VERSION ""

NS_ :

BS_:

BU_: SOBDMB_AWDC BCMC_CPDB BECMB_EPM PACM GWM _delete BCM ACCM DCDC_HEV GENERIC TSTR

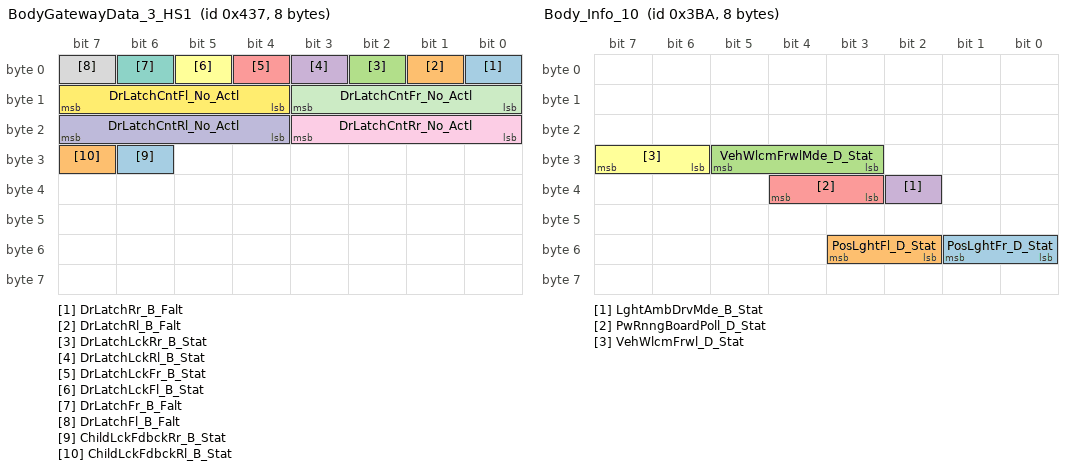
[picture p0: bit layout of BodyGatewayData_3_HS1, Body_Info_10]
BO_ 1079 BodyGatewayData_3_HS1: 8 GWM
 SG_ DrLatchRr_B_Falt : 0|1@0+ (1,0) [0|1] "SED"  BCM
 SG_ DrLatchRl_B_Falt : 1|1@0+ (1,0) [0|1] "SED"  BCM
 SG_ DrLatchLckRr_B_Stat : 2|1@0+ (1,0) [0|1] "SED"  BCM
 SG_ DrLatchLckRl_B_Stat : 3|1@0+ (1,0) [0|1] "SED"  BCM
 SG_ DrLatchLckFr_B_Stat : 4|1@0+ (1,0) [0|1] "SED"  BCM
 SG_ DrLatchLckFl_B_Stat : 5|1@0+ (1,0) [0|1] "SED"  BCM
 SG_ DrLatchFr_B_Falt : 6|1@0+ (1,0) [0|1] "SED"  BCM
 SG_ DrLatchFl_B_Falt : 7|1@0+ (1,0) [0|1] "SED"  BCM
 SG_ DrLatchCntRr_No_Actl : 19|4@0+ (1,0) [0|15] "unitless"  BCM
 SG_ DrLatchCntRl_No_Actl : 23|4@0+ (1,0) [0|15] "unitless"  BCM
 SG_ DrLatchCntFr_No_Actl : 11|4@0+ (1,0) [0|15] "unitless"  BCM
 SG_ DrLatchCntFl_No_Actl : 15|4@0+ (1,0) [0|15] "unitless"  BCM
 SG_ ChildLckFdbckRr_B_Stat : 30|1@0+ (1,0) [0|1] "SED"  BCM
 SG_ ChildLckFdbckRl_B_Stat : 31|1@0+ (1,0) [0|1] "SED"  BCM

BO_ 954 Body_Info_10: 8 BCM
 SG_ PosLghtFr_D_Stat : 49|2@0+ (1,0) [0|3] "SED"  GWM
 SG_ PosLghtFl_D_Stat : 51|2@0+ (1,0) [0|3] "SED"  GWM
 SG_ VehWlcmFrwlMde_D_Stat : 29|3@0+ (1,0) [0|7] "SED"  GWM
 SG_ LghtAmbDrvMde_B_Stat : 34|1@0+ (1,0) [0|1] "SED"  GWM
 SG_ PwRnngBoardPoll_D_Stat : 36|2@0+ (1,0) [0|3] "SED"  GWM
 SG_ VehWlcmFrwl_D_Stat : 31|2@0+ (1,0) [0|3] "SED"  GWM

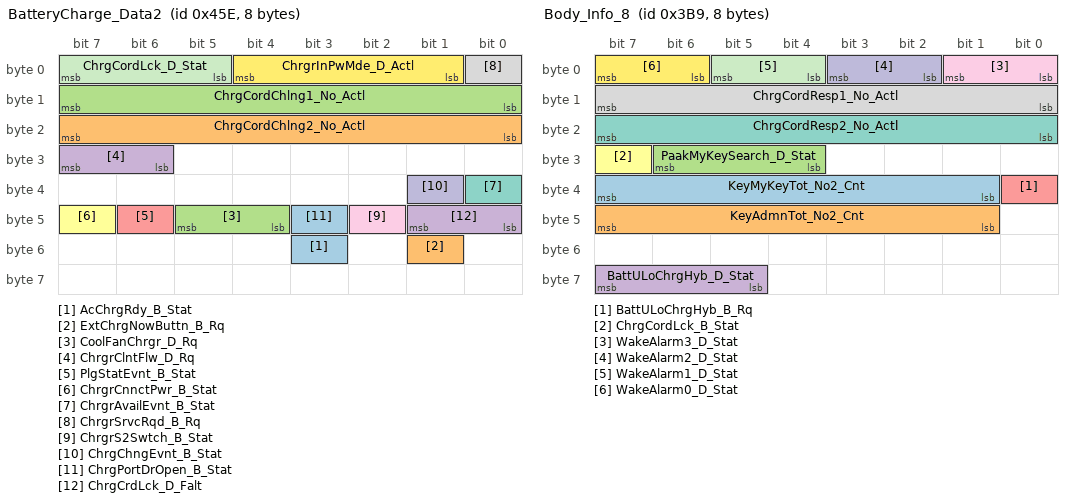
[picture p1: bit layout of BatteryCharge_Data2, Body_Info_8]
BO_ 1118 BatteryCharge_Data2: 8 GWM
 SG_ AcChrgRdy_B_Stat : 51|1@0+ (1,0) [0|1] "SED" Vector__XXX
 SG_ ExtChrgNowButtn_B_Rq : 49|1@0+ (1,0) [0|1] "SED" Vector__XXX
 SG_ CoolFanChrgr_D_Rq : 45|2@0+ (1,0) [0|3] "SED" Vector__XXX
 SG_ ChrgrClntFlw_D_Rq : 31|2@0+ (1,0) [0|3] "SED"  SOBDMB_AWDC
 SG_ PlgStatEvnt_B_Stat : 46|1@0+ (1,0) [0|1] "SED"  DCDC_HEV
 SG_ ChrgrCnnctPwr_B_Stat : 47|1@0+ (1,0) [0|1] "SED" Vector__XXX
 SG_ ChrgrAvailEvnt_B_Stat : 32|1@0+ (1,0) [0|1] "SED"  DCDC_HEV
 SG_ ChrgrSrvcRqd_B_Rq : 0|1@0+ (1,0) [0|1] "SED" Vector__XXX
 SG_ ChrgrS2Swtch_B_Stat : 42|1@0+ (1,0) [0|1] "SED" Vector__XXX
 SG_ ChrgChngEvnt_B_Stat : 33|1@0+ (1,0) [0|1] "SED"  DCDC_HEV
 SG_ ChrgCordLck_D_Stat : 7|3@0+ (1,0) [0|7] "SED" Vector__XXX
 SG_ ChrgrInPwMde_D_Actl : 4|4@0+ (1,0) [0|15] "SED" Vector__XXX
 SG_ ChrgPortDrOpen_B_Stat : 43|1@0+ (1,0) [0|1] "SED" Vector__XXX
 SG_ ChrgCordChlng2_No_Actl : 23|8@0+ (1,0) [0|255] "unitless"  BCM
 SG_ ChrgCordChlng1_No_Actl : 15|8@0+ (1,0) [0|255] "unitless"  BCM
 SG_ ChrgCrdLck_D_Falt : 41|2@0+ (1,0) [0|3] "SED" Vector__XXX

BO_ 953 Body_Info_8: 8 BCM
 SG_ KeyMyKeyTot_No2_Cnt : 39|7@0+ (1,0) [0|127] "unitless"  GWM
 SG_ KeyAdmnTot_No2_Cnt : 47|7@0+ (1,0) [0|127] "unitless"  GWM
 SG_ PaakMyKeySearch_D_Stat : 30|3@0+ (1,0) [0|7] "SED"  GWM
 SG_ BattULoChrgHyb_D_Stat : 63|3@0+ (1,0) [0|7] "SED"  GWM
 SG_ BattULoChrgHyb_B_Rq : 32|1@0+ (1,0) [0|1] "SED"  GWM
 SG_ ChrgCordLck_B_Stat : 31|1@0+ (1,0) [0|1] "SED"  GWM
 SG_ ChrgCordResp2_No_Actl : 23|8@0+ (1,0) [0|255] "unitless"  GWM
 SG_ ChrgCordResp1_No_Actl : 15|8@0+ (1,0) [0|255] "unitless"  GWM
 SG_ WakeAlarm3_D_Stat : 1|2@0+ (1,0) [0|3] "SED"  GWM,GENERIC
 SG_ WakeAlarm2_D_Stat : 3|2@0+ (1,0) [0|3] "SED"  GWM,GENERIC
 SG_ WakeAlarm1_D_Stat : 5|2@0+ (1,0) [0|3] "SED"  GWM,GENERIC
 SG_ WakeAlarm0_D_Stat : 7|2@0+ (1,0) [0|3] "SED"  GWM

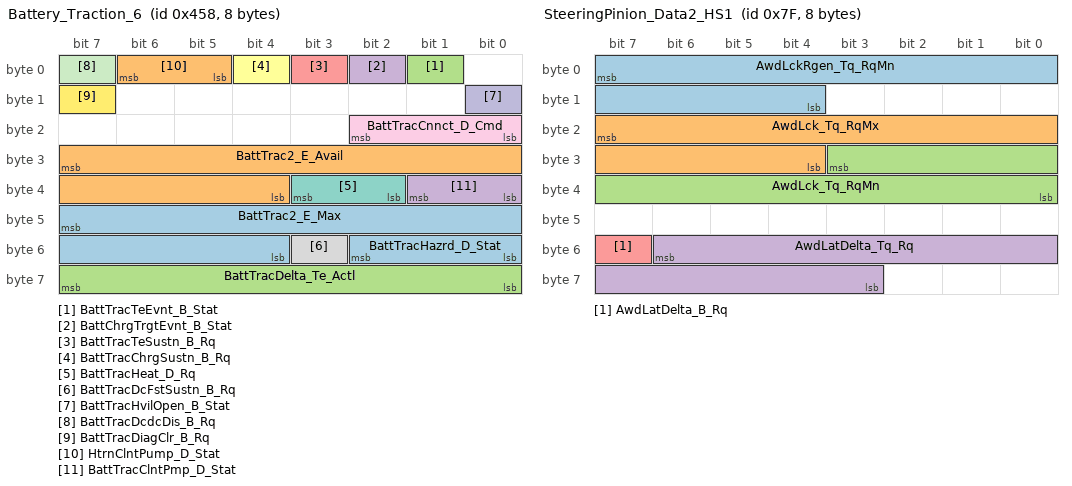
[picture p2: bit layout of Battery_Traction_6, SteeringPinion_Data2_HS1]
BO_ 1112 Battery_Traction_6: 8 GWM
 SG_ BattTrac2_E_Max : 47|12@0+ (50,0) [0|204650] "watt*hour" Vector__XXX
 SG_ BattTrac2_E_Avail : 31|12@0+ (50,0) [0|204650] "watt*hour" Vector__XXX
 SG_ BattTracTeEvnt_B_Stat : 1|1@0+ (1,0) [0|1] "SED"  DCDC_HEV
 SG_ BattChrgTrgtEvnt_B_Stat : 2|1@0+ (1,0) [0|1] "SED"  DCDC_HEV
 SG_ BattTracTeSustn_B_Rq : 3|1@0+ (1,0) [0|1] "SED"  BCM
 SG_ BattTracChrgSustn_B_Rq : 4|1@0+ (1,0) [0|1] "SED"  DCDC_HEV,BCMC_CPDB,BCM
 SG_ BattTracHeat_D_Rq : 35|2@0+ (1,0) [0|3] "SED" Vector__XXX
 SG_ BattTracDcFstSustn_B_Rq : 51|1@0+ (1,0) [0|1] "SED" Vector__XXX
 SG_ BattTracCnnct_D_Cmd : 18|3@0+ (1,0) [0|7] "SED"  SOBDMB_AWDC
 SG_ BattTracHvilOpen_B_Stat : 8|1@0+ (1,0) [0|1] "SED" Vector__XXX
 SG_ BattTracDcdcDis_B_Rq : 7|1@0+ (1,0) [0|1] "SED" Vector__XXX
 SG_ BattTracDiagClr_B_Rq : 15|1@0+ (1,0) [0|1] "SED" Vector__XXX
 SG_ BattTracHazrd_D_Stat : 50|3@0+ (1,0) [0|7] "SED" Vector__XXX
 SG_ HtrnClntPump_D_Stat : 6|2@0+ (1,0) [0|3] "SED"  DCDC_HEV
 SG_ BattTracDelta_Te_Actl : 63|8@0+ (0.5,-60) [-60|66.5] "degC" Vector__XXX
 SG_ BattTracClntPmp_D_Stat : 33|2@0+ (1,0) [0|3] "SED" Vector__XXX

BO_ 1144 MHT_EV_Wakeup: 8 GWM
 SG_ AwdLckMde_D_Stat : 59|3@0+ (1,0) [0|7] "SED" Vector__XXX
 SG_ BattTracCool_B_Actl : 60|1@0+ (1,0) [0|1] "SED"  GENERIC
 SG_ BattChrgTrgtSoC_D_Rq : 35|3@0+ (1,0) [0|7] "Percent" Vector__XXX
 SG_ PreCondBatt_B_Actl : 32|1@0+ (1,0) [0|1] "SED" Vector__XXX
 SG_ CabnEvapSovFront_B_Rq : 38|1@0+ (1,0) [0|1] "SED"  BCMC_CPDB
 SG_ HeatCoreSovRear_B_Rq : 36|1@0+ (1,0) [0|1] "SED" Vector__XXX
 SG_ BattChlrSov_B_Rq : 39|1@0+ (1,0) [0|1] "SED"  BCMC_CPDB
 SG_ CabnEvapSovRear_B_Rq : 37|1@0+ (1,0) [0|1] "SED" Vector__XXX
 SG_ BrkAppl_D_RqPt : 25|2@0+ (1,0) [0|3] "SED" Vector__XXX
 SG_ BattClntVlvOvrrd_D_Rq : 31|2@0+ (1,0) [0|3] "SED" Vector__XXX
 SG_ BattTracChillerOn_B_Rq : 27|1@0+ (1,0) [0|1] "SED" Vector__XXX
 SG_ BattTracChiller_D_Stat : 29|2@0+ (1,0) [0|3] "SED" Vector__XXX
 SG_ FstChrgCmplt_T_Est : 41|10@0+ (1,0) [0|1023] "minute" Vector__XXX
 SG_ ULoBattTrnsfrSustn_B_Rq : 43|1@0+ (1,0) [0|1] "SED"  BCM,DCDC_HEV
 SG_ ULoBattTransfer_D_Stat : 46|3@0+ (1,0) [0|7] "SED"  BCM
 SG_ HtrnDcdcDis_B_Rq : 26|1@0+ (1,0) [0|1] "SED" Vector__XXX
 SG_ HtrnCnnctPwr_B_Stat : 16|1@0+ (1,0) [0|1] "SED" Vector__XXX
 SG_ PtcHtr_D_Stat : 18|2@0+ (1,0) [0|3] "SED" Vector__XXX
 SG_ BattChrgInhbt_D2_Rq : 63|3@0+ (1,0) [0|7] "SED" Vector__XXX
 SG_ WakeAlarm0_B_Typ : 21|1@0+ (1,0) [0|1] "SED"  BCM
 SG_ WakeAlarm0_T_Rq : 7|15@0+ (1,0) [0|32767] "minute"  BCM
 SG_ BattTracClimtDis_B_Stat : 42|1@0+ (1,0) [0|1] "SED"  GENERIC
 SG_ HtrnClntFlw_D_Rq : 20|2@0+ (1,0) [0|3] "SED"  SOBDMB_AWDC
 SG_ BattTracDrvSustn_B_Rq : 8|1@0+ (1,0) [0|1] "SED"  BCMC_CPDB,BCM,DCDC_HEV
 SG_ CabinDrvSustn_B_Rq : 23|1@0+ (1,0) [0|1] "SED"  BCMC_CPDB,BCM,DCDC_HEV
 SG_ BattTracClntVlv_B_Rq : 47|1@0+ (1,0) [0|1] "SED"  BCMC_CPDB
 SG_ ChrgNowEvnt_B_Stat : 22|1@0+ (1,0) [0|1] "SED"  DCDC_HEV

BO_ 127 SteeringPinion_Data2_HS1: 8 GWM
 SG_ AwdLckRgen_Tq_RqMn : 7|12@0+ (1,-4095) [-4095|0] "Nm"  SOBDMB_AWDC,GENERIC
 SG_ AwdLck_Tq_RqMx : 23|12@0+ (1,0) [0|4095] "Nm"  SOBDMB_AWDC
 SG_ AwdLck_Tq_RqMn : 27|12@0+ (1,0) [0|4095] "Nm"  SOBDMB_AWDC
 SG_ AwdLatDelta_Tq_Rq : 54|12@0+ (2,-4095) [-4095|4095] "Nm"  GENERIC
 SG_ AwdLatDelta_B_Rq : 55|1@0+ (1,0) [0|1] "SED"  GENERIC

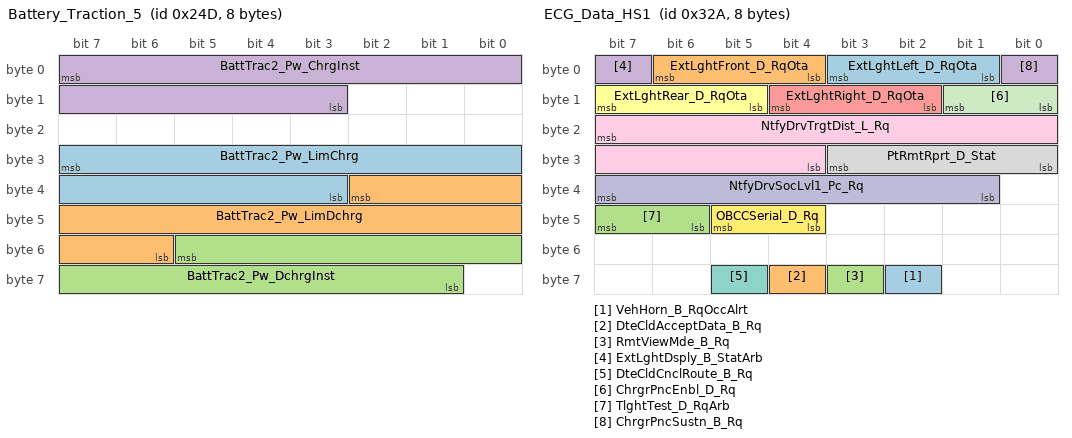
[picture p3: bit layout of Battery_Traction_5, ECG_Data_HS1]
BO_ 589 Battery_Traction_5: 8 GWM
 SG_ BattTrac2_Pw_LimChrg : 31|13@0+ (50,0) [0|409550] "watts" Vector__XXX
 SG_ BattTrac2_Pw_LimDchrg : 34|13@0+ (50,0) [0|409550] "watts" Vector__XXX
 SG_ BattTrac2_Pw_DchrgInst : 53|13@0+ (50,0) [0|409550] "watts" Vector__XXX
 SG_ BattTrac2_Pw_ChrgInst : 7|13@0+ (50,0) [0|409550] "watts" Vector__XXX

BO_ 968 Cluster_Lighting_Rq_HS1: 8 GWM
 SG_ LnchCtl_N_Rq : 55|8@0+ (50,0) [0|12750] "rpm" Vector__XXX
 SG_ LnchCtl_D_Rq : 63|2@0+ (1,0) [0|3] "SED" Vector__XXX
 SG_ CurrentColor_CmdGage : 43|4@0+ (1,0) [0|15] "SED" Vector__XXX
 SG_ BlendedColor_CmdGage : 25|2@0+ (1,0) [0|3] "SED" Vector__XXX
 SG_ BlendColorRed_CmdGage : 47|4@0+ (1,0) [0|15] "SED" Vector__XXX
 SG_ BlendColorGrn_CmdGage : 35|4@0+ (1,0) [0|15] "SED" Vector__XXX
 SG_ BlendColorBlue_CmdGage : 39|4@0+ (1,0) [0|15] "SED" Vector__XXX
 SG_ BrkDrvMde_D_Rq : 18|3@0+ (1,0) [0|7] "SED"  GENERIC
 SG_ Dimming_Level_Cmd : 1|2@0+ (1,0) [0|3] "SED"  GENERIC
 SG_ Current_Color_Cmd : 23|4@0+ (1,0) [0|15] "SED"  GENERIC
 SG_ BlendedColorRed_Cmd : 11|4@0+ (1,0) [0|15] "SED"  GENERIC
 SG_ BlendedColorGreen_Cmd : 15|4@0+ (1,0) [0|15] "SED"  GENERIC
 SG_ BlendedColorBlue_Cmd : 5|4@0+ (1,0) [0|15] "SED"  GENERIC
 SG_ BlendedColor_Cmd : 7|2@0+ (1,0) [0|3] "SED"  GENERIC
 SG_ SlMde_D_Rq : 27|2@0+ (1,0) [0|3] "SED" Vector__XXX
 SG_ IsaOffst_D_Rq : 31|4@0+ (1,0) [0|15] "SED" Vector__XXX
 SG_ SuspDrvMde_D_Rq : 61|3@0+ (1,0) [0|7] "SED"  GENERIC

BO_ 1081 GatewayData7_HS1: 8 GWM
 SG_ ChirpRq_No_ActlTrlr_UB : 35|1@0+ (1,0) [0|1] "SED"  BCM
 SG_ ChirpRq_No_ActlTrlr : 39|4@0+ (1,0) [0|15] "unitless"  BCM
 SG_ Chirp_D_RqTrlr_UB : 24|1@0+ (1,0) [0|1] "SED"  BCM
 SG_ Chirp_D_RqTrlr : 26|2@0+ (1,0) [0|3] "SED"  BCM
 SG_ RearPassWindowPos_UB : 8|1@0+ (1,0) [0|1] "SED"  BCM
 SG_ RearPassWindowPos : 11|3@0+ (1,0) [0|7] "SED"  BCM
 SG_ RearDriverWindowPos_UB : 12|1@0+ (1,0) [0|1] "SED"  BCM
 SG_ RearDriverWindowPos : 15|3@0+ (1,0) [0|7] "SED"  BCM
 SG_ PassWindowPosition_UB : 0|1@0+ (1,0) [0|1] "SED"  BCM
 SG_ PassWindowPosition : 3|3@0+ (1,0) [0|7] "SED"  BCM
 SG_ DriverWindowPosition_UB : 4|1@0+ (1,0) [0|1] "SED"  BCM
 SG_ DriverWindowPosition : 7|3@0+ (1,0) [0|7] "SED"  BCM
 SG_ ChrgCrdLckEnbl_B_Stat : 21|1@0+ (1,0) [0|1] "SED" Vector__XXX
 SG_ ChrgCrdLckEnbl_B_Stat_UB : 23|1@0+ (1,0) [0|1] "SED" Vector__XXX
 SG_ EcoInhbt_B_RqHvac_UB : 30|1@0+ (1,0) [0|1] "SED"  BCM
 SG_ EmgcyAsstActv_D_Stat_UB : 61|1@0+ (1,0) [0|1] "SED"  BCM
 SG_ EmgcyAsstActv_D_Stat : 63|2@0+ (1,0) [0|3] "SED"  BCM
 SG_ TrlrHitchLamp_D_Rq2_UB : 46|1@0+ (1,0) [0|1] "SED"  BCM
 SG_ TrlrHitchLamp_D_Rq2 : 47|1@0+ (1,0) [0|1] "SED"  BCM
 SG_ EcoInhbt_B_RqHvac : 31|1@0+ (1,0) [0|1] "SED"  BCM

BO_ 910 CloudVehCtlData_Tp_Rq: 8 GWM
 SG_ CloudVehCtlData_Tp_Rq : 7|64@0+ (1,0) [0|1.84467440737096E+019] "unitless"  BCM

BO_ 911 CloudVehCtlData_Tp_Res: 8 BCM
 SG_ CloudVehCtlData_Tp_Res : 7|64@0+ (1,0) [0|1.84467440737096E+019] "unitless"  GWM

BO_ 2609989848 OTAPhysGWM_ECGtoBCM: 8 GWM
 SG_ OTAPhysGWM_ECGtoBCM : 7|29@0+ (1,0) [0|536870911] "unitless"  BCM

BO_ 2610126930 OTAPhysBCMtoGWM_ECG: 8 BCM
 SG_ OTAPhysBCMtoGWM_ECG : 7|29@0+ (1,0) [0|536870911] "unitless"  GWM

BO_ 2612224062 PARSEDPushPACMtoGWM_ECG: 8 PACM
 SG_ PARSEDPushPACMtoGWM_ECG : 7|29@0+ (1,0) [0|536870911] "unitless"  GWM

BO_ 2611175486 PARSEDPhysPACMtoGWM_ECG: 8 PACM
 SG_ PARSEDPhysPACMtoGWM_ECG : 7|29@0+ (1,0) [0|536870911] "unitless"  GWM

BO_ 2611017944 PARSEDPhysGWM_ECGtoPACM: 8 GWM
 SG_ PARSEDPhysGWM_ECGtoPACM : 7|29@0+ (1,0) [0|536870911] "unitless"  PACM

BO_ 2612002008 PARSEDFuncGWM_ECG_HS1: 8 GWM
 SG_ PARSEDFuncGWM_ECG : 7|29@0+ (1,0) [0|536870911] "unitless"  SOBDMB_AWDC,PACM

BO_ 2610953432 OTAFuncGWM_ECG_HS1: 8 GWM
 SG_ OTAFuncGWM_ECG : 7|29@0+ (1,0) [0|536870911] "unitless"  SOBDMB_AWDC,BCM,PACM

BO_ 2609969368 OTAPhysGWM_ECGtoPACM: 8 GWM
 SG_ OTAPhysGWM_ECGtoPACM : 7|29@0+ (1,0) [0|536870911] "unitless"  PACM

BO_ 2610126910 OTAPhysPACMtoGWM_ECG: 8 PACM
 SG_ OTAPhysPACMtoGWM_ECG : 7|29@0+ (1,0) [0|536870911] "unitless"  GWM

BO_ 811 APIM_Data_HS1: 8 GWM
 SG_ ExtLghtRight_D_RqMnu : 11|3@0+ (1,0) [0|7] "SED" Vector__XXX
 SG_ ExtLghtRear_D_RqMnu : 14|3@0+ (1,0) [0|7] "SED" Vector__XXX
 SG_ ExtLghtLeft_D_RqMnu : 1|3@0+ (1,0) [0|7] "SED" Vector__XXX
 SG_ ExtLghtFront_D_RqMnu : 4|3@0+ (1,0) [0|7] "SED" Vector__XXX
 SG_ SpeedoMajorUnit_D_Confg : 59|2@0+ (1,0) [0|3] "SED"  GENERIC
 SG_ ScMnSoc_Pc_RqMnu : 55|7@0+ (1,0) [0|125] "percent"  GENERIC
 SG_ ScEnbl_D_RqMnu : 57|2@0+ (1,0) [0|3] "SED"  GENERIC
 SG_ OnePdlDrvButtn_B_Falt : 16|1@0+ (1,0) [0|1] "SED"  GENERIC
 SG_ ExtLghtDsply_D_Stat : 7|3@0+ (1,0) [0|7] "SED"  GENERIC
 SG_ OnePdlDrvButtn_B_Stat : 48|1@0+ (1,0) [0|1] "SED"  GENERIC
 SG_ LongTermReset_B_RqMnu : 17|1@0+ (1,0) [0|1] "SED"  GENERIC
 SG_ GoTEditMnte_T_RqMnu : 63|4@0+ (1,0) [0|15] "SED"  GENERIC
 SG_ GoTEditHr_T_RqMnu : 44|5@0+ (1,0) [0|29] "SED"  GENERIC
 SG_ DistToStopover_L_Actl : 31|16@0+ (0.1,0) [0|6553.4] "kilometer"  GENERIC
 SG_ StopoverType_D_Stat : 47|3@0+ (1,0) [0|0] "SED"  GENERIC
 SG_ AutoLghtOvrrd_B_RqDrv : 8|1@0+ (1,0) [0|1] "SED" Vector__XXX
 SG_ BecRleas_No_RqMnu : 23|3@0+ (1,0) [0|7] "unitless"  BCM
 SG_ TrnkFrontRleas_No_RqMnu : 20|3@0+ (1,0) [0|7] "unitless"  BCM

BO_ 810 ECG_Data_HS1: 8 GWM
 SG_ VehHorn_B_RqOccAlrt : 58|1@0+ (1,0) [0|1] "SED"  BCM
 SG_ DteCldAcceptData_B_Rq : 60|1@0+ (1,0) [0|1] "SED"  GENERIC
 SG_ RmtViewMde_B_Rq : 59|1@0+ (1,0) [0|1] "SED" Vector__XXX
 SG_ ExtLghtDsply_B_StatArb : 7|1@0+ (1,0) [0|1] "SED" Vector__XXX
 SG_ ExtLghtRight_D_RqOta : 12|3@0+ (1,0) [0|7] "SED" Vector__XXX
 SG_ ExtLghtRear_D_RqOta : 15|3@0+ (1,0) [0|7] "SED" Vector__XXX
 SG_ DteCldCnclRoute_B_Rq : 61|1@0+ (1,0) [0|1] "SED"  GENERIC
 SG_ PtRmtRprt_D_Stat : 27|4@0+ (1,0) [0|15] "SED"  GENERIC
 SG_ NtfyDrvTrgtDist_L_Rq : 23|12@0+ (0.1,0) [0|409.5] "Km"  GENERIC
 SG_ NtfyDrvSocLvl1_Pc_Rq : 39|7@0+ (1,0) [0|127] "%"  GENERIC
 SG_ ChrgrPncEnbl_D_Rq : 9|2@0+ (1,0) [0|3] "SED" Vector__XXX
 SG_ OBCCSerial_D_Rq : 45|2@0+ (1,0) [0|3] "SED" Vector__XXX
 SG_ ExtLghtLeft_D_RqOta : 3|3@0+ (1,0) [0|7] "SED" Vector__XXX
 SG_ ExtLghtFront_D_RqOta : 6|3@0+ (1,0) [0|7] "SED" Vector__XXX
 SG_ TlghtTest_D_RqArb : 47|2@0+ (1,0) [0|3] "SED" Vector__XXX
 SG_ ChrgrPncSustn_B_Rq : 0|1@0+ (1,0) [0|1] "SED" Vector__XXX

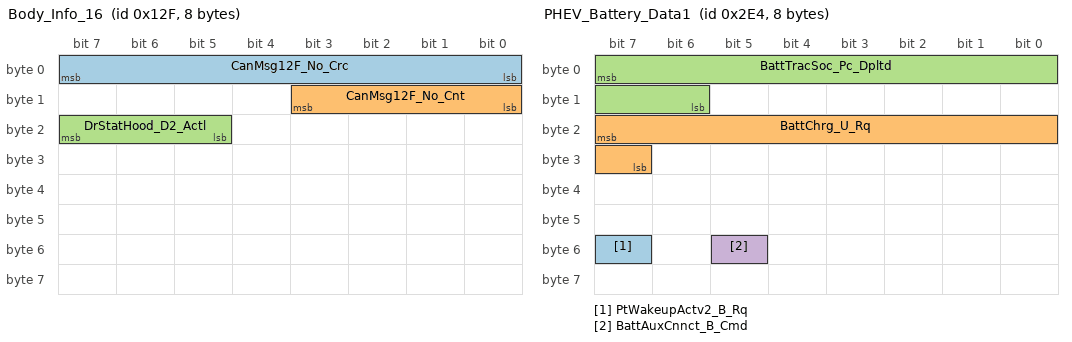
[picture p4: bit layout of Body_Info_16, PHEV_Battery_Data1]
BO_ 303 Body_Info_16: 8 BCM
 SG_ CanMsg12F_No_Crc : 7|8@0+ (1,0) [0|255] "Unitless"  GWM
 SG_ CanMsg12F_No_Cnt : 11|4@0+ (1,0) [0|15] "Unitless"  GWM
 SG_ DrStatHood_D2_Actl : 23|3@0+ (1,0) [0|7] "SED"  GWM

BO_ 1082 GatewayData3_HS1: 8 GWM
 SG_ VdmSustnActv_B_Rq_UB : 8|1@0+ (1,0) [0|1] "SED" Vector__XXX
 SG_ VdmSustnActv_B_Rq : 9|1@0+ (1,0) [0|1] "SED" Vector__XXX
 SG_ ChrgStatDsply_D_Rq_UB : 48|1@0+ (1,0) [0|1] "SED" Vector__XXX
 SG_ ChrgStatDsply_D_Rq : 63|2@0+ (1,0) [0|3] "SED" Vector__XXX
 SG_ ChrgCordUnlock_B_Rq_UB : 39|1@0+ (1,0) [0|1] "SED" Vector__XXX
 SG_ ChrgCordUnlock_B_Rq : 24|1@0+ (1,0) [0|1] "SED" Vector__XXX
 SG_ FldngSeatPwOffOk_B_Stat_UB : 47|1@0+ (1,0) [0|1] "SED" Vector__XXX
 SG_ FldngSeatPwOffOk_B_Stat : 32|1@0+ (1,0) [0|1] "SED" Vector__XXX
 SG_ EngAirFilt_B_RqReset_UB : 33|1@0+ (1,0) [0|1] "SED" Vector__XXX
 SG_ EngAirFilt_B_RqReset : 34|1@0+ (1,0) [0|1] "SED" Vector__XXX
 SG_ TrailCtl_D_Stat_UB : 49|1@0+ (1,0) [0|1] "SED" Vector__XXX
 SG_ TrailCtl_D_Stat : 52|3@0+ (1,0) [0|7] "SED" Vector__XXX
 SG_ DrLckActv_B_RqBalrr_UB : 53|1@0+ (1,0) [0|1] "SED" Vector__XXX
 SG_ DrLckActv_B_RqBalrl_UB : 54|1@0+ (1,0) [0|1] "SED" Vector__XXX
 SG_ DrLckCnt_No_ActlBalrr : 42|3@0+ (1,0) [0|7] "unitless" Vector__XXX
 SG_ DrLckCnt_No_ActlBalrl : 45|3@0+ (1,0) [0|7] "unitless" Vector__XXX
 SG_ DrLckActv_B_RqBalrr : 55|1@0+ (1,0) [0|1] "SED" Vector__XXX
 SG_ DrLckActv_B_RqBalrl : 46|1@0+ (1,0) [0|1] "SED" Vector__XXX
 SG_ EmgcyCall_D_Stat : 38|3@0+ (1,0) [0|7] "SED"  BCM
 SG_ EmgcyCall_D_Stat_UB : 35|1@0+ (1,0) [0|1] "SED"  BCM
 SG_ EmPrflNo_D_Rq_UB : 10|1@0+ (1,0) [0|1] "SED"  BCM
 SG_ EmPrflKeyAssoc_D_Rq_UB : 11|1@0+ (1,0) [0|1] "SED"  BCM
 SG_ EmPrflNo_D_Rq : 2|3@0+ (1,0) [0|7] "SED"  BCM
 SG_ EmPrflKeyAssoc_D_Rq : 5|3@0+ (1,0) [0|7] "SED"  BCM
 SG_ CamraViewSplit_B_Rq_UB : 6|1@0+ (1,0) [0|1] "SED"  BCM
 SG_ HMI_HMIMode_St : 15|3@0+ (1,0) [0|7] "SED"  BCM
 SG_ CamraViewSplit_B_Rq : 7|1@0+ (1,0) [0|1] "SED"  BCM
 SG_ HMI_HMIMode_St_UB : 12|1@0+ (1,0) [0|1] "SED"  BCM

BO_ 902 BodyGatewayData_HS1: 8 GWM
 SG_ PrmtrAlrmWarnRq_No_Actl_UB : 40|1@0+ (1,0) [0|1] "SED"  BCM
 SG_ PrmtrAlrmTrgRq_No_Actl_UB : 41|1@0+ (1,0) [0|1] "SED"  BCM
 SG_ PrmtrAlrmWarnRq_No_Actl : 63|8@0+ (1,0) [0|255] "unitless"  BCM
 SG_ PrmtrAlrmTrgRq_No_Actl : 55|8@0+ (1,0) [0|255] "unitless"  BCM
 SG_ PrmtrAlrmWarn_B_Rq_UB : 42|1@0+ (1,0) [0|1] "SED"  BCM
 SG_ RollCode_No_ActlRsm_UB : 43|1@0+ (1,0) [0|1] "SED"  BCM
 SG_ PrmtrAlrmTrg_B_Rq_UB : 46|1@0+ (1,0) [0|1] "SED"  BCM
 SG_ PanicRq_No_ActlRsm_UB : 44|1@0+ (1,0) [0|1] "SED"  BCM
 SG_ Panic_D_RqRsm_UB : 0|1@0+ (1,0) [0|1] "SED"  BCM
 SG_ CellLockRq_No_ActlRsm_UB : 45|1@0+ (1,0) [0|1] "SED"  BCM
 SG_ RollCode_No_ActlRsm : 31|16@0+ (1,0) [0|65535] "unitless"  BCM
 SG_ PrmtrAlrmWarn_B_Rq : 47|1@0+ (1,0) [0|1] "SED"  BCM
 SG_ PrmtrAlrmTrg_B_Rq : 2|1@0+ (1,0) [0|1] "SED"  BCM
 SG_ PanicRq_No_ActlRsm : 23|8@0+ (1,0) [0|255] "unitless"  BCM
 SG_ Panic_D_RqRsm : 4|2@0+ (1,0) [0|3] "SED"  BCM
 SG_ CellLockRq_No_ActlRsm : 15|8@0+ (1,0) [0|255] "unitless"  BCM
 SG_ CellLock_D_RqRsm : 7|3@0+ (1,0) [0|7] "SED"  BCM
 SG_ CellLock_D_RqRsm_UB : 1|1@0+ (1,0) [0|1] "SED"  BCM

BO_ 740 PHEV_Battery_Data1: 8 GWM
 SG_ PtWakeupActv2_B_Rq : 55|1@0+ (1,0) [0|1] "SED"  BCM
 SG_ BattChrg_U_Rq : 23|9@0+ (1,0) [0|511] "volt" Vector__XXX
 SG_ BattTracSoc_Pc_Dpltd : 7|10@0+ (0.1,0) [0|102.3] "percent" Vector__XXX
 SG_ BattAuxCnnct_B_Cmd : 53|1@0+ (1,0) [0|1] "SED"  DCDC_HEV

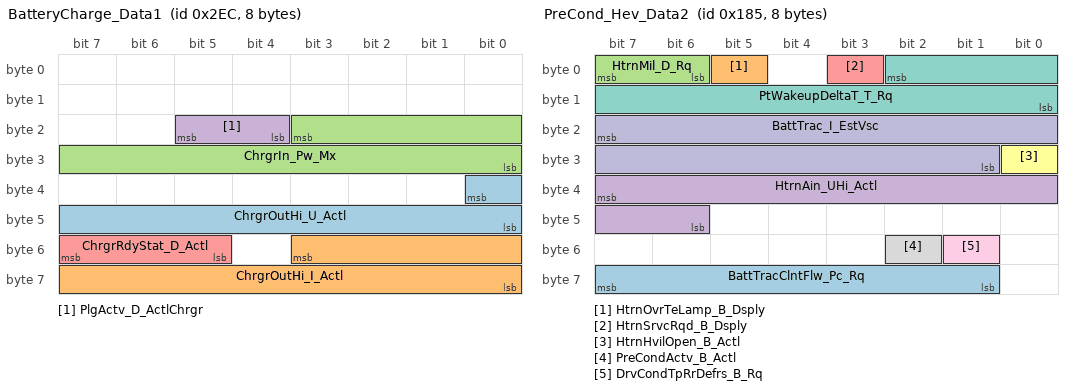
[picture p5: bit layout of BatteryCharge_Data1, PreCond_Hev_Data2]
BO_ 748 BatteryCharge_Data1: 8 GWM
 SG_ ChrgrOutHi_U_Actl : 32|9@0+ (1,0) [0|510] "volt" Vector__XXX
 SG_ ChrgrOutHi_I_Actl : 51|12@0+ (0.1,0) [0|409.4] "ampere" Vector__XXX
 SG_ ChrgrIn_Pw_Mx : 19|12@0+ (50,0) [0|204700] "watts" Vector__XXX
 SG_ PlgActv_D_ActlChrgr : 21|2@0+ (1,0) [0|3] "SED" Vector__XXX
 SG_ ChrgrRdyStat_D_Actl : 55|3@0+ (1,0) [0|7] "SED" Vector__XXX

BO_ 389 PreCond_Hev_Data2: 8 GWM
 SG_ BattTracClntFlw_Pc_Rq : 63|7@0+ (1,0) [0|127] "percent" Vector__XXX
 SG_ HtrnOvrTeLamp_B_Dsply : 5|1@0+ (1,0) [0|1] "SED" Vector__XXX
 SG_ HtrnMil_D_Rq : 7|2@0+ (1,0) [0|3] "SED" Vector__XXX
 SG_ HtrnAin_UHi_Actl : 39|10@0+ (0.5,0) [0|510.5] "volt"  DCDC_HEV
 SG_ HtrnSrvcRqd_B_Dsply : 3|1@0+ (1,0) [0|1] "SED" Vector__XXX
 SG_ HtrnHvilOpen_B_Actl : 24|1@0+ (1,0) [0|1] "SED" Vector__XXX
 SG_ PtWakeupDeltaT_T_Rq : 2|11@0+ (1,0) [0|2045] "minute" Vector__XXX
 SG_ PreCondActv_B_Actl : 50|1@0+ (1,0) [0|1] "SED"  BCM
 SG_ DrvCondTpRrDefrs_B_Rq : 49|1@0+ (1,0) [0|1] "SED" Vector__XXX
 SG_ BattTrac_I_EstVsc : 23|15@0+ (0.05,-750) [-750|888.25] "Amps" Vector__XXX

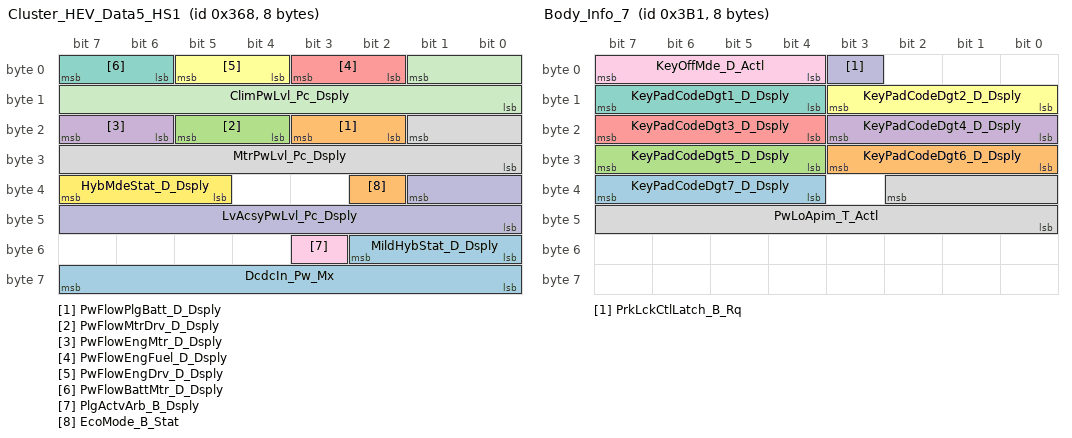
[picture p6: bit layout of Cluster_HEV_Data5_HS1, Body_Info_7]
BO_ 872 Cluster_HEV_Data5_HS1: 8 GWM
 SG_ DcdcIn_Pw_Mx : 63|8@0+ (20,1000) [1000|6100] "watts" Vector__XXX
 SG_ PwFlowPlgBatt_D_Dsply : 19|2@0+ (1,0) [0|3] "SED"  GENERIC
 SG_ PwFlowMtrDrv_D_Dsply : 21|2@0+ (1,0) [0|3] "SED"  GENERIC
 SG_ PwFlowEngMtr_D_Dsply : 23|2@0+ (1,0) [0|3] "SED"  GENERIC
 SG_ PwFlowEngFuel_D_Dsply : 3|2@0+ (1,0) [0|3] "SED"  GENERIC
 SG_ PwFlowEngDrv_D_Dsply : 5|2@0+ (1,0) [0|3] "SED"  GENERIC
 SG_ PwFlowBattMtr_D_Dsply : 7|2@0+ (1,0) [0|3] "SED"  GENERIC
 SG_ MtrPwLvl_Pc_Dsply : 17|10@0+ (0.2,-102.2) [-102.2|102.4] "percent"  GENERIC
 SG_ PlgActvArb_B_Dsply : 51|1@0+ (1,0) [0|1] "SED"  GENERIC
 SG_ LvAcsyPwLvl_Pc_Dsply : 33|10@0+ (0.1,0) [0|102.3] "percent"  GENERIC
 SG_ ClimPwLvl_Pc_Dsply : 1|10@0+ (0.1,0) [0|102.3] "percent"  GENERIC
 SG_ HybMdeStat_D_Dsply : 39|3@0+ (1,0) [0|7] "SED"  GENERIC
 SG_ MildHybStat_D_Dsply : 50|3@0+ (1,0) [0|7] "SED"  GENERIC
 SG_ EcoMode_B_Stat : 34|1@0+ (1,0) [0|1] "SED"  GENERIC

BO_ 945 Body_Info_7: 8 BCM
 SG_ KeyPadCodeDgt7_D_Dsply : 39|4@0+ (1,0) [0|15] "SED"  GWM
 SG_ KeyPadCodeDgt6_D_Dsply : 27|4@0+ (1,0) [0|15] "SED"  GWM
 SG_ KeyPadCodeDgt5_D_Dsply : 31|4@0+ (1,0) [0|15] "SED"  GWM
 SG_ KeyPadCodeDgt4_D_Dsply : 19|4@0+ (1,0) [0|15] "SED"  GWM
 SG_ KeyPadCodeDgt3_D_Dsply : 23|4@0+ (1,0) [0|15] "SED"  GWM
 SG_ KeyPadCodeDgt2_D_Dsply : 11|4@0+ (1,0) [0|15] "SED"  GWM
 SG_ KeyPadCodeDgt1_D_Dsply : 15|4@0+ (1,0) [0|15] "SED"  GWM
 SG_ PwLoApim_T_Actl : 34|11@0+ (1,0) [0|2047] "minute"  GWM
 SG_ KeyOffMde_D_Actl : 7|4@0+ (1,0) [0|15] "SED"  GWM
 SG_ PrkLckCtlLatch_B_Rq : 3|1@0+ (1,0) [0|1] "SED"  GWM

BO_ 985 IPMA_Data2_HS1: 8 GWM
 SG_ AdbDrvSide_B_Stat : 35|1@0+ (1,0) [0|1] "SED"  GENERIC
 SG_ LcwaMsgTxt_D_Stat : 37|2@0+ (1,0) [0|3] "SED"  GENERIC
 SG_ PwSustnAdas_B_Rq : 48|1@0+ (1,0) [0|1] "SED" Vector__XXX
 SG_ AdbDividedRoad_B_Stat : 30|1@0+ (1,0) [0|1] "SED"  GENERIC
 SG_ LcwaAlrtRight_B_Rq : 38|1@0+ (1,0) [0|1] "SED"  GENERIC
 SG_ LcwaAlrtLeft_B_Rq : 39|1@0+ (1,0) [0|1] "SED"  GENERIC
 SG_ SblmPedCrossScnr_B_Stat : 33|1@0+ (1,0) [0|1] "SED"  GENERIC
 SG_ TsrRegionTxt_D_Stat : 47|5@0+ (1,0) [0|31] "SED"  GENERIC
 SG_ SblmYieldScnr_B_Stat : 31|1@0+ (1,0) [0|1] "SED"  GENERIC
 SG_ SblmStopScnr_B_Stat : 8|1@0+ (1,0) [0|1] "SED"  GENERIC
 SG_ AdbRampingV_D_Rq : 25|2@0+ (1,0) [0|3] "SED"  GENERIC
 SG_ AdbLampOnOff_D_Rq : 27|2@0+ (1,0) [0|3] "SED"  GENERIC
 SG_ AdbHiBeamKeepOff_D_Rq : 29|2@0+ (1,0) [0|3] "SED"  GENERIC
 SG_ IaccVLimUnit_D_Rq : 11|2@0+ (1,0) [0|3] "SED" Vector__XXX
 SG_ IaccVLim_D_Rq : 23|8@0+ (1,0) [0|255] "SED" Vector__XXX
 SG_ IsaVLimUnit_D_Rq : 15|2@0+ (1,0) [0|3] "SED" Vector__XXX
 SG_ IsaVLim_D_Rq : 7|8@0+ (1,0) [0|255] "SED" Vector__XXX
 SG_ DasAlrtInfo_D_Dsply : 13|2@0+ (1,0) [0|3] "SED"  GENERIC
 SG_ LdwChime_B_Rq : 34|1@0+ (1,0) [0|1] "SED"  GENERIC
 SG_ SblmRndAbtScnr_B_Stat : 9|1@0+ (1,0) [0|1] "SED"  GENERIC

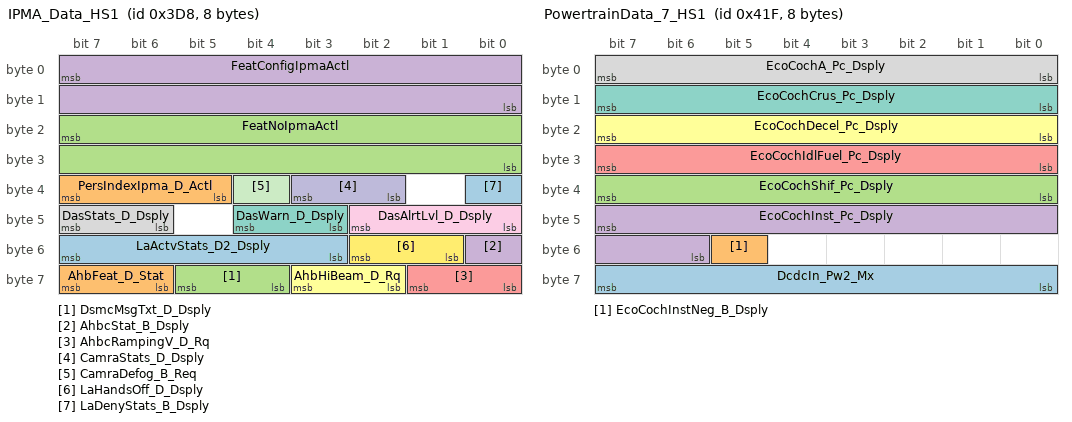
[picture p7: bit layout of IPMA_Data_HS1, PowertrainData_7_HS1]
BO_ 984 IPMA_Data_HS1: 8 GWM
 SG_ LaActvStats_D2_Dsply : 55|5@0+ (1,0) [0|31] "SED"  GENERIC
 SG_ AhbFeat_D_Stat : 63|2@0+ (1,0) [0|3] "SED"  GENERIC
 SG_ DsmcMsgTxt_D_Dsply : 61|2@0+ (1,0) [0|3] "SED"  GENERIC
 SG_ AhbcStat_B_Dsply : 48|1@0+ (1,0) [0|1] "SED"  GENERIC
 SG_ AhbcRampingV_D_Rq : 57|2@0+ (1,0) [0|3] "SED"  BCM
 SG_ AhbHiBeam_D_Rq : 59|2@0+ (1,0) [0|3] "SED"  GENERIC
 SG_ DasWarn_D_Dsply : 44|2@0+ (1,0) [0|3] "SED"  GENERIC
 SG_ DasStats_D_Dsply : 47|2@0+ (1,0) [0|3] "SED"  GENERIC
 SG_ DasAlrtLvl_D_Dsply : 42|3@0+ (1,0) [0|7] "SED"  GENERIC
 SG_ CamraStats_D_Dsply : 35|2@0+ (1,0) [0|3] "SED"  GENERIC
 SG_ CamraDefog_B_Req : 36|1@0+ (1,0) [0|1] "SED" Vector__XXX
 SG_ LaHandsOff_D_Dsply : 50|2@0+ (1,0) [0|3] "SED"  GENERIC
 SG_ LaDenyStats_B_Dsply : 32|1@0+ (1,0) [0|1] "SED"  GENERIC
 SG_ PersIndexIpma_D_Actl : 39|3@0+ (1,0) [0|7] "SED"  GENERIC
 SG_ FeatNoIpmaActl : 23|16@0+ (1,0) [0|65535] "Number"  GENERIC
 SG_ FeatConfigIpmaActl : 7|16@0+ (1,0) [0|65535] "Undefined"  GENERIC

BO_ 1055 PowertrainData_7_HS1: 8 GWM
 SG_ DcdcIn_Pw2_Mx : 63|8@0+ (20,500) [500|5600] "watts" Vector__XXX
 SG_ EcoCochInstNeg_B_Dsply : 53|1@0+ (1,0) [0|1] "SED" Vector__XXX
 SG_ EcoCochShif_Pc_Dsply : 39|8@0+ (0.392157,0) [0|100.000035] "percent" Vector__XXX
 SG_ EcoCochInst_Pc_Dsply : 47|10@0+ (0.1,0) [0|102.3] "percent" Vector__XXX
 SG_ EcoCochIdlFuel_Pc_Dsply : 31|8@0+ (0.392157,0) [0|100.000035] "percent" Vector__XXX
 SG_ EcoCochDecel_Pc_Dsply : 23|8@0+ (0.392157,0) [0|100.000035] "percent" Vector__XXX
 SG_ EcoCochCrus_Pc_Dsply : 15|8@0+ (0.392157,0) [0|100.000035] "percent" Vector__XXX
 SG_ EcoCochA_Pc_Dsply : 7|8@0+ (0.392157,0) [0|100.000035] "percent" Vector__XXX

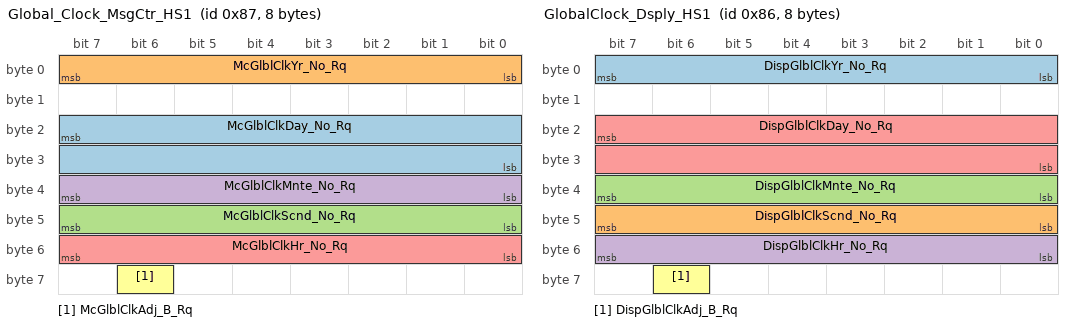
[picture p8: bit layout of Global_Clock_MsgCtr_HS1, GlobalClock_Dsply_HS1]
BO_ 135 Global_Clock_MsgCtr_HS1: 8 GWM
 SG_ McGlblClkDay_No_Rq : 23|16@0+ (1,0) [0|65535] "julian day"  BCM
 SG_ McGlblClkYr_No_Rq : 7|8@0+ (1,2000) [2000|2255] "year"  BCM
 SG_ McGlblClkScnd_No_Rq : 47|8@0+ (1,0) [0|255] "second"  BCM
 SG_ McGlblClkMnte_No_Rq : 39|8@0+ (1,0) [0|255] "minute"  BCM
 SG_ McGlblClkHr_No_Rq : 55|8@0+ (1,0) [0|255] "hour"  BCM
 SG_ McGlblClkAdj_B_Rq : 62|1@0+ (1,0) [0|1] "SED"  BCM

BO_ 134 GlobalClock_Dsply_HS1: 8 GWM
 SG_ DispGlblClkYr_No_Rq : 7|8@0+ (1,2000) [2000|2255] "year"  BCM
 SG_ DispGlblClkScnd_No_Rq : 47|8@0+ (1,0) [0|255] "second"  BCM
 SG_ DispGlblClkMnte_No_Rq : 39|8@0+ (1,0) [0|255] "minute"  BCM
 SG_ DispGlblClkHr_No_Rq : 55|8@0+ (1,0) [0|255] "hour"  BCM
 SG_ DispGlblClkDay_No_Rq : 23|16@0+ (1,0) [0|65535] "julian day"  BCM
 SG_ DispGlblClkAdj_B_Rq : 62|1@0+ (1,0) [0|1] "SED"  BCM

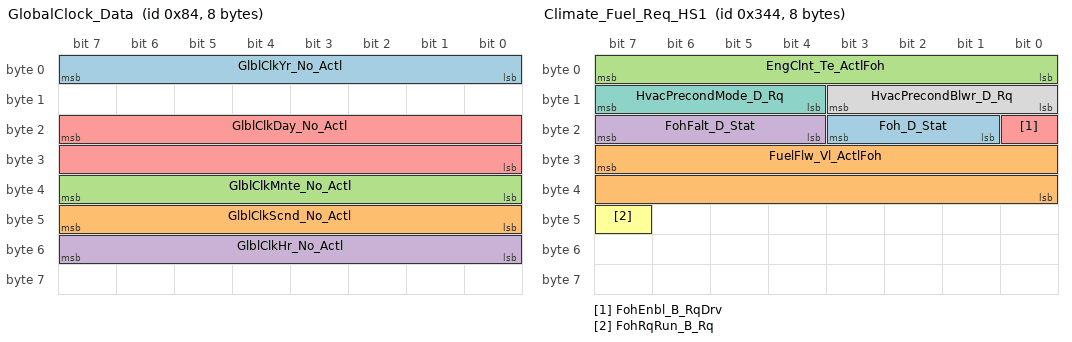
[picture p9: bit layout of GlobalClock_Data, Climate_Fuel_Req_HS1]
BO_ 132 GlobalClock_Data: 8 BCM
 SG_ GlblClkYr_No_Actl : 7|8@0+ (1,2000) [2000|2255] "year"  GWM
 SG_ GlblClkScnd_No_Actl : 47|8@0+ (1,0) [0|255] "second"  GWM
 SG_ GlblClkMnte_No_Actl : 39|8@0+ (1,0) [0|255] "minute"  GWM
 SG_ GlblClkHr_No_Actl : 55|8@0+ (1,0) [0|255] "hour"  GWM
 SG_ GlblClkDay_No_Actl : 23|16@0+ (1,0) [0|65535] "julian day"  GWM

BO_ 836 Climate_Fuel_Req_HS1: 8 GWM
 SG_ Foh_D_Stat : 19|3@0+ (1,0) [0|7] "SED"  BCM
 SG_ FuelFlw_Vl_ActlFoh : 31|16@0+ (25,0) [0|1638375] "microlitre" Vector__XXX
 SG_ EngClnt_Te_ActlFoh : 7|8@0+ (1,-50) [-50|204] "degC" Vector__XXX
 SG_ FohFalt_D_Stat : 23|4@0+ (1,0) [0|15] "SED" Vector__XXX
 SG_ FohEnbl_B_RqDrv : 16|1@0+ (1,0) [0|1] "SED" Vector__XXX
 SG_ FohRqRun_B_Rq : 47|1@0+ (1,0) [0|1] "SED" Vector__XXX
 SG_ HvacPrecondMode_D_Rq : 15|4@0+ (1,0) [0|15] "SED"  GENERIC
 SG_ HvacPrecondBlwr_D_Rq : 11|4@0+ (1,0) [0|15] "SED"  GENERIC

BO_ 939 ParkAid_Aud_Warn_Stat2_HS1: 8 GWM
 SG_ PrkAidSnsRlSide_D_Stat : 23|4@0+ (1,0) [0|15] "SED"  BCM
 SG_ ApaBrk_D_Rq : 51|2@0+ (1,0) [0|3] "SED"  GENERIC
 SG_ SidePrkSnsR4_D_Stat : 55|4@0+ (1,0) [0|15] "SED"  GENERIC
 SG_ SidePrkSnsR3_D_Stat : 47|4@0+ (1,0) [0|15] "SED"  GENERIC
 SG_ SidePrkSnsL4_D_Stat : 43|4@0+ (1,0) [0|15] "SED"  GENERIC
 SG_ SidePrkSnsL3_D_Stat : 37|4@0+ (1,0) [0|15] "SED"  GENERIC
 SG_ PrkAidSnsRrSide_D_Stat : 27|4@0+ (1,0) [0|15] "SED"  BCM
 SG_ PrkAidChime_D_Stat : 4|2@0+ (1,0) [0|3] "SED"  GENERIC
 SG_ PrkAidSnsRlCntr_D_Stat : 15|4@0+ (1,0) [0|15] "SED"  BCM
 SG_ PrkAidSnsRrCrnr_D_Stat : 31|4@0+ (1,0) [0|15] "SED"  BCM
 SG_ PrkAidSnsRrCntr_D_Stat : 19|4@0+ (1,0) [0|15] "SED"  BCM
 SG_ PrkAidSnsRlCrnr_D_Stat : 11|4@0+ (1,0) [0|15] "SED"  BCM
 SG_ PrkAidRear_D_Stat : 39|2@0+ (1,0) [0|3] "SED"  GENERIC
 SG_ PrkAidFront_D_Stat : 2|2@0+ (1,0) [0|3] "SED"  GENERIC
 SG_ PrkAid_D_Falt : 7|3@0+ (1,0) [0|7] "SED"  BCM
 SG_ ApaLongCtrlEnbl_D_Rq : 0|1@0+ (1,0) [0|1] "SED" Vector__XXX
 SG_ ApaBrk_A_Rq : 63|8@0+ (0.05,-12.75) [-12.75|0] "m/sec^2" Vector__XXX
 SG_ PrkAidLamp_D_Rq : 33|2@0+ (1,0) [0|3] "SED"  GENERIC

BO_ 952 Tire_Pressure_Data_DRW: 8 BCM
 SG_ Tire_Press_IRR_Data : 23|16@0+ (1,0) [0|65533] "kilopascal"  GWM
 SG_ Tire_Press_ILR_Data : 7|16@0+ (1,0) [0|65533] "kilopascal"  GWM

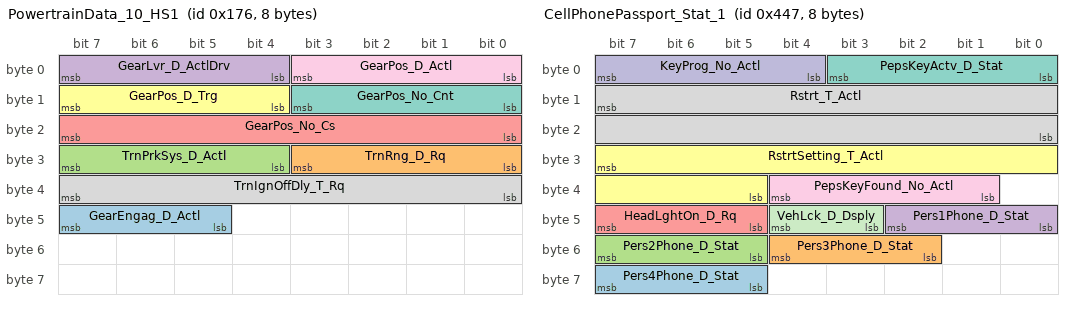
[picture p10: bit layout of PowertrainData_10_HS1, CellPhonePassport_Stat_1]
BO_ 374 PowertrainData_10_HS1: 8 GWM
 SG_ GearEngag_D_Actl : 47|3@0+ (1,0) [0|7] "SED"  GENERIC
 SG_ TrnRng_D_Rq : 27|4@0+ (1,0) [0|15] "SED"  SOBDMB_AWDC
 SG_ TrnPrkSys_D_Actl : 31|4@0+ (1,0) [0|15] "SED"  SOBDMB_AWDC,BCM
 SG_ GearLvr_D_ActlDrv : 7|4@0+ (1,0) [0|15] "SED"  SOBDMB_AWDC
 SG_ GearPos_No_Cs : 23|8@0+ (1,0) [0|255] "unitless"  SOBDMB_AWDC
 SG_ GearPos_D_Trg : 15|4@0+ (1,0) [0|15] "SED"  SOBDMB_AWDC
 SG_ GearPos_No_Cnt : 11|4@0+ (1,0) [0|15] "unitless"  SOBDMB_AWDC
 SG_ TrnIgnOffDly_T_Rq : 39|8@0+ (4,0) [0|1020] "ms"  BCM
 SG_ GearPos_D_Actl : 3|4@0+ (1,0) [0|15] "SED"  SOBDMB_AWDC

BO_ 1095 CellPhonePassport_Stat_1: 8 BCM
 SG_ Pers4Phone_D_Stat : 63|3@0+ (1,0) [0|7] "SED"  GWM
 SG_ Pers3Phone_D_Stat : 52|3@0+ (1,0) [0|7] "SED"  GWM
 SG_ Pers2Phone_D_Stat : 55|3@0+ (1,0) [0|7] "SED"  GWM
 SG_ Pers1Phone_D_Stat : 42|3@0+ (1,0) [0|7] "SED"  GWM
 SG_ HeadLghtOn_D_Rq : 47|3@0+ (1,0) [0|7] "SED"  GWM
 SG_ RstrtSetting_T_Actl : 31|11@0+ (1,0) [0|2047] "second"  GWM
 SG_ PepsKeyActv_D_Stat : 3|4@0+ (1,0) [0|15] "SED"  GWM
 SG_ Rstrt_T_Actl : 15|16@0+ (1,0) [0|65535] "seconds"  GWM
 SG_ PepsKeyFound_No_Actl : 36|4@0+ (1,0) [0|15] "unitless"  GWM
 SG_ KeyProg_No_Actl : 7|4@0+ (1,0) [0|15] "unitless"  GWM
 SG_ VehLck_D_Dsply : 44|2@0+ (1,0) [0|3] "SED"  GWM

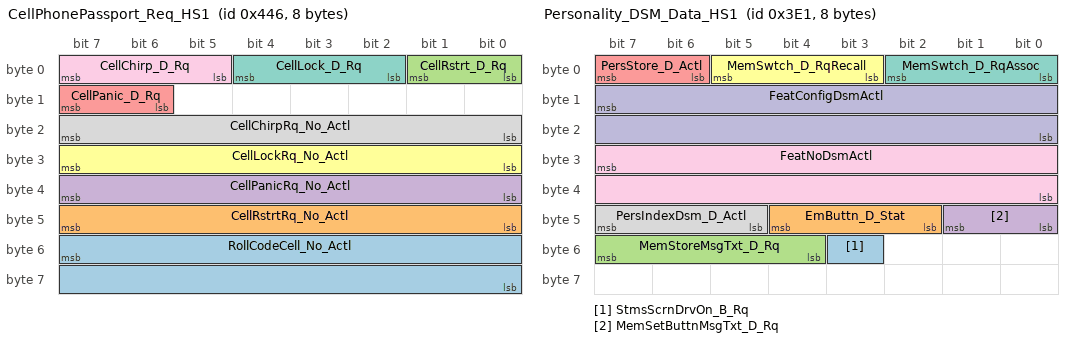
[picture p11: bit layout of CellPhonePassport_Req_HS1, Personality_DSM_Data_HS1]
BO_ 1094 CellPhonePassport_Req_HS1: 8 GWM
 SG_ RollCodeCell_No_Actl : 55|16@0+ (1,0) [0|65535] "unitless"  BCM
 SG_ CellRstrtRq_No_Actl : 47|8@0+ (1,0) [0|255] "unitless"  BCM
 SG_ CellRstrt_D_Rq : 1|2@0+ (1,0) [0|3] "SED"  BCM
 SG_ CellPanicRq_No_Actl : 39|8@0+ (1,0) [0|255] "unitless"  BCM
 SG_ CellPanic_D_Rq : 15|2@0+ (1,0) [0|3] "SED"  BCM
 SG_ CellLockRq_No_Actl : 31|8@0+ (1,0) [0|255] "unitless"  BCM
 SG_ CellLock_D_Rq : 4|3@0+ (1,0) [0|7] "SED"  BCM
 SG_ CellChirpRq_No_Actl : 23|8@0+ (1,0) [0|255] "unitless"  BCM
 SG_ CellChirp_D_Rq : 7|3@0+ (1,0) [0|7] "SED"  BCM

BO_ 1100 PowertrainData_9_HS1: 8 GWM
 SG_ RearDiffLckLamp_D_Rq2 : 21|2@0+ (1,0) [0|3] "SED" Vector__XXX
 SG_ RvltnMatchAllw_D_Stat : 41|2@0+ (1,0) [0|3] "SED" Vector__XXX
 SG_ WakeAlarm1_T_Rq : 55|15@0+ (1,0) [0|32767] "minute"  BCM
 SG_ WakeAlarm1_B_Typ : 56|1@0+ (1,0) [0|1] "SED"  BCM
 SG_ TrnNtrlIdlExit_B_Rq : 38|1@0+ (1,0) [0|1] "SED" Vector__XXX
 SG_ HvacCmprLim_D_Stat : 34|3@0+ (1,0) [0|7] "SED"  GENERIC
 SG_ Veh_V_DsplyTrailCtlSet : 47|6@0+ (0.5,0) [0|31] "unitless" Vector__XXX
 SG_ TrailCtlPt_B_Falt : 36|2@0+ (1,0) [0|3] "SED" Vector__XXX
 SG_ TrnNtrlIdlInhbt_B_Rq : 37|1@0+ (1,0) [0|1] "SED" Vector__XXX
 SG_ AutoTowAllw_D_StatMnu : 25|2@0+ (1,0) [0|3] "SED" Vector__XXX
 SG_ AutoTowActv_B_Stat : 39|1@0+ (1,0) [0|1] "SED" Vector__XXX
 SG_ SpareTireDetct_B_Stat : 30|1@0+ (1,0) [0|1] "SED" Vector__XXX
 SG_ RearDiffSumpOil_Te_Est : 15|8@0+ (1,-40) [-40|213] "degC" Vector__XXX
 SG_ RearDiffMtrRun_B_Stat : 31|1@0+ (1,0) [0|1] "SED" Vector__XXX
 SG_ EngTrlrCnnct_D_Stat : 23|2@0+ (1,0) [0|3] "SED" Vector__XXX
 SG_ GrossTrainWeight_M_Est : 7|8@0+ (100,0) [0|25300] "kilogram" Vector__XXX
 SG_ SuspVlimMsgTxt_B_Rq : 29|1@0+ (1,0) [0|1] "SED" Vector__XXX
 SG_ RearDiffLckMsg2_D_Rq : 19|4@0+ (1,0) [0|15] "SED" Vector__XXX
 SG_ EngExhMdeQuiet_D2_Stat : 28|3@0+ (1,0) [0|7] "SED" Vector__XXX

BO_ 993 Personality_DSM_Data_HS1: 8 GWM
 SG_ StmsScrnDrvOn_B_Rq : 51|1@0+ (1,0) [0|1] "SED" Vector__XXX
 SG_ EmButtn_D_Stat : 44|3@0+ (1,0) [0|7] "SED"  GENERIC
 SG_ MemStoreMsgTxt_D_Rq : 55|4@0+ (1,0) [0|15] "SED"  GENERIC
 SG_ MemSetButtnMsgTxt_D_Rq : 41|2@0+ (1,0) [0|3] "SED"  GENERIC
 SG_ PersStore_D_Actl : 7|2@0+ (1,0) [0|3] "SED"  GENERIC
 SG_ MemSwtch_D_RqRecall : 5|3@0+ (1,0) [0|7] "SED"  BCM
 SG_ MemSwtch_D_RqAssoc : 2|3@0+ (1,0) [0|7] "SED"  BCM
 SG_ PersIndexDsm_D_Actl : 47|3@0+ (1,0) [0|7] "SED"  GENERIC
 SG_ FeatNoDsmActl : 31|16@0+ (1,0) [0|65535] "Number"  GENERIC
 SG_ FeatConfigDsmActl : 15|16@0+ (1,0) [0|65535] "Undefined"  GENERIC

BO_ 131 Steering_Data_HS1: 8 GWM
 SG_ AhbStat_B_Dsply : 33|1@0+ (1,0) [0|1] "SED"  GENERIC
 SG_ HeadLghtHiOn_B_StatAhb : 34|1@0+ (1,0) [0|1] "SED"  GENERIC
 SG_ WiprFrontSwtch_D_Stat : 47|4@0+ (1,0) [0|15] "SED"  GENERIC
 SG_ HeadLghtHiCtrl_D_RqAhb : 43|3@0+ (1,0) [0|7] "SED"  BCM
 SG_ HeadLghtHiFlash_D_Actl : 36|2@0+ (1,0) [0|3] "SED"  GENERIC
 SG_ AccButtnGapTogglePress : 32|1@0+ (1,0) [0|1] "SED"  GENERIC
 SG_ TjaButtnOnOffPress : 40|1@0+ (1,0) [0|1] "SED"  GENERIC
 SG_ AccButtnGapIncPress : 11|1@0+ (1,0) [0|1] "SED"  GENERIC
 SG_ AccButtnGapDecPress : 12|1@0+ (1,0) [0|1] "SED"  GENERIC
 SG_ AslButtnOnOffPress : 9|1@0+ (1,0) [0|1] "SED"  GENERIC
 SG_ AslButtnOnOffCnclPress : 10|1@0+ (1,0) [0|1] "SED"  GENERIC
 SG_ CcButtnOnPress : 37|1@0+ (1,0) [0|1] "SED"  GENERIC
 SG_ CcButtnOnOffPress : 38|1@0+ (1,0) [0|1] "SED"  GENERIC
 SG_ CcButtnOnOffCnclPress : 39|1@0+ (1,0) [0|1] "SED"  GENERIC
 SG_ CcButtnOffPress : 24|1@0+ (1,0) [0|1] "SED"  GENERIC
 SG_ CcAsllButtnResPress : 25|1@0+ (1,0) [0|1] "SED"  GENERIC
 SG_ CcAslButtnSetPress : 26|1@0+ (1,0) [0|1] "SED"  GENERIC
 SG_ CcAslButtnSetIncPress : 27|1@0+ (1,0) [0|1] "SED"  GENERIC
 SG_ CcAslButtnSetDecPress : 28|1@0+ (1,0) [0|1] "SED"  GENERIC
 SG_ CcAslButtnResIncPress : 29|1@0+ (1,0) [0|1] "SED"  GENERIC
 SG_ CcAslButtnResDecPress : 30|1@0+ (1,0) [0|1] "SED"  GENERIC
 SG_ CcAslButtnOnPress : 31|1@0+ (1,0) [0|1] "SED"  GENERIC
 SG_ CcAslButtnOnOffCncl : 16|1@0+ (1,0) [0|1] "SED"  GENERIC
 SG_ CcAslButtnOffCnclPress : 17|1@0+ (1,0) [0|1] "SED"  GENERIC
 SG_ CcAslButtnIndxIncPress : 18|1@0+ (1,0) [0|1] "SED"  GENERIC
 SG_ CcAslButtnIndxDecPress : 19|1@0+ (1,0) [0|1] "SED"  GENERIC
 SG_ CcAslButtnDeny_B_Actl : 20|1@0+ (1,0) [0|1] "SED"  GENERIC
 SG_ CcAslButtnCnclResPress : 21|1@0+ (1,0) [0|1] "SED"  GENERIC
 SG_ CcAslButtnCnclPress : 8|1@0+ (1,0) [0|1] "SED"  GENERIC
 SG_ HeadLghtHiFlash_D_Stat : 7|2@0+ (1,0) [0|3] "SED"  BCM
 SG_ WiprFront_D_Stat : 3|4@0+ (1,0) [0|15] "SED"  BCM
 SG_ TurnLghtSwtch_D_Stat : 5|2@0+ (1,0) [0|3] "SED"  BCM
 SG_ LghtAmb_D_Sns : 15|3@0+ (1,0) [0|7] "SED"  BCM
 SG_ LaSwtchPos_D_Stat : 23|2@0+ (1,0) [0|3] "SED"  GENERIC

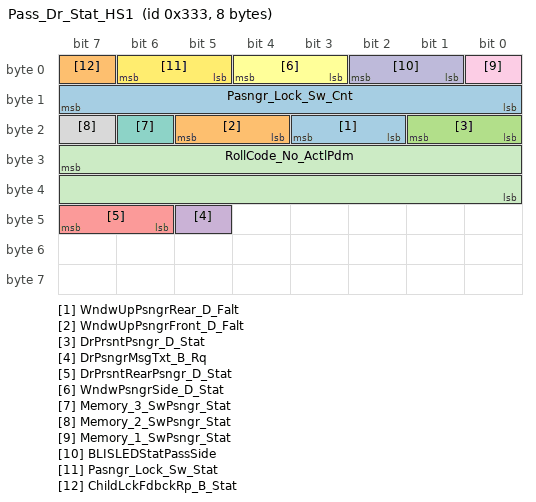
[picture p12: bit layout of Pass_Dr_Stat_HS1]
BO_ 819 Pass_Dr_Stat_HS1: 8 GWM
 SG_ WndwUpPsngrRear_D_Falt : 19|2@0+ (1,0) [0|3] "SED"  GENERIC
 SG_ WndwUpPsngrFront_D_Falt : 21|2@0+ (1,0) [0|3] "SED"  GENERIC
 SG_ DrPrsntPsngr_D_Stat : 17|2@0+ (1,0) [0|3] "SED" Vector__XXX
 SG_ DrPsngrMsgTxt_B_Rq : 45|1@0+ (1,0) [0|1] "SED"  GENERIC
 SG_ DrPrsntRearPsngr_D_Stat : 47|2@0+ (1,0) [0|3] "SED" Vector__XXX
 SG_ WndwPsngrSide_D_Stat : 4|2@0+ (1,0) [0|3] "SED"  GENERIC
 SG_ Memory_3_SwPsngr_Stat : 22|1@0+ (1,0) [0|1] "SED"  GENERIC
 SG_ Memory_2_SwPsngr_Stat : 23|1@0+ (1,0) [0|1] "SED"  GENERIC
 SG_ Memory_1_SwPsngr_Stat : 0|1@0+ (1,0) [0|1] "SED"  GENERIC
 SG_ BLISLEDStatPassSide : 2|2@0+ (1,0) [0|3] "SED"  GENERIC
 SG_ RollCode_No_ActlPdm : 31|16@0+ (1,0) [0|65535] "Unitless"  BCM
 SG_ Pasngr_Lock_Sw_Stat : 6|2@0+ (1,0) [0|3] "SED"  BCM
 SG_ Pasngr_Lock_Sw_Cnt : 15|8@0+ (1,0) [0|255] "Cnt"  BCM
 SG_ ChildLckFdbckRp_B_Stat : 7|1@0+ (1,0) [0|1] "SED"  BCM

CM_ BO_ 1079 "Rolling counts indicate fresh data (DrLatchCntFl, Fr, Rl, Rr_No_Actl) and are updated each time new data is sent from a latch to BCM thru the GW. UBs not required.";
CM_ SG_ 1079 DrLatchCntRr_No_Actl "Rolling counts indicate fresh data (DrLatchCntxx) are updated each time new data is sent from a latch to BCM thru the GW. UBs not required.";
CM_ SG_ 1079 DrLatchCntRl_No_Actl "Rolling counts indicate fresh data (DrLatchCntxx) are updated each time new data is sent from a latch to BCM thru the GW. UBs not required.";
CM_ SG_ 1079 DrLatchCntFr_No_Actl "Rolling counts indicate fresh data (DrLatchCntxx) are updated each time new data is sent from a latch to BCM thru the GW. UBs not required.";
CM_ SG_ 1079 DrLatchCntFl_No_Actl "Rolling counts indicate fresh data (DrLatchCntxx) are updated each time new data is sent from a latch to BCM thru the GW. UBs not required.";
CM_ SG_ 1112 BattTracClntPmp_D_Stat "48V mHEV: ECM_HEVDSL is Tx,  MHT HEV: PCM_HEV is Tx,  Powersplit HEV: SOBDMC_HPCM is Tx";
CM_ SG_ 910 CloudVehCtlData_Tp_Rq "MM ISO 15765-2 Message Catalogue RDISP2 - AUDIO";
CM_ SG_ 810 PtRmtRprt_D_Stat "Object.RemoteDataReport_St
";
CM_ SG_ 810 NtfyDrvTrgtDist_L_Rq "Object.SetTripRangeAlert_Rq
This signal is meant to provide the customer settings for the target distance remote notification";
CM_ SG_ 810 NtfyDrvSocLvl1_Pc_Rq "Object.SetCustomerLevelAlert_Rq
This signal is meant to provide the customer settings for the SOC remote notification.";
CM_ SG_ 1082 HMI_HMIMode_St "Object ACU System Master.HMIMode
OR
Object NAV System Master.HMIMode

Refer Method HMIAudioMode in the SPSS";
CM_ SG_ 836 Foh_D_Stat "Signal not transmitted on vehicles that do not have the Fuel operated heater feature.";
CM_ SG_ 836 FuelFlw_Vl_ActlFoh "Signal not transmitted on vehicles that do not have the Fuel operated heater feature.";
CM_ SG_ 836 EngClnt_Te_ActlFoh "Signal not transmitted on vehicles that do not have the Fuel operated heater feature.";
CM_ SG_ 836 FohFalt_D_Stat "Signal not transmitted on vehicles that do not have the Fuel operated heater feature.";
CM_ SG_ 836 FohEnbl_B_RqDrv "Signal not transmitted on vehicles that do not have the Fuel operated heater feature.";
CM_ SG_ 836 FohRqRun_B_Rq "Signal not transmitted on vehicles that do not have the Fuel operated heater feature.";
CM_ SG_ 836 HvacPrecondMode_D_Rq "Signal not transmitted on vehicles that do not have the Fuel operated heater feature.";
CM_ SG_ 836 HvacPrecondBlwr_D_Rq "Signal not transmitted on vehicles that do not have the Fuel operated heater feature.";
CM_ BO_ 374 "Programs w/o HS1 0x172 will need HS1 0x176 for GearPos_D_Actl.  Future MY Programs that choose c/o still require HS1 0x172. ";
CM_ SG_ 374 TrnRng_D_Rq "Powersplit HEVs with HF45, HPCM will Tx  this message.  For all other programs it will be Tx by PCM or TCM. ";
CM_ SG_ 374 TrnPrkSys_D_Actl "Powersplit HEVs with HF45, HPCM will Tx  this message.  For all other programs it will be Tx by PCM or TCM. ";
CM_ SG_ 374 GearLvr_D_ActlDrv "Powersplit HEVs with HF45, HPCM will Tx  this message.  For all other programs it will be Tx by PCM or TCM. ";
CM_ SG_ 374 GearPos_No_Cs "Powersplit HEVs with HF45, HPCM will Tx  this message.  For all other programs it will be Tx by PCM or TCM. ";
CM_ SG_ 374 GearPos_D_Trg "Powersplit HEVs with HF45, HPCM will Tx  this message.  For all other programs it will be Tx by PCM or TCM. ";
CM_ SG_ 374 GearPos_No_Cnt "Powersplit HEVs with HF45, HPCM will Tx  this message.  For all other programs it will be Tx by PCM or TCM. ";
CM_ SG_ 374 GearPos_D_Actl "Powersplit HEVs with HF45, HPCM will Tx  this message.  For all other programs it will be Tx by PCM or TCM. ";
BA_DEF_ BO_  "FrameRouting" STRING ;
BA_DEF_ BO_  "FrameGatewayNetwork" STRING ;
BA_DEF_ BO_  "NetworkInitialization" ENUM  "No","Yes";
BA_DEF_ BO_  "FrameGatewayId" HEX 0 1407;
BA_DEF_ BO_  "EventRateOfChange" INT 10 10000;
BA_DEF_ BO_  "GenMsgStartDelayTime" INT 0 10000;
BA_DEF_ BO_  "GenMsgNrOfRepetition" INT 0 100;
BA_DEF_ BO_  "GenMsgDelayTime" INT 0 1000;
BA_DEF_ BO_  "GenMsgCycleTime" INT 0 100000;
BA_DEF_ BO_  "GenMsgSendType" ENUM  "FixedPeriodic","Event","EnabledPeriodic","NotUsed","NotUsed","EventPeriodic","NotUsed","NotUsed","NoMsgSendType";
BA_DEF_ SG_  "U_CD764_MY2022_Tx" ENUM  "No","Yes";
BA_DEF_ SG_  "U_U55X_MY2022_Tx" ENUM  "No","Yes";
BA_DEF_ SG_  "U_CD542_MY2021_Tx" ENUM  "No","Yes";
BA_DEF_ SG_  "ECGUsedTxSignal" ENUM  "No","Yes";
BA_DEF_ SG_  "U_T6_MCA_MY2020_Tx" ENUM  "No","Yes";
BA_DEF_ SG_  "U_P702_MY2021_Tx" ENUM  "No","Yes";
BA_DEF_ SG_  "U_CX727_MY2021_Tx" ENUM  "No","Yes";
BA_DEF_ SG_  "U_CD764_MY2022_Rx" ENUM  "No","Yes";
BA_DEF_ SG_  "U_U55X_MY2022_Rx" ENUM  "No","Yes";
BA_DEF_ SG_  "U_CD542_MY2021_Rx" ENUM  "No","Yes";
BA_DEF_ SG_  "ECGUsedRxSignal" ENUM  "No","Yes";
BA_DEF_ SG_  "U_T6_MCA_MY2020_Rx" ENUM  "No","Yes";
BA_DEF_ SG_  "U_P702_MY2021_Rx" ENUM  "No","Yes";
BA_DEF_ SG_  "U_CX727_MY2021_Rx" ENUM  "No","Yes";
BA_DEF_ SG_  "GenSigStartValue" HEX 0 268435455;
BA_DEF_ SG_  "MetaData" ENUM  "No","Yes";
BA_DEF_ SG_  "ContentDependant" ENUM  "No","Yes";
BA_DEF_ SG_  "GenSigStartValueInteger" INT 0 1000000000;
BA_DEF_ SG_  "UsedOnPgmDBC" ENUM  "No","Yes";
BA_DEF_ SG_  "WakeupSignal" ENUM  "No","Yes";
BA_DEF_ SG_  "GenSigInactiveValue" INT 0 100000;
BA_DEF_ SG_  "GenSigSendType" ENUM  "Cyclic","OnWrite","vector_leerstring","OnChange","vector_leerstring","IfActive","vector_leerstring","NoSigSendType";
BA_DEF_ BO_  "OvtpPushApplication" ENUM  "FALSE","TRUE";
BA_DEF_ BO_  "SCP_FreshnessValueLength" INT 0 512;
BA_DEF_ BO_  "SCP_FreshnessValueTxLength" INT 0 512;
BA_DEF_ BO_  "SCP_AuthInfoTxLength" INT 0 512;
BA_DEF_ BO_  "GenMsgRoutingTimeoutTime" INT 0 5000;
BA_DEF_ BO_  "MessageGateway" ENUM  "No","Yes";
BA_DEF_ BO_  "NmAsrMessage" ENUM  "No","Yes";
BA_DEF_ BO_  "TpApplType" STRING ;
BA_DEF_ BO_  "DiagState" ENUM  "No","Yes";
BA_DEF_ BO_  "TpTxIndex" INT 0 536870911;
BA_DEF_ BO_  "DiagRequest" ENUM  "No","Yes";
BA_DEF_ BO_  "DiagResponse" ENUM  "No","Yes";
BA_DEF_ BO_  "GenMsgILSupport" ENUM  "No","Yes";
BA_DEF_DEF_  "FrameRouting" "";
BA_DEF_DEF_  "FrameGatewayNetwork" "NONE";
BA_DEF_DEF_  "NetworkInitialization" "Yes";
BA_DEF_DEF_  "FrameGatewayId" 0;
BA_DEF_DEF_  "EventRateOfChange" 10000;
BA_DEF_DEF_  "GenMsgStartDelayTime" 0;
BA_DEF_DEF_  "GenMsgNrOfRepetition" 1;
BA_DEF_DEF_  "GenMsgDelayTime" 20;
BA_DEF_DEF_  "GenMsgCycleTime" 0;
BA_DEF_DEF_  "GenMsgSendType" "NoMsgSendType";
BA_DEF_DEF_  "U_CD764_MY2022_Tx" "No";
BA_DEF_DEF_  "U_U55X_MY2022_Tx" "No";
BA_DEF_DEF_  "U_CD542_MY2021_Tx" "No";
BA_DEF_DEF_  "ECGUsedTxSignal" "No";
BA_DEF_DEF_  "U_T6_MCA_MY2020_Tx" "No";
BA_DEF_DEF_  "U_P702_MY2021_Tx" "No";
BA_DEF_DEF_  "U_CX727_MY2021_Tx" "No";
BA_DEF_DEF_  "U_CD764_MY2022_Rx" "No";
BA_DEF_DEF_  "U_U55X_MY2022_Rx" "No";
BA_DEF_DEF_  "U_CD542_MY2021_Rx" "No";
BA_DEF_DEF_  "ECGUsedRxSignal" "No";
BA_DEF_DEF_  "U_T6_MCA_MY2020_Rx" "No";
BA_DEF_DEF_  "U_P702_MY2021_Rx" "No";
BA_DEF_DEF_  "U_CX727_MY2021_Rx" "No";
BA_DEF_DEF_  "GenSigStartValue" 0;
BA_DEF_DEF_  "MetaData" "No";
BA_DEF_DEF_  "ContentDependant" "No";
BA_DEF_DEF_  "GenSigStartValueInteger" 0;
BA_DEF_DEF_  "UsedOnPgmDBC" "Yes";
BA_DEF_DEF_  "WakeupSignal" "No";
BA_DEF_DEF_  "GenSigInactiveValue" 0;
BA_DEF_DEF_  "GenSigSendType" "NoSigSendType";
BA_DEF_DEF_  "OvtpPushApplication" "FALSE";
BA_DEF_DEF_  "SCP_FreshnessValueLength" 64;
BA_DEF_DEF_  "SCP_FreshnessValueTxLength" 11;
BA_DEF_DEF_  "SCP_AuthInfoTxLength" 53;
BA_DEF_DEF_  "GenMsgRoutingTimeoutTime" 0;
BA_DEF_DEF_  "MessageGateway" "No";
BA_DEF_DEF_  "NmAsrMessage" "No";
BA_DEF_DEF_  "TpApplType" "";
BA_DEF_DEF_  "DiagState" "No";
BA_DEF_DEF_  "TpTxIndex" 0;
BA_DEF_DEF_  "DiagRequest" "No";
BA_DEF_DEF_  "DiagResponse" "No";
BA_DEF_DEF_  "GenMsgILSupport" "Yes";
BA_ "GenMsgSendType" BO_ 1079 0;
BA_ "GenMsgCycleTime" BO_ 1079 1000;
BA_ "GenMsgSendType" BO_ 954 5;
BA_ "GenMsgCycleTime" BO_ 954 1000;
BA_ "FrameGatewayId" BO_ 1118 1118;
BA_ "FrameRouting" BO_ 1118 "HS5_CAN,0x45E";
BA_ "FrameGatewayNetwork" BO_ 1118 "HS5_CAN";
BA_ "GenMsgSendType" BO_ 953 5;
BA_ "GenMsgCycleTime" BO_ 953 1000;
BA_ "FrameGatewayId" BO_ 1112 1112;
BA_ "FrameRouting" BO_ 1112 "HS5_CAN,0x458";
BA_ "FrameGatewayNetwork" BO_ 1112 "HS5_CAN";
BA_ "FrameGatewayId" BO_ 1144 1144;
BA_ "FrameGatewayNetwork" BO_ 1144 "FD1_CAN";
BA_ "FrameRouting" BO_ 1144 "FD1_CAN,0x478;";
BA_ "GenMsgDelayTime" BO_ 127 10;
BA_ "FrameGatewayId" BO_ 127 127;
BA_ "FrameGatewayNetwork" BO_ 127 "FD1_CAN";
BA_ "FrameRouting" BO_ 127 "FD1_CAN,0x7F;";
BA_ "FrameGatewayId" BO_ 589 589;
BA_ "FrameRouting" BO_ 589 "HS5_CAN,0x24D";
BA_ "FrameGatewayNetwork" BO_ 589 "HS5_CAN";
BA_ "FrameGatewayId" BO_ 968 968;
BA_ "FrameGatewayNetwork" BO_ 968 "HS3_CAN";
BA_ "FrameRouting" BO_ 968 "HS3_CAN,0x3C8;";
BA_ "GenMsgSendType" BO_ 1081 5;
BA_ "GenMsgCycleTime" BO_ 1081 1000;
BA_ "TpTxIndex" BO_ 910 161;
BA_ "GenMsgSendType" BO_ 910 1;
BA_ "TpTxIndex" BO_ 911 161;
BA_ "GenMsgSendType" BO_ 911 1;
BA_ "TpTxIndex" BO_ 2609989848 462506200;
BA_ "GenMsgSendType" BO_ 2609989848 1;
BA_ "GenMsgDelayTime" BO_ 2609989848 0;
BA_ "NetworkInitialization" BO_ 2609989848 0;
BA_ "TpTxIndex" BO_ 2610126930 462506200;
BA_ "GenMsgSendType" BO_ 2610126930 1;
BA_ "GenMsgDelayTime" BO_ 2610126930 0;
BA_ "NetworkInitialization" BO_ 2610126930 0;
BA_ "TpTxIndex" BO_ 2612224062 464582872;
BA_ "OvtpPushApplication" BO_ 2612224062 1;
BA_ "GenMsgSendType" BO_ 2612224062 1;
BA_ "GenMsgDelayTime" BO_ 2612224062 0;
BA_ "NetworkInitialization" BO_ 2612224062 0;
BA_ "TpTxIndex" BO_ 2611175486 463534296;
BA_ "GenMsgSendType" BO_ 2611175486 1;
BA_ "GenMsgDelayTime" BO_ 2611175486 0;
BA_ "NetworkInitialization" BO_ 2611175486 0;
BA_ "TpTxIndex" BO_ 2611017944 463534296;
BA_ "GenMsgSendType" BO_ 2611017944 1;
BA_ "GenMsgDelayTime" BO_ 2611017944 0;
BA_ "NetworkInitialization" BO_ 2611017944 0;
BA_ "TpTxIndex" BO_ 2612002008 464518360;
BA_ "GenMsgSendType" BO_ 2612002008 1;
BA_ "GenMsgDelayTime" BO_ 2612002008 0;
BA_ "NetworkInitialization" BO_ 2612002008 0;
BA_ "TpTxIndex" BO_ 2610953432 463469784;
BA_ "GenMsgSendType" BO_ 2610953432 1;
BA_ "GenMsgDelayTime" BO_ 2610953432 0;
BA_ "NetworkInitialization" BO_ 2610953432 0;
BA_ "TpTxIndex" BO_ 2609969368 462485720;
BA_ "GenMsgSendType" BO_ 2609969368 1;
BA_ "GenMsgDelayTime" BO_ 2609969368 0;
BA_ "NetworkInitialization" BO_ 2609969368 0;
BA_ "TpTxIndex" BO_ 2610126910 462485720;
BA_ "GenMsgSendType" BO_ 2610126910 1;
BA_ "GenMsgDelayTime" BO_ 2610126910 0;
BA_ "NetworkInitialization" BO_ 2610126910 0;
BA_ "FrameGatewayId" BO_ 811 811;
BA_ "FrameGatewayNetwork" BO_ 811 "HS3_CAN";
BA_ "FrameRouting" BO_ 811 "HS3_CAN,0x32B;";
BA_ "GenMsgSendType" BO_ 810 5;
BA_ "GenMsgCycleTime" BO_ 810 1000;
BA_ "GenMsgSendType" BO_ 303 0;
BA_ "GenMsgCycleTime" BO_ 303 100;
BA_ "GenMsgSendType" BO_ 1082 5;
BA_ "GenMsgCycleTime" BO_ 1082 1000;
BA_ "GenMsgSendType" BO_ 902 5;
BA_ "GenMsgCycleTime" BO_ 902 1000;
BA_ "FrameGatewayId" BO_ 740 740;
BA_ "FrameRouting" BO_ 740 "HS5_CAN,0x2E4";
BA_ "FrameGatewayNetwork" BO_ 740 "HS5_CAN";
BA_ "FrameGatewayId" BO_ 748 748;
BA_ "FrameRouting" BO_ 748 "HS5_CAN,0x2EC";
BA_ "FrameGatewayNetwork" BO_ 748 "HS5_CAN";
BA_ "FrameGatewayId" BO_ 389 389;
BA_ "FrameGatewayNetwork" BO_ 389 "FD1_CAN";
BA_ "FrameRouting" BO_ 389 "FD1_CAN,0x185;";
BA_ "FrameGatewayId" BO_ 872 872;
BA_ "FrameGatewayNetwork" BO_ 872 "FD1_CAN";
BA_ "FrameRouting" BO_ 872 "FD1_CAN,0x368;";
BA_ "GenMsgSendType" BO_ 945 5;
BA_ "GenMsgCycleTime" BO_ 945 1000;
BA_ "FrameRouting" BO_ 985 "FD1_CAN,0x3D9;";
BA_ "FrameRouting" BO_ 984 "FD1_CAN,0x3D8;";
BA_ "FrameGatewayId" BO_ 1055 1055;
BA_ "FrameGatewayNetwork" BO_ 1055 "FD1_CAN";
BA_ "FrameRouting" BO_ 1055 "FD1_CAN,0x41F;";
BA_ "FrameGatewayId" BO_ 135 135;
BA_ "FrameGatewayNetwork" BO_ 135 "HS3_CAN";
BA_ "FrameRouting" BO_ 135 "HS3_CAN,0x87;";
BA_ "FrameGatewayId" BO_ 134 134;
BA_ "FrameGatewayNetwork" BO_ 134 "HS3_CAN";
BA_ "FrameRouting" BO_ 134 "HS3_CAN,0x86;";
BA_ "GenMsgSendType" BO_ 132 1;
BA_ "FrameGatewayId" BO_ 836 836;
BA_ "FrameGatewayNetwork" BO_ 836 "MS1_CAN";
BA_ "FrameRouting" BO_ 836 "MS1_CAN,0x344;";
BA_ "FrameRouting" BO_ 939 "FD1_CAN,0x3AB;";
BA_ "GenMsgSendType" BO_ 952 0;
BA_ "GenMsgCycleTime" BO_ 952 500;
BA_ "FrameGatewayId" BO_ 374 374;
BA_ "FrameGatewayNetwork" BO_ 374 "FD1_CAN";
BA_ "FrameRouting" BO_ 374 "FD1_CAN,0x176;";
BA_ "GenMsgSendType" BO_ 1095 5;
BA_ "GenMsgCycleTime" BO_ 1095 1000;
BA_ "GenMsgSendType" BO_ 1094 5;
BA_ "GenMsgCycleTime" BO_ 1094 1000;
BA_ "FrameGatewayId" BO_ 1100 1100;
BA_ "FrameGatewayNetwork" BO_ 1100 "FD1_CAN";
BA_ "FrameRouting" BO_ 1100 "FD1_CAN,0x44C;";
BA_ "FrameGatewayId" BO_ 993 993;
BA_ "FrameGatewayNetwork" BO_ 993 "MS1_CAN";
BA_ "FrameRouting" BO_ 993 "MS1_CAN,0x3E1;";
BA_ "FrameGatewayId" BO_ 131 131;
BA_ "FrameGatewayNetwork" BO_ 131 "HS2_CAN";
BA_ "FrameRouting" BO_ 131 "HS2_CAN,0x83;";
BA_ "FrameGatewayId" BO_ 819 819;
BA_ "FrameGatewayNetwork" BO_ 819 "MS1_CAN";
BA_ "FrameRouting" BO_ 819 "MS1_CAN,0x333;";
BA_ "U_CX727_MY2021_Rx" SG_ 1079 DrLatchRr_B_Falt 1;
BA_ "U_P702_MY2021_Rx" SG_ 1079 DrLatchRr_B_Falt 1;
BA_ "U_T6_MCA_MY2020_Rx" SG_ 1079 DrLatchRr_B_Falt 1;
BA_ "U_CD542_MY2021_Rx" SG_ 1079 DrLatchRr_B_Falt 1;
BA_ "U_U55X_MY2022_Rx" SG_ 1079 DrLatchRr_B_Falt 1;
BA_ "U_CD764_MY2022_Rx" SG_ 1079 DrLatchRr_B_Falt 1;
BA_ "U_CX727_MY2021_Rx" SG_ 1079 DrLatchRl_B_Falt 1;
BA_ "U_P702_MY2021_Rx" SG_ 1079 DrLatchRl_B_Falt 1;
BA_ "U_T6_MCA_MY2020_Rx" SG_ 1079 DrLatchRl_B_Falt 1;
BA_ "U_CD542_MY2021_Rx" SG_ 1079 DrLatchRl_B_Falt 1;
BA_ "U_U55X_MY2022_Rx" SG_ 1079 DrLatchRl_B_Falt 1;
BA_ "U_CD764_MY2022_Rx" SG_ 1079 DrLatchRl_B_Falt 1;
BA_ "U_CX727_MY2021_Rx" SG_ 1079 DrLatchLckRr_B_Stat 1;
BA_ "U_P702_MY2021_Rx" SG_ 1079 DrLatchLckRr_B_Stat 1;
BA_ "U_T6_MCA_MY2020_Rx" SG_ 1079 DrLatchLckRr_B_Stat 1;
BA_ "U_CD542_MY2021_Rx" SG_ 1079 DrLatchLckRr_B_Stat 1;
BA_ "U_U55X_MY2022_Rx" SG_ 1079 DrLatchLckRr_B_Stat 1;
BA_ "U_CD764_MY2022_Rx" SG_ 1079 DrLatchLckRr_B_Stat 1;
BA_ "U_CX727_MY2021_Rx" SG_ 1079 DrLatchLckRl_B_Stat 1;
BA_ "U_P702_MY2021_Rx" SG_ 1079 DrLatchLckRl_B_Stat 1;
BA_ "U_T6_MCA_MY2020_Rx" SG_ 1079 DrLatchLckRl_B_Stat 1;
BA_ "U_CD542_MY2021_Rx" SG_ 1079 DrLatchLckRl_B_Stat 1;
BA_ "U_U55X_MY2022_Rx" SG_ 1079 DrLatchLckRl_B_Stat 1;
BA_ "U_CD764_MY2022_Rx" SG_ 1079 DrLatchLckRl_B_Stat 1;
BA_ "U_CX727_MY2021_Rx" SG_ 1079 DrLatchLckFr_B_Stat 1;
BA_ "U_P702_MY2021_Rx" SG_ 1079 DrLatchLckFr_B_Stat 1;
BA_ "U_T6_MCA_MY2020_Rx" SG_ 1079 DrLatchLckFr_B_Stat 1;
BA_ "U_CD542_MY2021_Rx" SG_ 1079 DrLatchLckFr_B_Stat 1;
BA_ "U_U55X_MY2022_Rx" SG_ 1079 DrLatchLckFr_B_Stat 1;
BA_ "U_CD764_MY2022_Rx" SG_ 1079 DrLatchLckFr_B_Stat 1;
BA_ "U_CX727_MY2021_Rx" SG_ 1079 DrLatchLckFl_B_Stat 1;
BA_ "U_P702_MY2021_Rx" SG_ 1079 DrLatchLckFl_B_Stat 1;
BA_ "U_T6_MCA_MY2020_Rx" SG_ 1079 DrLatchLckFl_B_Stat 1;
BA_ "U_CD542_MY2021_Rx" SG_ 1079 DrLatchLckFl_B_Stat 1;
BA_ "U_U55X_MY2022_Rx" SG_ 1079 DrLatchLckFl_B_Stat 1;
BA_ "U_CD764_MY2022_Rx" SG_ 1079 DrLatchLckFl_B_Stat 1;
BA_ "U_CX727_MY2021_Rx" SG_ 1079 DrLatchFr_B_Falt 1;
BA_ "U_P702_MY2021_Rx" SG_ 1079 DrLatchFr_B_Falt 1;
BA_ "U_T6_MCA_MY2020_Rx" SG_ 1079 DrLatchFr_B_Falt 1;
BA_ "U_CD542_MY2021_Rx" SG_ 1079 DrLatchFr_B_Falt 1;
BA_ "U_U55X_MY2022_Rx" SG_ 1079 DrLatchFr_B_Falt 1;
BA_ "U_CD764_MY2022_Rx" SG_ 1079 DrLatchFr_B_Falt 1;
BA_ "U_CX727_MY2021_Rx" SG_ 1079 DrLatchFl_B_Falt 1;
BA_ "U_P702_MY2021_Rx" SG_ 1079 DrLatchFl_B_Falt 1;
BA_ "U_T6_MCA_MY2020_Rx" SG_ 1079 DrLatchFl_B_Falt 1;
BA_ "U_CD542_MY2021_Rx" SG_ 1079 DrLatchFl_B_Falt 1;
BA_ "U_U55X_MY2022_Rx" SG_ 1079 DrLatchFl_B_Falt 1;
BA_ "U_CD764_MY2022_Rx" SG_ 1079 DrLatchFl_B_Falt 1;
BA_ "U_CX727_MY2021_Rx" SG_ 1079 DrLatchCntRr_No_Actl 1;
BA_ "U_P702_MY2021_Rx" SG_ 1079 DrLatchCntRr_No_Actl 1;
BA_ "U_T6_MCA_MY2020_Rx" SG_ 1079 DrLatchCntRr_No_Actl 1;
BA_ "U_CD542_MY2021_Rx" SG_ 1079 DrLatchCntRr_No_Actl 1;
BA_ "U_U55X_MY2022_Rx" SG_ 1079 DrLatchCntRr_No_Actl 1;
BA_ "U_CD764_MY2022_Rx" SG_ 1079 DrLatchCntRr_No_Actl 1;
BA_ "U_CX727_MY2021_Rx" SG_ 1079 DrLatchCntRl_No_Actl 1;
BA_ "U_P702_MY2021_Rx" SG_ 1079 DrLatchCntRl_No_Actl 1;
BA_ "U_T6_MCA_MY2020_Rx" SG_ 1079 DrLatchCntRl_No_Actl 1;
BA_ "U_CD542_MY2021_Rx" SG_ 1079 DrLatchCntRl_No_Actl 1;
BA_ "U_U55X_MY2022_Rx" SG_ 1079 DrLatchCntRl_No_Actl 1;
BA_ "U_CD764_MY2022_Rx" SG_ 1079 DrLatchCntRl_No_Actl 1;
BA_ "U_CX727_MY2021_Rx" SG_ 1079 DrLatchCntFr_No_Actl 1;
BA_ "U_P702_MY2021_Rx" SG_ 1079 DrLatchCntFr_No_Actl 1;
BA_ "U_T6_MCA_MY2020_Rx" SG_ 1079 DrLatchCntFr_No_Actl 1;
BA_ "U_CD542_MY2021_Rx" SG_ 1079 DrLatchCntFr_No_Actl 1;
BA_ "U_U55X_MY2022_Rx" SG_ 1079 DrLatchCntFr_No_Actl 1;
BA_ "U_CD764_MY2022_Rx" SG_ 1079 DrLatchCntFr_No_Actl 1;
BA_ "U_CX727_MY2021_Rx" SG_ 1079 DrLatchCntFl_No_Actl 1;
BA_ "U_P702_MY2021_Rx" SG_ 1079 DrLatchCntFl_No_Actl 1;
BA_ "U_T6_MCA_MY2020_Rx" SG_ 1079 DrLatchCntFl_No_Actl 1;
BA_ "U_CD542_MY2021_Rx" SG_ 1079 DrLatchCntFl_No_Actl 1;
BA_ "U_U55X_MY2022_Rx" SG_ 1079 DrLatchCntFl_No_Actl 1;
BA_ "U_CD764_MY2022_Rx" SG_ 1079 DrLatchCntFl_No_Actl 1;
BA_ "U_CX727_MY2021_Rx" SG_ 1079 ChildLckFdbckRr_B_Stat 1;
BA_ "U_P702_MY2021_Rx" SG_ 1079 ChildLckFdbckRr_B_Stat 1;
BA_ "U_T6_MCA_MY2020_Rx" SG_ 1079 ChildLckFdbckRr_B_Stat 1;
BA_ "U_CD542_MY2021_Rx" SG_ 1079 ChildLckFdbckRr_B_Stat 1;
BA_ "U_U55X_MY2022_Rx" SG_ 1079 ChildLckFdbckRr_B_Stat 1;
BA_ "U_CD764_MY2022_Rx" SG_ 1079 ChildLckFdbckRr_B_Stat 1;
BA_ "U_CX727_MY2021_Rx" SG_ 1079 ChildLckFdbckRl_B_Stat 1;
BA_ "U_P702_MY2021_Rx" SG_ 1079 ChildLckFdbckRl_B_Stat 1;
BA_ "U_T6_MCA_MY2020_Rx" SG_ 1079 ChildLckFdbckRl_B_Stat 1;
BA_ "U_CD542_MY2021_Rx" SG_ 1079 ChildLckFdbckRl_B_Stat 1;
BA_ "U_U55X_MY2022_Rx" SG_ 1079 ChildLckFdbckRl_B_Stat 1;
BA_ "U_CD764_MY2022_Rx" SG_ 1079 ChildLckFdbckRl_B_Stat 1;
BA_ "GenSigSendType" SG_ 954 PosLghtFr_D_Stat 3;
BA_ "U_U55X_MY2022_Tx" SG_ 954 PosLghtFr_D_Stat 1;
BA_ "GenSigSendType" SG_ 954 PosLghtFl_D_Stat 3;
BA_ "U_U55X_MY2022_Tx" SG_ 954 PosLghtFl_D_Stat 1;
BA_ "WakeupSignal" SG_ 954 VehWlcmFrwlMde_D_Stat 1;
BA_ "GenSigSendType" SG_ 954 VehWlcmFrwlMde_D_Stat 3;
BA_ "U_T6_MCA_MY2020_Tx" SG_ 954 VehWlcmFrwlMde_D_Stat 1;
BA_ "U_CD542_MY2021_Tx" SG_ 954 VehWlcmFrwlMde_D_Stat 1;
BA_ "U_U55X_MY2022_Tx" SG_ 954 VehWlcmFrwlMde_D_Stat 1;
BA_ "U_CD764_MY2022_Tx" SG_ 954 VehWlcmFrwlMde_D_Stat 1;
BA_ "WakeupSignal" SG_ 954 LghtAmbDrvMde_B_Stat 1;
BA_ "GenSigSendType" SG_ 954 LghtAmbDrvMde_B_Stat 3;
BA_ "U_CD542_MY2021_Tx" SG_ 954 LghtAmbDrvMde_B_Stat 1;
BA_ "U_CD764_MY2022_Tx" SG_ 954 LghtAmbDrvMde_B_Stat 1;
BA_ "WakeupSignal" SG_ 954 PwRnngBoardPoll_D_Stat 1;
BA_ "GenSigSendType" SG_ 954 PwRnngBoardPoll_D_Stat 3;
BA_ "U_T6_MCA_MY2020_Tx" SG_ 954 PwRnngBoardPoll_D_Stat 1;
BA_ "U_CD542_MY2021_Tx" SG_ 954 PwRnngBoardPoll_D_Stat 1;
BA_ "U_U55X_MY2022_Tx" SG_ 954 PwRnngBoardPoll_D_Stat 1;
BA_ "U_CD764_MY2022_Tx" SG_ 954 PwRnngBoardPoll_D_Stat 1;
BA_ "WakeupSignal" SG_ 954 VehWlcmFrwl_D_Stat 1;
BA_ "GenSigSendType" SG_ 954 VehWlcmFrwl_D_Stat 3;
BA_ "U_T6_MCA_MY2020_Tx" SG_ 954 VehWlcmFrwl_D_Stat 1;
BA_ "U_CD542_MY2021_Tx" SG_ 954 VehWlcmFrwl_D_Stat 1;
BA_ "U_U55X_MY2022_Tx" SG_ 954 VehWlcmFrwl_D_Stat 1;
BA_ "U_CD764_MY2022_Tx" SG_ 954 VehWlcmFrwl_D_Stat 1;
BA_ "GenSigSendType" SG_ 1118 AcChrgRdy_B_Stat 3;
BA_ "GenSigSendType" SG_ 1118 ExtChrgNowButtn_B_Rq 3;
BA_ "U_CX727_MY2021_Tx" SG_ 1118 ExtChrgNowButtn_B_Rq 1;
BA_ "U_CD542_MY2021_Tx" SG_ 1118 ExtChrgNowButtn_B_Rq 1;
BA_ "GenSigSendType" SG_ 1118 CoolFanChrgr_D_Rq 3;
BA_ "U_CX727_MY2021_Rx" SG_ 1118 CoolFanChrgr_D_Rq 1;
BA_ "U_CD542_MY2021_Rx" SG_ 1118 CoolFanChrgr_D_Rq 1;
BA_ "U_CX727_MY2021_Tx" SG_ 1118 CoolFanChrgr_D_Rq 1;
BA_ "U_CD542_MY2021_Tx" SG_ 1118 CoolFanChrgr_D_Rq 1;
BA_ "GenSigSendType" SG_ 1118 ChrgrClntFlw_D_Rq 3;
BA_ "U_CX727_MY2021_Rx" SG_ 1118 ChrgrClntFlw_D_Rq 1;
BA_ "U_CD542_MY2021_Rx" SG_ 1118 ChrgrClntFlw_D_Rq 1;
BA_ "U_CX727_MY2021_Tx" SG_ 1118 ChrgrClntFlw_D_Rq 1;
BA_ "U_CD542_MY2021_Tx" SG_ 1118 ChrgrClntFlw_D_Rq 1;
BA_ "GenSigSendType" SG_ 1118 PlgStatEvnt_B_Stat 3;
BA_ "U_CX727_MY2021_Rx" SG_ 1118 PlgStatEvnt_B_Stat 1;
BA_ "U_CD542_MY2021_Rx" SG_ 1118 PlgStatEvnt_B_Stat 1;
BA_ "U_CX727_MY2021_Tx" SG_ 1118 PlgStatEvnt_B_Stat 1;
BA_ "U_CD542_MY2021_Tx" SG_ 1118 PlgStatEvnt_B_Stat 1;
BA_ "GenSigSendType" SG_ 1118 ChrgrCnnctPwr_B_Stat 3;
BA_ "U_CX727_MY2021_Rx" SG_ 1118 ChrgrCnnctPwr_B_Stat 1;
BA_ "U_CD542_MY2021_Rx" SG_ 1118 ChrgrCnnctPwr_B_Stat 1;
BA_ "U_CX727_MY2021_Tx" SG_ 1118 ChrgrCnnctPwr_B_Stat 1;
BA_ "U_CD542_MY2021_Tx" SG_ 1118 ChrgrCnnctPwr_B_Stat 1;
BA_ "GenSigSendType" SG_ 1118 ChrgrAvailEvnt_B_Stat 3;
BA_ "U_CX727_MY2021_Rx" SG_ 1118 ChrgrAvailEvnt_B_Stat 1;
BA_ "U_CD542_MY2021_Rx" SG_ 1118 ChrgrAvailEvnt_B_Stat 1;
BA_ "U_CX727_MY2021_Tx" SG_ 1118 ChrgrAvailEvnt_B_Stat 1;
BA_ "U_CD542_MY2021_Tx" SG_ 1118 ChrgrAvailEvnt_B_Stat 1;
BA_ "GenSigSendType" SG_ 1118 ChrgrSrvcRqd_B_Rq 3;
BA_ "ECGUsedRxSignal" SG_ 1118 ChrgrSrvcRqd_B_Rq 1;
BA_ "U_CD542_MY2021_Rx" SG_ 1118 ChrgrSrvcRqd_B_Rq 1;
BA_ "U_CD764_MY2022_Rx" SG_ 1118 ChrgrSrvcRqd_B_Rq 1;
BA_ "U_CX727_MY2021_Tx" SG_ 1118 ChrgrSrvcRqd_B_Rq 1;
BA_ "U_CD542_MY2021_Tx" SG_ 1118 ChrgrSrvcRqd_B_Rq 1;
BA_ "GenSigSendType" SG_ 1118 ChrgrS2Swtch_B_Stat 3;
BA_ "U_CX727_MY2021_Tx" SG_ 1118 ChrgrS2Swtch_B_Stat 1;
BA_ "U_CD542_MY2021_Tx" SG_ 1118 ChrgrS2Swtch_B_Stat 1;
BA_ "GenSigSendType" SG_ 1118 ChrgChngEvnt_B_Stat 3;
BA_ "U_CX727_MY2021_Rx" SG_ 1118 ChrgChngEvnt_B_Stat 1;
BA_ "U_CD542_MY2021_Rx" SG_ 1118 ChrgChngEvnt_B_Stat 1;
BA_ "U_CX727_MY2021_Tx" SG_ 1118 ChrgChngEvnt_B_Stat 1;
BA_ "U_CD542_MY2021_Tx" SG_ 1118 ChrgChngEvnt_B_Stat 1;
BA_ "GenSigSendType" SG_ 1118 ChrgCordLck_D_Stat 3;
BA_ "U_CX727_MY2021_Tx" SG_ 1118 ChrgCordLck_D_Stat 1;
BA_ "U_CD542_MY2021_Tx" SG_ 1118 ChrgCordLck_D_Stat 1;
BA_ "GenSigSendType" SG_ 1118 ChrgrInPwMde_D_Actl 3;
BA_ "U_CX727_MY2021_Rx" SG_ 1118 ChrgrInPwMde_D_Actl 1;
BA_ "U_CD542_MY2021_Rx" SG_ 1118 ChrgrInPwMde_D_Actl 1;
BA_ "ECGUsedRxSignal" SG_ 1118 ChrgrInPwMde_D_Actl 1;
BA_ "U_CD764_MY2022_Rx" SG_ 1118 ChrgrInPwMde_D_Actl 1;
BA_ "U_CX727_MY2021_Tx" SG_ 1118 ChrgrInPwMde_D_Actl 1;
BA_ "U_CD542_MY2021_Tx" SG_ 1118 ChrgrInPwMde_D_Actl 1;
BA_ "GenSigSendType" SG_ 1118 ChrgPortDrOpen_B_Stat 3;
BA_ "U_CX727_MY2021_Tx" SG_ 1118 ChrgPortDrOpen_B_Stat 1;
BA_ "U_CD542_MY2021_Tx" SG_ 1118 ChrgPortDrOpen_B_Stat 1;
BA_ "GenSigSendType" SG_ 1118 ChrgCordChlng2_No_Actl 3;
BA_ "U_CX727_MY2021_Rx" SG_ 1118 ChrgCordChlng2_No_Actl 1;
BA_ "U_P702_MY2021_Rx" SG_ 1118 ChrgCordChlng2_No_Actl 1;
BA_ "U_T6_MCA_MY2020_Rx" SG_ 1118 ChrgCordChlng2_No_Actl 1;
BA_ "U_CD542_MY2021_Rx" SG_ 1118 ChrgCordChlng2_No_Actl 1;
BA_ "U_U55X_MY2022_Rx" SG_ 1118 ChrgCordChlng2_No_Actl 1;
BA_ "U_CD764_MY2022_Rx" SG_ 1118 ChrgCordChlng2_No_Actl 1;
BA_ "U_CX727_MY2021_Tx" SG_ 1118 ChrgCordChlng2_No_Actl 1;
BA_ "U_CD542_MY2021_Tx" SG_ 1118 ChrgCordChlng2_No_Actl 1;
BA_ "GenSigSendType" SG_ 1118 ChrgCordChlng1_No_Actl 3;
BA_ "U_CX727_MY2021_Rx" SG_ 1118 ChrgCordChlng1_No_Actl 1;
BA_ "U_P702_MY2021_Rx" SG_ 1118 ChrgCordChlng1_No_Actl 1;
BA_ "U_T6_MCA_MY2020_Rx" SG_ 1118 ChrgCordChlng1_No_Actl 1;
BA_ "U_CD542_MY2021_Rx" SG_ 1118 ChrgCordChlng1_No_Actl 1;
BA_ "U_U55X_MY2022_Rx" SG_ 1118 ChrgCordChlng1_No_Actl 1;
BA_ "U_CD764_MY2022_Rx" SG_ 1118 ChrgCordChlng1_No_Actl 1;
BA_ "U_CX727_MY2021_Tx" SG_ 1118 ChrgCordChlng1_No_Actl 1;
BA_ "U_CD542_MY2021_Tx" SG_ 1118 ChrgCordChlng1_No_Actl 1;
BA_ "GenSigSendType" SG_ 1118 ChrgCrdLck_D_Falt 3;
BA_ "U_CD542_MY2021_Tx" SG_ 1118 ChrgCrdLck_D_Falt 1;
BA_ "U_CX727_MY2021_Tx" SG_ 953 KeyMyKeyTot_No2_Cnt 1;
BA_ "U_P702_MY2021_Tx" SG_ 953 KeyMyKeyTot_No2_Cnt 1;
BA_ "U_T6_MCA_MY2020_Tx" SG_ 953 KeyMyKeyTot_No2_Cnt 1;
BA_ "U_CD542_MY2021_Tx" SG_ 953 KeyMyKeyTot_No2_Cnt 1;
BA_ "U_U55X_MY2022_Tx" SG_ 953 KeyMyKeyTot_No2_Cnt 1;
BA_ "U_CD764_MY2022_Tx" SG_ 953 KeyMyKeyTot_No2_Cnt 1;
BA_ "U_CX727_MY2021_Tx" SG_ 953 KeyAdmnTot_No2_Cnt 1;
BA_ "U_P702_MY2021_Tx" SG_ 953 KeyAdmnTot_No2_Cnt 1;
BA_ "U_T6_MCA_MY2020_Tx" SG_ 953 KeyAdmnTot_No2_Cnt 1;
BA_ "U_CD542_MY2021_Tx" SG_ 953 KeyAdmnTot_No2_Cnt 1;
BA_ "U_U55X_MY2022_Tx" SG_ 953 KeyAdmnTot_No2_Cnt 1;
BA_ "U_CD764_MY2022_Tx" SG_ 953 KeyAdmnTot_No2_Cnt 1;
BA_ "GenSigSendType" SG_ 953 PaakMyKeySearch_D_Stat 3;
BA_ "U_CX727_MY2021_Tx" SG_ 953 PaakMyKeySearch_D_Stat 1;
BA_ "U_P702_MY2021_Tx" SG_ 953 PaakMyKeySearch_D_Stat 1;
BA_ "U_T6_MCA_MY2020_Tx" SG_ 953 PaakMyKeySearch_D_Stat 1;
BA_ "U_CD542_MY2021_Tx" SG_ 953 PaakMyKeySearch_D_Stat 1;
BA_ "U_U55X_MY2022_Tx" SG_ 953 PaakMyKeySearch_D_Stat 1;
BA_ "U_CD764_MY2022_Tx" SG_ 953 PaakMyKeySearch_D_Stat 1;
BA_ "GenSigSendType" SG_ 953 BattULoChrgHyb_D_Stat 3;
BA_ "U_T6_MCA_MY2020_Rx" SG_ 953 BattULoChrgHyb_D_Stat 1;
BA_ "ECGUsedRxSignal" SG_ 953 BattULoChrgHyb_D_Stat 1;
BA_ "U_CD542_MY2021_Rx" SG_ 953 BattULoChrgHyb_D_Stat 1;
BA_ "U_U55X_MY2022_Rx" SG_ 953 BattULoChrgHyb_D_Stat 1;
BA_ "U_CD764_MY2022_Rx" SG_ 953 BattULoChrgHyb_D_Stat 1;
BA_ "U_T6_MCA_MY2020_Tx" SG_ 953 BattULoChrgHyb_D_Stat 1;
BA_ "U_CD542_MY2021_Tx" SG_ 953 BattULoChrgHyb_D_Stat 1;
BA_ "U_CD764_MY2022_Tx" SG_ 953 BattULoChrgHyb_D_Stat 1;
BA_ "GenSigSendType" SG_ 953 BattULoChrgHyb_B_Rq 3;
BA_ "U_T6_MCA_MY2020_Tx" SG_ 953 BattULoChrgHyb_B_Rq 1;
BA_ "U_CD542_MY2021_Tx" SG_ 953 BattULoChrgHyb_B_Rq 1;
BA_ "U_CD764_MY2022_Tx" SG_ 953 BattULoChrgHyb_B_Rq 1;
BA_ "GenSigSendType" SG_ 953 ChrgCordLck_B_Stat 3;
BA_ "U_CX727_MY2021_Rx" SG_ 953 ChrgCordLck_B_Stat 1;
BA_ "U_CD542_MY2021_Rx" SG_ 953 ChrgCordLck_B_Stat 1;
BA_ "U_T6_MCA_MY2020_Rx" SG_ 953 ChrgCordLck_B_Stat 1;
BA_ "ECGUsedRxSignal" SG_ 953 ChrgCordLck_B_Stat 1;
BA_ "U_U55X_MY2022_Rx" SG_ 953 ChrgCordLck_B_Stat 1;
BA_ "U_CD764_MY2022_Rx" SG_ 953 ChrgCordLck_B_Stat 1;
BA_ "U_CX727_MY2021_Tx" SG_ 953 ChrgCordLck_B_Stat 1;
BA_ "U_P702_MY2021_Tx" SG_ 953 ChrgCordLck_B_Stat 1;
BA_ "U_T6_MCA_MY2020_Tx" SG_ 953 ChrgCordLck_B_Stat 1;
BA_ "U_CD542_MY2021_Tx" SG_ 953 ChrgCordLck_B_Stat 1;
BA_ "U_U55X_MY2022_Tx" SG_ 953 ChrgCordLck_B_Stat 1;
BA_ "U_CD764_MY2022_Tx" SG_ 953 ChrgCordLck_B_Stat 1;
BA_ "U_CX727_MY2021_Rx" SG_ 953 ChrgCordResp2_No_Actl 1;
BA_ "U_CD542_MY2021_Rx" SG_ 953 ChrgCordResp2_No_Actl 1;
BA_ "U_CX727_MY2021_Tx" SG_ 953 ChrgCordResp2_No_Actl 1;
BA_ "U_P702_MY2021_Tx" SG_ 953 ChrgCordResp2_No_Actl 1;
BA_ "U_T6_MCA_MY2020_Tx" SG_ 953 ChrgCordResp2_No_Actl 1;
BA_ "U_CD542_MY2021_Tx" SG_ 953 ChrgCordResp2_No_Actl 1;
BA_ "U_U55X_MY2022_Tx" SG_ 953 ChrgCordResp2_No_Actl 1;
BA_ "U_CD764_MY2022_Tx" SG_ 953 ChrgCordResp2_No_Actl 1;
BA_ "U_CX727_MY2021_Rx" SG_ 953 ChrgCordResp1_No_Actl 1;
BA_ "U_CD542_MY2021_Rx" SG_ 953 ChrgCordResp1_No_Actl 1;
BA_ "U_CX727_MY2021_Tx" SG_ 953 ChrgCordResp1_No_Actl 1;
BA_ "U_P702_MY2021_Tx" SG_ 953 ChrgCordResp1_No_Actl 1;
BA_ "U_T6_MCA_MY2020_Tx" SG_ 953 ChrgCordResp1_No_Actl 1;
BA_ "U_CD542_MY2021_Tx" SG_ 953 ChrgCordResp1_No_Actl 1;
BA_ "U_U55X_MY2022_Tx" SG_ 953 ChrgCordResp1_No_Actl 1;
BA_ "U_CD764_MY2022_Tx" SG_ 953 ChrgCordResp1_No_Actl 1;
BA_ "GenSigStartValueInteger" SG_ 953 WakeAlarm3_D_Stat 3;
BA_ "GenSigStartValue" SG_ 953 WakeAlarm3_D_Stat 3;
BA_ "GenSigSendType" SG_ 953 WakeAlarm3_D_Stat 3;
BA_ "U_CX727_MY2021_Tx" SG_ 953 WakeAlarm3_D_Stat 1;
BA_ "U_P702_MY2021_Tx" SG_ 953 WakeAlarm3_D_Stat 1;
BA_ "U_T6_MCA_MY2020_Tx" SG_ 953 WakeAlarm3_D_Stat 1;
BA_ "U_CD542_MY2021_Tx" SG_ 953 WakeAlarm3_D_Stat 1;
BA_ "U_U55X_MY2022_Tx" SG_ 953 WakeAlarm3_D_Stat 1;
BA_ "U_CD764_MY2022_Tx" SG_ 953 WakeAlarm3_D_Stat 1;
BA_ "GenSigStartValueInteger" SG_ 953 WakeAlarm2_D_Stat 3;
BA_ "GenSigStartValue" SG_ 953 WakeAlarm2_D_Stat 3;
BA_ "GenSigSendType" SG_ 953 WakeAlarm2_D_Stat 3;
BA_ "U_CX727_MY2021_Tx" SG_ 953 WakeAlarm2_D_Stat 1;
BA_ "U_P702_MY2021_Tx" SG_ 953 WakeAlarm2_D_Stat 1;
BA_ "U_T6_MCA_MY2020_Tx" SG_ 953 WakeAlarm2_D_Stat 1;
BA_ "U_CD542_MY2021_Tx" SG_ 953 WakeAlarm2_D_Stat 1;
BA_ "U_U55X_MY2022_Tx" SG_ 953 WakeAlarm2_D_Stat 1;
BA_ "U_CD764_MY2022_Tx" SG_ 953 WakeAlarm2_D_Stat 1;
BA_ "GenSigStartValueInteger" SG_ 953 WakeAlarm1_D_Stat 3;
BA_ "GenSigStartValue" SG_ 953 WakeAlarm1_D_Stat 3;
BA_ "GenSigSendType" SG_ 953 WakeAlarm1_D_Stat 3;
BA_ "U_CX727_MY2021_Tx" SG_ 953 WakeAlarm1_D_Stat 1;
BA_ "U_P702_MY2021_Tx" SG_ 953 WakeAlarm1_D_Stat 1;
BA_ "U_T6_MCA_MY2020_Tx" SG_ 953 WakeAlarm1_D_Stat 1;
BA_ "U_CD542_MY2021_Tx" SG_ 953 WakeAlarm1_D_Stat 1;
BA_ "U_U55X_MY2022_Tx" SG_ 953 WakeAlarm1_D_Stat 1;
BA_ "U_CD764_MY2022_Tx" SG_ 953 WakeAlarm1_D_Stat 1;
BA_ "GenSigStartValueInteger" SG_ 953 WakeAlarm0_D_Stat 3;
BA_ "GenSigStartValue" SG_ 953 WakeAlarm0_D_Stat 3;
BA_ "GenSigSendType" SG_ 953 WakeAlarm0_D_Stat 3;
BA_ "U_CX727_MY2021_Tx" SG_ 953 WakeAlarm0_D_Stat 1;
BA_ "U_P702_MY2021_Tx" SG_ 953 WakeAlarm0_D_Stat 1;
BA_ "U_T6_MCA_MY2020_Tx" SG_ 953 WakeAlarm0_D_Stat 1;
BA_ "U_CD542_MY2021_Tx" SG_ 953 WakeAlarm0_D_Stat 1;
BA_ "U_U55X_MY2022_Tx" SG_ 953 WakeAlarm0_D_Stat 1;
BA_ "U_CD764_MY2022_Tx" SG_ 953 WakeAlarm0_D_Stat 1;
BA_ "GenSigStartValueInteger" SG_ 1112 BattTrac2_E_Max 4094;
BA_ "GenSigStartValue" SG_ 1112 BattTrac2_E_Max 4094;
BA_ "ECGUsedRxSignal" SG_ 1112 BattTrac2_E_Max 1;
BA_ "U_CD542_MY2021_Rx" SG_ 1112 BattTrac2_E_Max 1;
BA_ "U_U55X_MY2022_Rx" SG_ 1112 BattTrac2_E_Max 1;
BA_ "U_CD764_MY2022_Rx" SG_ 1112 BattTrac2_E_Max 1;
BA_ "U_CX727_MY2021_Tx" SG_ 1112 BattTrac2_E_Max 1;
BA_ "U_CD542_MY2021_Tx" SG_ 1112 BattTrac2_E_Max 1;
BA_ "ECGUsedRxSignal" SG_ 1112 BattTrac2_E_Avail 1;
BA_ "U_CD542_MY2021_Rx" SG_ 1112 BattTrac2_E_Avail 1;
BA_ "U_U55X_MY2022_Rx" SG_ 1112 BattTrac2_E_Avail 1;
BA_ "U_CD764_MY2022_Rx" SG_ 1112 BattTrac2_E_Avail 1;
BA_ "U_CX727_MY2021_Tx" SG_ 1112 BattTrac2_E_Avail 1;
BA_ "U_CD542_MY2021_Tx" SG_ 1112 BattTrac2_E_Avail 1;
BA_ "GenSigSendType" SG_ 1112 BattTracTeEvnt_B_Stat 3;
BA_ "U_CX727_MY2021_Rx" SG_ 1112 BattTracTeEvnt_B_Stat 1;
BA_ "U_CD542_MY2021_Rx" SG_ 1112 BattTracTeEvnt_B_Stat 1;
BA_ "U_CX727_MY2021_Tx" SG_ 1112 BattTracTeEvnt_B_Stat 1;
BA_ "U_CD542_MY2021_Tx" SG_ 1112 BattTracTeEvnt_B_Stat 1;
BA_ "GenSigSendType" SG_ 1112 BattChrgTrgtEvnt_B_Stat 3;
BA_ "U_CX727_MY2021_Rx" SG_ 1112 BattChrgTrgtEvnt_B_Stat 1;
BA_ "U_CD542_MY2021_Rx" SG_ 1112 BattChrgTrgtEvnt_B_Stat 1;
BA_ "U_CX727_MY2021_Tx" SG_ 1112 BattChrgTrgtEvnt_B_Stat 1;
BA_ "U_CD542_MY2021_Tx" SG_ 1112 BattChrgTrgtEvnt_B_Stat 1;
BA_ "GenSigSendType" SG_ 1112 BattTracTeSustn_B_Rq 3;
BA_ "U_CX727_MY2021_Rx" SG_ 1112 BattTracTeSustn_B_Rq 1;
BA_ "U_P702_MY2021_Rx" SG_ 1112 BattTracTeSustn_B_Rq 1;
BA_ "U_T6_MCA_MY2020_Rx" SG_ 1112 BattTracTeSustn_B_Rq 1;
BA_ "U_CD542_MY2021_Rx" SG_ 1112 BattTracTeSustn_B_Rq 1;
BA_ "U_U55X_MY2022_Rx" SG_ 1112 BattTracTeSustn_B_Rq 1;
BA_ "U_CD764_MY2022_Rx" SG_ 1112 BattTracTeSustn_B_Rq 1;
BA_ "GenSigSendType" SG_ 1112 BattTracChrgSustn_B_Rq 3;
BA_ "U_CX727_MY2021_Rx" SG_ 1112 BattTracChrgSustn_B_Rq 1;
BA_ "U_CD542_MY2021_Rx" SG_ 1112 BattTracChrgSustn_B_Rq 1;
BA_ "U_P702_MY2021_Rx" SG_ 1112 BattTracChrgSustn_B_Rq 1;
BA_ "U_T6_MCA_MY2020_Rx" SG_ 1112 BattTracChrgSustn_B_Rq 1;
BA_ "U_U55X_MY2022_Rx" SG_ 1112 BattTracChrgSustn_B_Rq 1;
BA_ "U_CD764_MY2022_Rx" SG_ 1112 BattTracChrgSustn_B_Rq 1;
BA_ "U_CX727_MY2021_Tx" SG_ 1112 BattTracChrgSustn_B_Rq 1;
BA_ "U_CD542_MY2021_Tx" SG_ 1112 BattTracChrgSustn_B_Rq 1;
BA_ "GenSigSendType" SG_ 1112 BattTracHeat_D_Rq 3;
BA_ "GenSigSendType" SG_ 1112 BattTracCnnct_D_Cmd 3;
BA_ "U_CX727_MY2021_Rx" SG_ 1112 BattTracCnnct_D_Cmd 1;
BA_ "U_CD542_MY2021_Rx" SG_ 1112 BattTracCnnct_D_Cmd 1;
BA_ "U_CX727_MY2021_Tx" SG_ 1112 BattTracCnnct_D_Cmd 1;
BA_ "U_P702_MY2021_Tx" SG_ 1112 BattTracCnnct_D_Cmd 1;
BA_ "U_CD542_MY2021_Tx" SG_ 1112 BattTracCnnct_D_Cmd 1;
BA_ "GenSigSendType" SG_ 1112 BattTracHvilOpen_B_Stat 3;
BA_ "U_CX727_MY2021_Tx" SG_ 1112 BattTracHvilOpen_B_Stat 1;
BA_ "U_P702_MY2021_Tx" SG_ 1112 BattTracHvilOpen_B_Stat 1;
BA_ "U_CD542_MY2021_Tx" SG_ 1112 BattTracHvilOpen_B_Stat 1;
BA_ "GenSigSendType" SG_ 1112 BattTracDcdcDis_B_Rq 3;
BA_ "U_CX727_MY2021_Tx" SG_ 1112 BattTracDcdcDis_B_Rq 1;
BA_ "U_P702_MY2021_Tx" SG_ 1112 BattTracDcdcDis_B_Rq 1;
BA_ "U_CD542_MY2021_Tx" SG_ 1112 BattTracDcdcDis_B_Rq 1;
BA_ "GenSigSendType" SG_ 1112 BattTracDiagClr_B_Rq 3;
BA_ "U_CX727_MY2021_Tx" SG_ 1112 BattTracDiagClr_B_Rq 1;
BA_ "U_P702_MY2021_Tx" SG_ 1112 BattTracDiagClr_B_Rq 1;
BA_ "U_CD542_MY2021_Tx" SG_ 1112 BattTracDiagClr_B_Rq 1;
BA_ "GenSigSendType" SG_ 1112 BattTracHazrd_D_Stat 3;
BA_ "U_CD542_MY2021_Tx" SG_ 1112 BattTracHazrd_D_Stat 1;
BA_ "GenSigSendType" SG_ 1112 HtrnClntPump_D_Stat 3;
BA_ "U_CX727_MY2021_Rx" SG_ 1112 HtrnClntPump_D_Stat 1;
BA_ "U_CD542_MY2021_Rx" SG_ 1112 HtrnClntPump_D_Stat 1;
BA_ "U_P702_MY2021_Rx" SG_ 1112 HtrnClntPump_D_Stat 1;
BA_ "U_CX727_MY2021_Tx" SG_ 1112 HtrnClntPump_D_Stat 1;
BA_ "U_P702_MY2021_Tx" SG_ 1112 HtrnClntPump_D_Stat 1;
BA_ "U_CD542_MY2021_Tx" SG_ 1112 HtrnClntPump_D_Stat 1;
BA_ "GenSigStartValueInteger" SG_ 1112 BattTracDelta_Te_Actl 164;
BA_ "GenSigStartValue" SG_ 1112 BattTracDelta_Te_Actl 254;
BA_ "U_CX727_MY2021_Tx" SG_ 1112 BattTracDelta_Te_Actl 1;
BA_ "U_P702_MY2021_Tx" SG_ 1112 BattTracDelta_Te_Actl 1;
BA_ "U_CD542_MY2021_Tx" SG_ 1112 BattTracDelta_Te_Actl 1;
BA_ "ContentDependant" SG_ 1112 BattTracClntPmp_D_Stat 1;
BA_ "GenSigSendType" SG_ 1112 BattTracClntPmp_D_Stat 3;
BA_ "U_CX727_MY2021_Tx" SG_ 1112 BattTracClntPmp_D_Stat 1;
BA_ "U_P702_MY2021_Tx" SG_ 1112 BattTracClntPmp_D_Stat 1;
BA_ "U_CD542_MY2021_Tx" SG_ 1112 BattTracClntPmp_D_Stat 1;
BA_ "U_CX727_MY2021_Rx" SG_ 1144 BattChrgTrgtSoC_D_Rq 1;
BA_ "U_CD542_MY2021_Rx" SG_ 1144 BattChrgTrgtSoC_D_Rq 1;
BA_ "GenSigSendType" SG_ 1144 PreCondBatt_B_Actl 3;
BA_ "WakeupSignal" SG_ 1144 CabnEvapSovFront_B_Rq 1;
BA_ "GenSigSendType" SG_ 1144 CabnEvapSovFront_B_Rq 3;
BA_ "U_CX727_MY2021_Rx" SG_ 1144 CabnEvapSovFront_B_Rq 1;
BA_ "U_P702_MY2021_Rx" SG_ 1144 CabnEvapSovFront_B_Rq 1;
BA_ "U_CD542_MY2021_Rx" SG_ 1144 CabnEvapSovFront_B_Rq 1;
BA_ "U_U55X_MY2022_Rx" SG_ 1144 CabnEvapSovFront_B_Rq 1;
BA_ "WakeupSignal" SG_ 1144 HeatCoreSovRear_B_Rq 1;
BA_ "GenSigSendType" SG_ 1144 HeatCoreSovRear_B_Rq 3;
BA_ "WakeupSignal" SG_ 1144 BattChlrSov_B_Rq 1;
BA_ "GenSigSendType" SG_ 1144 BattChlrSov_B_Rq 3;
BA_ "U_CX727_MY2021_Rx" SG_ 1144 BattChlrSov_B_Rq 1;
BA_ "U_P702_MY2021_Rx" SG_ 1144 BattChlrSov_B_Rq 1;
BA_ "U_CD542_MY2021_Rx" SG_ 1144 BattChlrSov_B_Rq 1;
BA_ "U_U55X_MY2022_Rx" SG_ 1144 BattChlrSov_B_Rq 1;
BA_ "WakeupSignal" SG_ 1144 CabnEvapSovRear_B_Rq 1;
BA_ "GenSigSendType" SG_ 1144 CabnEvapSovRear_B_Rq 3;
BA_ "GenSigSendType" SG_ 1144 BrkAppl_D_RqPt 3;
BA_ "GenSigSendType" SG_ 1144 BattClntVlvOvrrd_D_Rq 3;
BA_ "GenSigSendType" SG_ 1144 BattTracChillerOn_B_Rq 3;
BA_ "GenSigSendType" SG_ 1144 BattTracChiller_D_Stat 3;
BA_ "GenSigSendType" SG_ 1144 ULoBattTrnsfrSustn_B_Rq 3;
BA_ "U_CD542_MY2021_Rx" SG_ 1144 ULoBattTrnsfrSustn_B_Rq 1;
BA_ "U_U55X_MY2022_Rx" SG_ 1144 ULoBattTrnsfrSustn_B_Rq 1;
BA_ "U_CD764_MY2022_Rx" SG_ 1144 ULoBattTrnsfrSustn_B_Rq 1;
BA_ "GenSigSendType" SG_ 1144 ULoBattTransfer_D_Stat 3;
BA_ "U_CD542_MY2021_Rx" SG_ 1144 ULoBattTransfer_D_Stat 1;
BA_ "U_U55X_MY2022_Rx" SG_ 1144 ULoBattTransfer_D_Stat 1;
BA_ "U_CD764_MY2022_Rx" SG_ 1144 ULoBattTransfer_D_Stat 1;
BA_ "GenSigSendType" SG_ 1144 HtrnDcdcDis_B_Rq 3;
BA_ "GenSigSendType" SG_ 1144 HtrnCnnctPwr_B_Stat 3;
BA_ "U_CX727_MY2021_Rx" SG_ 1144 HtrnCnnctPwr_B_Stat 1;
BA_ "U_CD542_MY2021_Rx" SG_ 1144 HtrnCnnctPwr_B_Stat 1;
BA_ "U_P702_MY2021_Rx" SG_ 1144 HtrnCnnctPwr_B_Stat 1;
BA_ "GenSigSendType" SG_ 1144 PtcHtr_D_Stat 3;
BA_ "GenSigStartValue" SG_ 1144 BattChrgInhbt_D2_Rq 1;
BA_ "GenSigSendType" SG_ 1144 WakeAlarm0_B_Typ 3;
BA_ "U_CX727_MY2021_Rx" SG_ 1144 WakeAlarm0_B_Typ 1;
BA_ "U_P702_MY2021_Rx" SG_ 1144 WakeAlarm0_B_Typ 1;
BA_ "U_T6_MCA_MY2020_Rx" SG_ 1144 WakeAlarm0_B_Typ 1;
BA_ "U_CD542_MY2021_Rx" SG_ 1144 WakeAlarm0_B_Typ 1;
BA_ "U_U55X_MY2022_Rx" SG_ 1144 WakeAlarm0_B_Typ 1;
BA_ "U_CD764_MY2022_Rx" SG_ 1144 WakeAlarm0_B_Typ 1;
BA_ "GenSigStartValueInteger" SG_ 1144 WakeAlarm0_T_Rq 32767;
BA_ "GenSigStartValue" SG_ 1144 WakeAlarm0_T_Rq 32767;
BA_ "U_CX727_MY2021_Rx" SG_ 1144 WakeAlarm0_T_Rq 1;
BA_ "U_P702_MY2021_Rx" SG_ 1144 WakeAlarm0_T_Rq 1;
BA_ "U_T6_MCA_MY2020_Rx" SG_ 1144 WakeAlarm0_T_Rq 1;
BA_ "U_CD542_MY2021_Rx" SG_ 1144 WakeAlarm0_T_Rq 1;
BA_ "U_U55X_MY2022_Rx" SG_ 1144 WakeAlarm0_T_Rq 1;
BA_ "U_CD764_MY2022_Rx" SG_ 1144 WakeAlarm0_T_Rq 1;
BA_ "GenSigSendType" SG_ 1144 BattTracClimtDis_B_Stat 3;
BA_ "GenSigSendType" SG_ 1144 HtrnClntFlw_D_Rq 3;
BA_ "U_CX727_MY2021_Rx" SG_ 1144 HtrnClntFlw_D_Rq 1;
BA_ "U_P702_MY2021_Rx" SG_ 1144 HtrnClntFlw_D_Rq 1;
BA_ "U_CD542_MY2021_Rx" SG_ 1144 HtrnClntFlw_D_Rq 1;
BA_ "GenSigSendType" SG_ 1144 BattTracDrvSustn_B_Rq 3;
BA_ "U_CX727_MY2021_Rx" SG_ 1144 BattTracDrvSustn_B_Rq 1;
BA_ "U_CD542_MY2021_Rx" SG_ 1144 BattTracDrvSustn_B_Rq 1;
BA_ "U_P702_MY2021_Rx" SG_ 1144 BattTracDrvSustn_B_Rq 1;
BA_ "U_T6_MCA_MY2020_Rx" SG_ 1144 BattTracDrvSustn_B_Rq 1;
BA_ "U_U55X_MY2022_Rx" SG_ 1144 BattTracDrvSustn_B_Rq 1;
BA_ "U_CD764_MY2022_Rx" SG_ 1144 BattTracDrvSustn_B_Rq 1;
BA_ "GenSigSendType" SG_ 1144 CabinDrvSustn_B_Rq 3;
BA_ "U_CX727_MY2021_Rx" SG_ 1144 CabinDrvSustn_B_Rq 1;
BA_ "U_CD542_MY2021_Rx" SG_ 1144 CabinDrvSustn_B_Rq 1;
BA_ "U_P702_MY2021_Rx" SG_ 1144 CabinDrvSustn_B_Rq 1;
BA_ "U_T6_MCA_MY2020_Rx" SG_ 1144 CabinDrvSustn_B_Rq 1;
BA_ "U_U55X_MY2022_Rx" SG_ 1144 CabinDrvSustn_B_Rq 1;
BA_ "U_CD764_MY2022_Rx" SG_ 1144 CabinDrvSustn_B_Rq 1;
BA_ "GenSigSendType" SG_ 1144 BattTracClntVlv_B_Rq 3;
BA_ "U_P702_MY2021_Rx" SG_ 1144 BattTracClntVlv_B_Rq 1;
BA_ "U_CD542_MY2021_Rx" SG_ 1144 BattTracClntVlv_B_Rq 1;
BA_ "U_U55X_MY2022_Rx" SG_ 1144 BattTracClntVlv_B_Rq 1;
BA_ "GenSigSendType" SG_ 1144 ChrgNowEvnt_B_Stat 3;
BA_ "U_CX727_MY2021_Rx" SG_ 1144 ChrgNowEvnt_B_Stat 1;
BA_ "U_CD542_MY2021_Rx" SG_ 1144 ChrgNowEvnt_B_Stat 1;
BA_ "GenSigStartValueInteger" SG_ 127 AwdLckRgen_Tq_RqMn 4095;
BA_ "GenSigStartValueInteger" SG_ 127 AwdLatDelta_Tq_Rq 1;
BA_ "GenSigStartValue" SG_ 127 AwdLatDelta_Tq_Rq 1;
BA_ "U_CX727_MY2021_Tx" SG_ 589 BattTrac2_Pw_LimChrg 1;
BA_ "U_P702_MY2021_Tx" SG_ 589 BattTrac2_Pw_LimChrg 1;
BA_ "U_CD542_MY2021_Tx" SG_ 589 BattTrac2_Pw_LimChrg 1;
BA_ "U_CX727_MY2021_Tx" SG_ 589 BattTrac2_Pw_LimDchrg 1;
BA_ "U_P702_MY2021_Tx" SG_ 589 BattTrac2_Pw_LimDchrg 1;
BA_ "U_CD542_MY2021_Tx" SG_ 589 BattTrac2_Pw_LimDchrg 1;
BA_ "U_CX727_MY2021_Tx" SG_ 589 BattTrac2_Pw_DchrgInst 1;
BA_ "U_P702_MY2021_Tx" SG_ 589 BattTrac2_Pw_DchrgInst 1;
BA_ "U_CD542_MY2021_Tx" SG_ 589 BattTrac2_Pw_DchrgInst 1;
BA_ "U_CX727_MY2021_Tx" SG_ 589 BattTrac2_Pw_ChrgInst 1;
BA_ "U_P702_MY2021_Tx" SG_ 589 BattTrac2_Pw_ChrgInst 1;
BA_ "U_CD542_MY2021_Tx" SG_ 589 BattTrac2_Pw_ChrgInst 1;
BA_ "GenSigStartValueInteger" SG_ 968 CurrentColor_CmdGage 8;
BA_ "GenSigStartValue" SG_ 968 CurrentColor_CmdGage 8;
BA_ "GenSigStartValueInteger" SG_ 968 BlendedColor_CmdGage 2;
BA_ "GenSigStartValue" SG_ 968 BlendedColor_CmdGage 2;
BA_ "GenSigStartValueInteger" SG_ 968 Current_Color_Cmd 8;
BA_ "GenSigStartValue" SG_ 968 Current_Color_Cmd 8;
BA_ "GenSigStartValueInteger" SG_ 968 BlendedColor_Cmd 2;
BA_ "GenSigStartValue" SG_ 968 BlendedColor_Cmd 2;
BA_ "GenSigStartValueInteger" SG_ 968 SlMde_D_Rq 2;
BA_ "GenSigStartValue" SG_ 968 SlMde_D_Rq 2;
BA_ "GenSigStartValueInteger" SG_ 968 IsaOffst_D_Rq 14;
BA_ "GenSigStartValue" SG_ 968 IsaOffst_D_Rq 14;
BA_ "U_CX727_MY2021_Rx" SG_ 1081 ChirpRq_No_ActlTrlr_UB 1;
BA_ "U_P702_MY2021_Rx" SG_ 1081 ChirpRq_No_ActlTrlr_UB 1;
BA_ "U_T6_MCA_MY2020_Rx" SG_ 1081 ChirpRq_No_ActlTrlr_UB 1;
BA_ "U_CD542_MY2021_Rx" SG_ 1081 ChirpRq_No_ActlTrlr_UB 1;
BA_ "U_U55X_MY2022_Rx" SG_ 1081 ChirpRq_No_ActlTrlr_UB 1;
BA_ "U_CD764_MY2022_Rx" SG_ 1081 ChirpRq_No_ActlTrlr_UB 1;
BA_ "U_CX727_MY2021_Rx" SG_ 1081 ChirpRq_No_ActlTrlr 1;
BA_ "U_P702_MY2021_Rx" SG_ 1081 ChirpRq_No_ActlTrlr 1;
BA_ "U_T6_MCA_MY2020_Rx" SG_ 1081 ChirpRq_No_ActlTrlr 1;
BA_ "U_CD542_MY2021_Rx" SG_ 1081 ChirpRq_No_ActlTrlr 1;
BA_ "U_U55X_MY2022_Rx" SG_ 1081 ChirpRq_No_ActlTrlr 1;
BA_ "U_CD764_MY2022_Rx" SG_ 1081 ChirpRq_No_ActlTrlr 1;
BA_ "U_CX727_MY2021_Rx" SG_ 1081 Chirp_D_RqTrlr_UB 1;
BA_ "U_P702_MY2021_Rx" SG_ 1081 Chirp_D_RqTrlr_UB 1;
BA_ "U_T6_MCA_MY2020_Rx" SG_ 1081 Chirp_D_RqTrlr_UB 1;
BA_ "U_CD542_MY2021_Rx" SG_ 1081 Chirp_D_RqTrlr_UB 1;
BA_ "U_U55X_MY2022_Rx" SG_ 1081 Chirp_D_RqTrlr_UB 1;
BA_ "U_CD764_MY2022_Rx" SG_ 1081 Chirp_D_RqTrlr_UB 1;
BA_ "GenSigSendType" SG_ 1081 Chirp_D_RqTrlr 3;
BA_ "U_CX727_MY2021_Rx" SG_ 1081 Chirp_D_RqTrlr 1;
BA_ "U_P702_MY2021_Rx" SG_ 1081 Chirp_D_RqTrlr 1;
BA_ "U_T6_MCA_MY2020_Rx" SG_ 1081 Chirp_D_RqTrlr 1;
BA_ "U_CD542_MY2021_Rx" SG_ 1081 Chirp_D_RqTrlr 1;
BA_ "U_U55X_MY2022_Rx" SG_ 1081 Chirp_D_RqTrlr 1;
BA_ "U_CD764_MY2022_Rx" SG_ 1081 Chirp_D_RqTrlr 1;
BA_ "U_CX727_MY2021_Rx" SG_ 1081 RearPassWindowPos_UB 1;
BA_ "U_P702_MY2021_Rx" SG_ 1081 RearPassWindowPos_UB 1;
BA_ "U_T6_MCA_MY2020_Rx" SG_ 1081 RearPassWindowPos_UB 1;
BA_ "U_CD542_MY2021_Rx" SG_ 1081 RearPassWindowPos_UB 1;
BA_ "U_U55X_MY2022_Rx" SG_ 1081 RearPassWindowPos_UB 1;
BA_ "U_CD764_MY2022_Rx" SG_ 1081 RearPassWindowPos_UB 1;
BA_ "WakeupSignal" SG_ 1081 RearPassWindowPos 1;
BA_ "GenSigSendType" SG_ 1081 RearPassWindowPos 3;
BA_ "U_CX727_MY2021_Rx" SG_ 1081 RearPassWindowPos 1;
BA_ "U_P702_MY2021_Rx" SG_ 1081 RearPassWindowPos 1;
BA_ "U_T6_MCA_MY2020_Rx" SG_ 1081 RearPassWindowPos 1;
BA_ "U_CD542_MY2021_Rx" SG_ 1081 RearPassWindowPos 1;
BA_ "U_U55X_MY2022_Rx" SG_ 1081 RearPassWindowPos 1;
BA_ "U_CD764_MY2022_Rx" SG_ 1081 RearPassWindowPos 1;
BA_ "U_CX727_MY2021_Rx" SG_ 1081 RearDriverWindowPos_UB 1;
BA_ "U_P702_MY2021_Rx" SG_ 1081 RearDriverWindowPos_UB 1;
BA_ "U_T6_MCA_MY2020_Rx" SG_ 1081 RearDriverWindowPos_UB 1;
BA_ "U_CD542_MY2021_Rx" SG_ 1081 RearDriverWindowPos_UB 1;
BA_ "U_U55X_MY2022_Rx" SG_ 1081 RearDriverWindowPos_UB 1;
BA_ "U_CD764_MY2022_Rx" SG_ 1081 RearDriverWindowPos_UB 1;
BA_ "WakeupSignal" SG_ 1081 RearDriverWindowPos 1;
BA_ "GenSigSendType" SG_ 1081 RearDriverWindowPos 3;
BA_ "U_CX727_MY2021_Rx" SG_ 1081 RearDriverWindowPos 1;
BA_ "U_P702_MY2021_Rx" SG_ 1081 RearDriverWindowPos 1;
BA_ "U_T6_MCA_MY2020_Rx" SG_ 1081 RearDriverWindowPos 1;
BA_ "U_CD542_MY2021_Rx" SG_ 1081 RearDriverWindowPos 1;
BA_ "U_U55X_MY2022_Rx" SG_ 1081 RearDriverWindowPos 1;
BA_ "U_CD764_MY2022_Rx" SG_ 1081 RearDriverWindowPos 1;
BA_ "U_CX727_MY2021_Rx" SG_ 1081 PassWindowPosition_UB 1;
BA_ "U_P702_MY2021_Rx" SG_ 1081 PassWindowPosition_UB 1;
BA_ "U_T6_MCA_MY2020_Rx" SG_ 1081 PassWindowPosition_UB 1;
BA_ "U_CD542_MY2021_Rx" SG_ 1081 PassWindowPosition_UB 1;
BA_ "U_U55X_MY2022_Rx" SG_ 1081 PassWindowPosition_UB 1;
BA_ "U_CD764_MY2022_Rx" SG_ 1081 PassWindowPosition_UB 1;
BA_ "WakeupSignal" SG_ 1081 PassWindowPosition 1;
BA_ "GenSigSendType" SG_ 1081 PassWindowPosition 3;
BA_ "U_CX727_MY2021_Rx" SG_ 1081 PassWindowPosition 1;
BA_ "U_P702_MY2021_Rx" SG_ 1081 PassWindowPosition 1;
BA_ "U_T6_MCA_MY2020_Rx" SG_ 1081 PassWindowPosition 1;
BA_ "U_CD542_MY2021_Rx" SG_ 1081 PassWindowPosition 1;
BA_ "U_U55X_MY2022_Rx" SG_ 1081 PassWindowPosition 1;
BA_ "U_CD764_MY2022_Rx" SG_ 1081 PassWindowPosition 1;
BA_ "U_CX727_MY2021_Rx" SG_ 1081 DriverWindowPosition_UB 1;
BA_ "U_P702_MY2021_Rx" SG_ 1081 DriverWindowPosition_UB 1;
BA_ "U_T6_MCA_MY2020_Rx" SG_ 1081 DriverWindowPosition_UB 1;
BA_ "U_CD542_MY2021_Rx" SG_ 1081 DriverWindowPosition_UB 1;
BA_ "U_U55X_MY2022_Rx" SG_ 1081 DriverWindowPosition_UB 1;
BA_ "U_CD764_MY2022_Rx" SG_ 1081 DriverWindowPosition_UB 1;
BA_ "WakeupSignal" SG_ 1081 DriverWindowPosition 1;
BA_ "GenSigSendType" SG_ 1081 DriverWindowPosition 3;
BA_ "U_CX727_MY2021_Rx" SG_ 1081 DriverWindowPosition 1;
BA_ "U_P702_MY2021_Rx" SG_ 1081 DriverWindowPosition 1;
BA_ "U_T6_MCA_MY2020_Rx" SG_ 1081 DriverWindowPosition 1;
BA_ "U_CD542_MY2021_Rx" SG_ 1081 DriverWindowPosition 1;
BA_ "U_U55X_MY2022_Rx" SG_ 1081 DriverWindowPosition 1;
BA_ "U_CD764_MY2022_Rx" SG_ 1081 DriverWindowPosition 1;
BA_ "GenSigSendType" SG_ 1081 ChrgCrdLckEnbl_B_Stat 3;
BA_ "U_CX727_MY2021_Rx" SG_ 1081 EcoInhbt_B_RqHvac_UB 1;
BA_ "U_P702_MY2021_Rx" SG_ 1081 EcoInhbt_B_RqHvac_UB 1;
BA_ "U_T6_MCA_MY2020_Rx" SG_ 1081 EcoInhbt_B_RqHvac_UB 1;
BA_ "U_CD542_MY2021_Rx" SG_ 1081 EcoInhbt_B_RqHvac_UB 1;
BA_ "U_U55X_MY2022_Rx" SG_ 1081 EcoInhbt_B_RqHvac_UB 1;
BA_ "U_CD764_MY2022_Rx" SG_ 1081 EcoInhbt_B_RqHvac_UB 1;
BA_ "U_CX727_MY2021_Rx" SG_ 1081 EmgcyAsstActv_D_Stat_UB 1;
BA_ "U_P702_MY2021_Rx" SG_ 1081 EmgcyAsstActv_D_Stat_UB 1;
BA_ "U_T6_MCA_MY2020_Rx" SG_ 1081 EmgcyAsstActv_D_Stat_UB 1;
BA_ "U_CD542_MY2021_Rx" SG_ 1081 EmgcyAsstActv_D_Stat_UB 1;
BA_ "U_U55X_MY2022_Rx" SG_ 1081 EmgcyAsstActv_D_Stat_UB 1;
BA_ "U_CD764_MY2022_Rx" SG_ 1081 EmgcyAsstActv_D_Stat_UB 1;
BA_ "GenSigSendType" SG_ 1081 EmgcyAsstActv_D_Stat 3;
BA_ "U_CX727_MY2021_Rx" SG_ 1081 EmgcyAsstActv_D_Stat 1;
BA_ "U_P702_MY2021_Rx" SG_ 1081 EmgcyAsstActv_D_Stat 1;
BA_ "U_T6_MCA_MY2020_Rx" SG_ 1081 EmgcyAsstActv_D_Stat 1;
BA_ "U_CD542_MY2021_Rx" SG_ 1081 EmgcyAsstActv_D_Stat 1;
BA_ "U_U55X_MY2022_Rx" SG_ 1081 EmgcyAsstActv_D_Stat 1;
BA_ "U_CD764_MY2022_Rx" SG_ 1081 EmgcyAsstActv_D_Stat 1;
BA_ "U_CX727_MY2021_Rx" SG_ 1081 TrlrHitchLamp_D_Rq2_UB 1;
BA_ "U_P702_MY2021_Rx" SG_ 1081 TrlrHitchLamp_D_Rq2_UB 1;
BA_ "U_T6_MCA_MY2020_Rx" SG_ 1081 TrlrHitchLamp_D_Rq2_UB 1;
BA_ "U_U55X_MY2022_Rx" SG_ 1081 TrlrHitchLamp_D_Rq2_UB 1;
BA_ "U_CD764_MY2022_Rx" SG_ 1081 TrlrHitchLamp_D_Rq2_UB 1;
BA_ "GenSigSendType" SG_ 1081 TrlrHitchLamp_D_Rq2 3;
BA_ "U_CX727_MY2021_Rx" SG_ 1081 TrlrHitchLamp_D_Rq2 1;
BA_ "U_P702_MY2021_Rx" SG_ 1081 TrlrHitchLamp_D_Rq2 1;
BA_ "U_T6_MCA_MY2020_Rx" SG_ 1081 TrlrHitchLamp_D_Rq2 1;
BA_ "U_U55X_MY2022_Rx" SG_ 1081 TrlrHitchLamp_D_Rq2 1;
BA_ "U_CD764_MY2022_Rx" SG_ 1081 TrlrHitchLamp_D_Rq2 1;
BA_ "GenSigSendType" SG_ 1081 EcoInhbt_B_RqHvac 3;
BA_ "U_CX727_MY2021_Rx" SG_ 1081 EcoInhbt_B_RqHvac 1;
BA_ "U_P702_MY2021_Rx" SG_ 1081 EcoInhbt_B_RqHvac 1;
BA_ "U_T6_MCA_MY2020_Rx" SG_ 1081 EcoInhbt_B_RqHvac 1;
BA_ "U_CD542_MY2021_Rx" SG_ 1081 EcoInhbt_B_RqHvac 1;
BA_ "U_U55X_MY2022_Rx" SG_ 1081 EcoInhbt_B_RqHvac 1;
BA_ "U_CD764_MY2022_Rx" SG_ 1081 EcoInhbt_B_RqHvac 1;
BA_ "GenSigSendType" SG_ 910 CloudVehCtlData_Tp_Rq 3;
BA_ "U_T6_MCA_MY2020_Rx" SG_ 910 CloudVehCtlData_Tp_Rq 1;
BA_ "U_CD542_MY2021_Rx" SG_ 910 CloudVehCtlData_Tp_Rq 1;
BA_ "U_U55X_MY2022_Rx" SG_ 910 CloudVehCtlData_Tp_Rq 1;
BA_ "U_CD764_MY2022_Rx" SG_ 910 CloudVehCtlData_Tp_Rq 1;
BA_ "U_T6_MCA_MY2020_Tx" SG_ 910 CloudVehCtlData_Tp_Rq 1;
BA_ "ECGUsedTxSignal" SG_ 910 CloudVehCtlData_Tp_Rq 1;
BA_ "U_CD542_MY2021_Tx" SG_ 910 CloudVehCtlData_Tp_Rq 1;
BA_ "U_U55X_MY2022_Tx" SG_ 910 CloudVehCtlData_Tp_Rq 1;
BA_ "U_CD764_MY2022_Tx" SG_ 910 CloudVehCtlData_Tp_Rq 1;
BA_ "GenSigSendType" SG_ 911 CloudVehCtlData_Tp_Res 3;
BA_ "U_T6_MCA_MY2020_Rx" SG_ 911 CloudVehCtlData_Tp_Res 1;
BA_ "ECGUsedRxSignal" SG_ 911 CloudVehCtlData_Tp_Res 1;
BA_ "U_CD542_MY2021_Rx" SG_ 911 CloudVehCtlData_Tp_Res 1;
BA_ "U_U55X_MY2022_Rx" SG_ 911 CloudVehCtlData_Tp_Res 1;
BA_ "U_CD764_MY2022_Rx" SG_ 911 CloudVehCtlData_Tp_Res 1;
BA_ "U_T6_MCA_MY2020_Tx" SG_ 911 CloudVehCtlData_Tp_Res 1;
BA_ "U_CD542_MY2021_Tx" SG_ 911 CloudVehCtlData_Tp_Res 1;
BA_ "U_U55X_MY2022_Tx" SG_ 911 CloudVehCtlData_Tp_Res 1;
BA_ "U_CD764_MY2022_Tx" SG_ 911 CloudVehCtlData_Tp_Res 1;
BA_ "GenSigSendType" SG_ 2609989848 OTAPhysGWM_ECGtoBCM 3;
BA_ "U_T6_MCA_MY2020_Rx" SG_ 2609989848 OTAPhysGWM_ECGtoBCM 1;
BA_ "U_CD542_MY2021_Rx" SG_ 2609989848 OTAPhysGWM_ECGtoBCM 1;
BA_ "U_U55X_MY2022_Rx" SG_ 2609989848 OTAPhysGWM_ECGtoBCM 1;
BA_ "U_CD764_MY2022_Rx" SG_ 2609989848 OTAPhysGWM_ECGtoBCM 1;
BA_ "U_T6_MCA_MY2020_Tx" SG_ 2609989848 OTAPhysGWM_ECGtoBCM 1;
BA_ "ECGUsedTxSignal" SG_ 2609989848 OTAPhysGWM_ECGtoBCM 1;
BA_ "U_CD542_MY2021_Tx" SG_ 2609989848 OTAPhysGWM_ECGtoBCM 1;
BA_ "U_CD764_MY2022_Tx" SG_ 2609989848 OTAPhysGWM_ECGtoBCM 1;
BA_ "GenSigSendType" SG_ 2610126930 OTAPhysBCMtoGWM_ECG 3;
BA_ "U_T6_MCA_MY2020_Rx" SG_ 2610126930 OTAPhysBCMtoGWM_ECG 1;
BA_ "ECGUsedRxSignal" SG_ 2610126930 OTAPhysBCMtoGWM_ECG 1;
BA_ "U_CD542_MY2021_Rx" SG_ 2610126930 OTAPhysBCMtoGWM_ECG 1;
BA_ "U_U55X_MY2022_Rx" SG_ 2610126930 OTAPhysBCMtoGWM_ECG 1;
BA_ "U_CD764_MY2022_Rx" SG_ 2610126930 OTAPhysBCMtoGWM_ECG 1;
BA_ "U_T6_MCA_MY2020_Tx" SG_ 2610126930 OTAPhysBCMtoGWM_ECG 1;
BA_ "U_CD542_MY2021_Tx" SG_ 2610126930 OTAPhysBCMtoGWM_ECG 1;
BA_ "U_U55X_MY2022_Tx" SG_ 2610126930 OTAPhysBCMtoGWM_ECG 1;
BA_ "U_CD764_MY2022_Tx" SG_ 2610126930 OTAPhysBCMtoGWM_ECG 1;
BA_ "GenSigSendType" SG_ 2612224062 PARSEDPushPACMtoGWM_ECG 3;
BA_ "ECGUsedRxSignal" SG_ 2612224062 PARSEDPushPACMtoGWM_ECG 1;
BA_ "U_CD542_MY2021_Rx" SG_ 2612224062 PARSEDPushPACMtoGWM_ECG 1;
BA_ "U_U55X_MY2022_Rx" SG_ 2612224062 PARSEDPushPACMtoGWM_ECG 1;
BA_ "GenSigSendType" SG_ 2611175486 PARSEDPhysPACMtoGWM_ECG 3;
BA_ "ECGUsedRxSignal" SG_ 2611175486 PARSEDPhysPACMtoGWM_ECG 1;
BA_ "U_CD542_MY2021_Rx" SG_ 2611175486 PARSEDPhysPACMtoGWM_ECG 1;
BA_ "U_U55X_MY2022_Rx" SG_ 2611175486 PARSEDPhysPACMtoGWM_ECG 1;
BA_ "GenSigSendType" SG_ 2611017944 PARSEDPhysGWM_ECGtoPACM 3;
BA_ "U_CD542_MY2021_Rx" SG_ 2611017944 PARSEDPhysGWM_ECGtoPACM 1;
BA_ "ECGUsedTxSignal" SG_ 2611017944 PARSEDPhysGWM_ECGtoPACM 1;
BA_ "U_CD542_MY2021_Tx" SG_ 2611017944 PARSEDPhysGWM_ECGtoPACM 1;
BA_ "GenSigSendType" SG_ 2612002008 PARSEDFuncGWM_ECG 3;
BA_ "U_T6_MCA_MY2020_Rx" SG_ 2612002008 PARSEDFuncGWM_ECG 1;
BA_ "U_CD542_MY2021_Rx" SG_ 2612002008 PARSEDFuncGWM_ECG 1;
BA_ "U_CD764_MY2022_Rx" SG_ 2612002008 PARSEDFuncGWM_ECG 1;
BA_ "U_P702_MY2021_Rx" SG_ 2612002008 PARSEDFuncGWM_ECG 1;
BA_ "U_U55X_MY2022_Rx" SG_ 2612002008 PARSEDFuncGWM_ECG 1;
BA_ "U_T6_MCA_MY2020_Tx" SG_ 2612002008 PARSEDFuncGWM_ECG 1;
BA_ "ECGUsedTxSignal" SG_ 2612002008 PARSEDFuncGWM_ECG 1;
BA_ "U_CD542_MY2021_Tx" SG_ 2612002008 PARSEDFuncGWM_ECG 1;
BA_ "U_U55X_MY2022_Tx" SG_ 2612002008 PARSEDFuncGWM_ECG 1;
BA_ "U_CD764_MY2022_Tx" SG_ 2612002008 PARSEDFuncGWM_ECG 1;
BA_ "GenSigSendType" SG_ 2610953432 OTAFuncGWM_ECG 3;
BA_ "U_P702_MY2021_Rx" SG_ 2610953432 OTAFuncGWM_ECG 1;
BA_ "U_U55X_MY2022_Rx" SG_ 2610953432 OTAFuncGWM_ECG 1;
BA_ "U_CD764_MY2022_Rx" SG_ 2610953432 OTAFuncGWM_ECG 1;
BA_ "U_T6_MCA_MY2020_Rx" SG_ 2610953432 OTAFuncGWM_ECG 1;
BA_ "U_CD542_MY2021_Rx" SG_ 2610953432 OTAFuncGWM_ECG 1;
BA_ "U_T6_MCA_MY2020_Tx" SG_ 2610953432 OTAFuncGWM_ECG 1;
BA_ "ECGUsedTxSignal" SG_ 2610953432 OTAFuncGWM_ECG 1;
BA_ "U_CD542_MY2021_Tx" SG_ 2610953432 OTAFuncGWM_ECG 1;
BA_ "U_U55X_MY2022_Tx" SG_ 2610953432 OTAFuncGWM_ECG 1;
BA_ "U_CD764_MY2022_Tx" SG_ 2610953432 OTAFuncGWM_ECG 1;
BA_ "GenSigSendType" SG_ 2609969368 OTAPhysGWM_ECGtoPACM 3;
BA_ "ECGUsedTxSignal" SG_ 2609969368 OTAPhysGWM_ECGtoPACM 1;
BA_ "U_CD542_MY2021_Tx" SG_ 2609969368 OTAPhysGWM_ECGtoPACM 1;
BA_ "GenSigSendType" SG_ 2610126910 OTAPhysPACMtoGWM_ECG 3;
BA_ "ECGUsedRxSignal" SG_ 2610126910 OTAPhysPACMtoGWM_ECG 1;
BA_ "U_CD542_MY2021_Rx" SG_ 2610126910 OTAPhysPACMtoGWM_ECG 1;
BA_ "U_U55X_MY2022_Rx" SG_ 2610126910 OTAPhysPACMtoGWM_ECG 1;
BA_ "WakeupSignal" SG_ 811 ExtLghtRight_D_RqMnu 1;
BA_ "U_T6_MCA_MY2020_Rx" SG_ 811 ExtLghtRight_D_RqMnu 1;
BA_ "U_U55X_MY2022_Rx" SG_ 811 ExtLghtRight_D_RqMnu 1;
BA_ "WakeupSignal" SG_ 811 ExtLghtRear_D_RqMnu 1;
BA_ "U_T6_MCA_MY2020_Rx" SG_ 811 ExtLghtRear_D_RqMnu 1;
BA_ "U_U55X_MY2022_Rx" SG_ 811 ExtLghtRear_D_RqMnu 1;
BA_ "WakeupSignal" SG_ 811 ExtLghtLeft_D_RqMnu 1;
BA_ "U_T6_MCA_MY2020_Rx" SG_ 811 ExtLghtLeft_D_RqMnu 1;
BA_ "U_U55X_MY2022_Rx" SG_ 811 ExtLghtLeft_D_RqMnu 1;
BA_ "WakeupSignal" SG_ 811 ExtLghtFront_D_RqMnu 1;
BA_ "U_T6_MCA_MY2020_Rx" SG_ 811 ExtLghtFront_D_RqMnu 1;
BA_ "U_U55X_MY2022_Rx" SG_ 811 ExtLghtFront_D_RqMnu 1;
BA_ "GenSigStartValue" SG_ 811 ScMnSoc_Pc_RqMnu 126;
BA_ "GenSigStartValue" SG_ 811 GoTEditMnte_T_RqMnu 14;
BA_ "GenSigStartValue" SG_ 811 GoTEditHr_T_RqMnu 30;
BA_ "GenSigStartValue" SG_ 811 DistToStopover_L_Actl 65535;
BA_ "WakeupSignal" SG_ 811 AutoLghtOvrrd_B_RqDrv 1;
BA_ "U_T6_MCA_MY2020_Rx" SG_ 811 AutoLghtOvrrd_B_RqDrv 1;
BA_ "U_U55X_MY2022_Rx" SG_ 811 AutoLghtOvrrd_B_RqDrv 1;
BA_ "WakeupSignal" SG_ 811 BecRleas_No_RqMnu 1;
BA_ "U_CD542_MY2021_Rx" SG_ 811 BecRleas_No_RqMnu 1;
BA_ "U_CD764_MY2022_Rx" SG_ 811 BecRleas_No_RqMnu 1;
BA_ "WakeupSignal" SG_ 811 TrnkFrontRleas_No_RqMnu 1;
BA_ "U_CD542_MY2021_Rx" SG_ 811 TrnkFrontRleas_No_RqMnu 1;
BA_ "WakeupSignal" SG_ 810 VehHorn_B_RqOccAlrt 1;
BA_ "GenSigSendType" SG_ 810 VehHorn_B_RqOccAlrt 3;
BA_ "ECGUsedTxSignal" SG_ 810 VehHorn_B_RqOccAlrt 1;
BA_ "U_CD764_MY2022_Tx" SG_ 810 VehHorn_B_RqOccAlrt 1;
BA_ "GenSigSendType" SG_ 810 DteCldAcceptData_B_Rq 3;
BA_ "ECGUsedTxSignal" SG_ 810 DteCldAcceptData_B_Rq 1;
BA_ "U_CD542_MY2021_Tx" SG_ 810 DteCldAcceptData_B_Rq 1;
BA_ "U_CD764_MY2022_Tx" SG_ 810 DteCldAcceptData_B_Rq 1;
BA_ "GenSigSendType" SG_ 810 RmtViewMde_B_Rq 3;
BA_ "U_CD764_MY2022_Rx" SG_ 810 RmtViewMde_B_Rq 1;
BA_ "ECGUsedTxSignal" SG_ 810 RmtViewMde_B_Rq 1;
BA_ "U_CD542_MY2021_Tx" SG_ 810 RmtViewMde_B_Rq 1;
BA_ "U_CD764_MY2022_Tx" SG_ 810 RmtViewMde_B_Rq 1;
BA_ "WakeupSignal" SG_ 810 ExtLghtDsply_B_StatArb 1;
BA_ "GenSigSendType" SG_ 810 ExtLghtDsply_B_StatArb 3;
BA_ "U_T6_MCA_MY2020_Rx" SG_ 810 ExtLghtDsply_B_StatArb 1;
BA_ "U_U55X_MY2022_Rx" SG_ 810 ExtLghtDsply_B_StatArb 1;
BA_ "U_T6_MCA_MY2020_Tx" SG_ 810 ExtLghtDsply_B_StatArb 1;
BA_ "ECGUsedTxSignal" SG_ 810 ExtLghtDsply_B_StatArb 1;
BA_ "U_CD542_MY2021_Tx" SG_ 810 ExtLghtDsply_B_StatArb 1;
BA_ "U_U55X_MY2022_Tx" SG_ 810 ExtLghtDsply_B_StatArb 1;
BA_ "U_CD764_MY2022_Tx" SG_ 810 ExtLghtDsply_B_StatArb 1;
BA_ "WakeupSignal" SG_ 810 ExtLghtRight_D_RqOta 1;
BA_ "GenSigSendType" SG_ 810 ExtLghtRight_D_RqOta 3;
BA_ "U_T6_MCA_MY2020_Rx" SG_ 810 ExtLghtRight_D_RqOta 1;
BA_ "U_U55X_MY2022_Rx" SG_ 810 ExtLghtRight_D_RqOta 1;
BA_ "U_T6_MCA_MY2020_Tx" SG_ 810 ExtLghtRight_D_RqOta 1;
BA_ "ECGUsedTxSignal" SG_ 810 ExtLghtRight_D_RqOta 1;
BA_ "U_CD542_MY2021_Tx" SG_ 810 ExtLghtRight_D_RqOta 1;
BA_ "U_U55X_MY2022_Tx" SG_ 810 ExtLghtRight_D_RqOta 1;
BA_ "U_CD764_MY2022_Tx" SG_ 810 ExtLghtRight_D_RqOta 1;
BA_ "WakeupSignal" SG_ 810 ExtLghtRear_D_RqOta 1;
BA_ "GenSigSendType" SG_ 810 ExtLghtRear_D_RqOta 3;
BA_ "U_T6_MCA_MY2020_Rx" SG_ 810 ExtLghtRear_D_RqOta 1;
BA_ "U_U55X_MY2022_Rx" SG_ 810 ExtLghtRear_D_RqOta 1;
BA_ "U_T6_MCA_MY2020_Tx" SG_ 810 ExtLghtRear_D_RqOta 1;
BA_ "ECGUsedTxSignal" SG_ 810 ExtLghtRear_D_RqOta 1;
BA_ "U_CD542_MY2021_Tx" SG_ 810 ExtLghtRear_D_RqOta 1;
BA_ "U_U55X_MY2022_Tx" SG_ 810 ExtLghtRear_D_RqOta 1;
BA_ "U_CD764_MY2022_Tx" SG_ 810 ExtLghtRear_D_RqOta 1;
BA_ "GenSigSendType" SG_ 810 DteCldCnclRoute_B_Rq 3;
BA_ "ECGUsedTxSignal" SG_ 810 DteCldCnclRoute_B_Rq 1;
BA_ "U_CD542_MY2021_Tx" SG_ 810 DteCldCnclRoute_B_Rq 1;
BA_ "U_U55X_MY2022_Tx" SG_ 810 DteCldCnclRoute_B_Rq 1;
BA_ "U_CD764_MY2022_Tx" SG_ 810 DteCldCnclRoute_B_Rq 1;
BA_ "WakeupSignal" SG_ 810 PtRmtRprt_D_Stat 1;
BA_ "GenSigSendType" SG_ 810 PtRmtRprt_D_Stat 3;
BA_ "ECGUsedTxSignal" SG_ 810 PtRmtRprt_D_Stat 1;
BA_ "U_CD542_MY2021_Tx" SG_ 810 PtRmtRprt_D_Stat 1;
BA_ "U_U55X_MY2022_Tx" SG_ 810 PtRmtRprt_D_Stat 1;
BA_ "U_CD764_MY2022_Tx" SG_ 810 PtRmtRprt_D_Stat 1;
BA_ "WakeupSignal" SG_ 810 NtfyDrvTrgtDist_L_Rq 1;
BA_ "GenSigStartValueInteger" SG_ 810 NtfyDrvTrgtDist_L_Rq 1;
BA_ "GenSigStartValue" SG_ 810 NtfyDrvTrgtDist_L_Rq 4095;
BA_ "GenSigSendType" SG_ 810 NtfyDrvTrgtDist_L_Rq 3;
BA_ "ECGUsedTxSignal" SG_ 810 NtfyDrvTrgtDist_L_Rq 1;
BA_ "U_CD542_MY2021_Tx" SG_ 810 NtfyDrvTrgtDist_L_Rq 1;
BA_ "U_U55X_MY2022_Tx" SG_ 810 NtfyDrvTrgtDist_L_Rq 1;
BA_ "U_CD764_MY2022_Tx" SG_ 810 NtfyDrvTrgtDist_L_Rq 1;
BA_ "WakeupSignal" SG_ 810 NtfyDrvSocLvl1_Pc_Rq 1;
BA_ "GenSigStartValueInteger" SG_ 810 NtfyDrvSocLvl1_Pc_Rq 1;
BA_ "GenSigStartValue" SG_ 810 NtfyDrvSocLvl1_Pc_Rq 127;
BA_ "GenSigSendType" SG_ 810 NtfyDrvSocLvl1_Pc_Rq 3;
BA_ "ECGUsedTxSignal" SG_ 810 NtfyDrvSocLvl1_Pc_Rq 1;
BA_ "U_CD542_MY2021_Tx" SG_ 810 NtfyDrvSocLvl1_Pc_Rq 1;
BA_ "U_U55X_MY2022_Tx" SG_ 810 NtfyDrvSocLvl1_Pc_Rq 1;
BA_ "U_CD764_MY2022_Tx" SG_ 810 NtfyDrvSocLvl1_Pc_Rq 1;
BA_ "GenSigStartValueInteger" SG_ 810 ChrgrPncEnbl_D_Rq 3;
BA_ "GenSigStartValue" SG_ 810 ChrgrPncEnbl_D_Rq 3;
BA_ "GenSigSendType" SG_ 810 ChrgrPncEnbl_D_Rq 3;
BA_ "ECGUsedTxSignal" SG_ 810 ChrgrPncEnbl_D_Rq 1;
BA_ "U_CD542_MY2021_Tx" SG_ 810 ChrgrPncEnbl_D_Rq 1;
BA_ "U_U55X_MY2022_Tx" SG_ 810 ChrgrPncEnbl_D_Rq 1;
BA_ "U_CD764_MY2022_Tx" SG_ 810 ChrgrPncEnbl_D_Rq 1;
BA_ "GenSigSendType" SG_ 810 OBCCSerial_D_Rq 3;
BA_ "ECGUsedTxSignal" SG_ 810 OBCCSerial_D_Rq 1;
BA_ "U_CD542_MY2021_Tx" SG_ 810 OBCCSerial_D_Rq 1;
BA_ "U_U55X_MY2022_Tx" SG_ 810 OBCCSerial_D_Rq 1;
BA_ "U_CD764_MY2022_Tx" SG_ 810 OBCCSerial_D_Rq 1;
BA_ "WakeupSignal" SG_ 810 ExtLghtLeft_D_RqOta 1;
BA_ "GenSigSendType" SG_ 810 ExtLghtLeft_D_RqOta 3;
BA_ "U_T6_MCA_MY2020_Rx" SG_ 810 ExtLghtLeft_D_RqOta 1;
BA_ "U_U55X_MY2022_Rx" SG_ 810 ExtLghtLeft_D_RqOta 1;
BA_ "U_T6_MCA_MY2020_Tx" SG_ 810 ExtLghtLeft_D_RqOta 1;
BA_ "ECGUsedTxSignal" SG_ 810 ExtLghtLeft_D_RqOta 1;
BA_ "U_CD542_MY2021_Tx" SG_ 810 ExtLghtLeft_D_RqOta 1;
BA_ "U_U55X_MY2022_Tx" SG_ 810 ExtLghtLeft_D_RqOta 1;
BA_ "U_CD764_MY2022_Tx" SG_ 810 ExtLghtLeft_D_RqOta 1;
BA_ "WakeupSignal" SG_ 810 ExtLghtFront_D_RqOta 1;
BA_ "GenSigSendType" SG_ 810 ExtLghtFront_D_RqOta 3;
BA_ "U_T6_MCA_MY2020_Rx" SG_ 810 ExtLghtFront_D_RqOta 1;
BA_ "U_U55X_MY2022_Rx" SG_ 810 ExtLghtFront_D_RqOta 1;
BA_ "U_T6_MCA_MY2020_Tx" SG_ 810 ExtLghtFront_D_RqOta 1;
BA_ "ECGUsedTxSignal" SG_ 810 ExtLghtFront_D_RqOta 1;
BA_ "U_CD542_MY2021_Tx" SG_ 810 ExtLghtFront_D_RqOta 1;
BA_ "U_U55X_MY2022_Tx" SG_ 810 ExtLghtFront_D_RqOta 1;
BA_ "U_CD764_MY2022_Tx" SG_ 810 ExtLghtFront_D_RqOta 1;
BA_ "GenSigSendType" SG_ 810 TlghtTest_D_RqArb 3;
BA_ "U_T6_MCA_MY2020_Rx" SG_ 810 TlghtTest_D_RqArb 1;
BA_ "U_U55X_MY2022_Rx" SG_ 810 TlghtTest_D_RqArb 1;
BA_ "U_T6_MCA_MY2020_Tx" SG_ 810 TlghtTest_D_RqArb 1;
BA_ "ECGUsedTxSignal" SG_ 810 TlghtTest_D_RqArb 1;
BA_ "U_CD542_MY2021_Tx" SG_ 810 TlghtTest_D_RqArb 1;
BA_ "U_U55X_MY2022_Tx" SG_ 810 TlghtTest_D_RqArb 1;
BA_ "U_CD764_MY2022_Tx" SG_ 810 TlghtTest_D_RqArb 1;
BA_ "GenSigStartValueInteger" SG_ 810 ChrgrPncSustn_B_Rq 3;
BA_ "GenSigSendType" SG_ 810 ChrgrPncSustn_B_Rq 3;
BA_ "ECGUsedTxSignal" SG_ 810 ChrgrPncSustn_B_Rq 1;
BA_ "U_CD542_MY2021_Tx" SG_ 810 ChrgrPncSustn_B_Rq 1;
BA_ "U_U55X_MY2022_Tx" SG_ 810 ChrgrPncSustn_B_Rq 1;
BA_ "U_CD764_MY2022_Tx" SG_ 810 ChrgrPncSustn_B_Rq 1;
BA_ "ContentDependant" SG_ 303 CanMsg12F_No_Crc 1;
BA_ "MetaData" SG_ 303 CanMsg12F_No_Crc 1;
BA_ "U_CD764_MY2022_Tx" SG_ 303 CanMsg12F_No_Crc 1;
BA_ "ContentDependant" SG_ 303 CanMsg12F_No_Cnt 1;
BA_ "MetaData" SG_ 303 CanMsg12F_No_Cnt 1;
BA_ "U_CD764_MY2022_Tx" SG_ 303 CanMsg12F_No_Cnt 1;
BA_ "WakeupSignal" SG_ 303 DrStatHood_D2_Actl 1;
BA_ "U_CD764_MY2022_Tx" SG_ 303 DrStatHood_D2_Actl 1;
BA_ "GenSigSendType" SG_ 1082 VdmSustnActv_B_Rq 3;
BA_ "U_CX727_MY2021_Rx" SG_ 1082 ChrgStatDsply_D_Rq_UB 1;
BA_ "U_CD542_MY2021_Rx" SG_ 1082 ChrgStatDsply_D_Rq_UB 1;
BA_ "GenSigStartValueInteger" SG_ 1082 ChrgStatDsply_D_Rq 1;
BA_ "GenSigStartValue" SG_ 1082 ChrgStatDsply_D_Rq 1;
BA_ "GenSigSendType" SG_ 1082 ChrgStatDsply_D_Rq 3;
BA_ "U_CX727_MY2021_Rx" SG_ 1082 ChrgStatDsply_D_Rq 1;
BA_ "U_CD542_MY2021_Rx" SG_ 1082 ChrgStatDsply_D_Rq 1;
BA_ "U_CX727_MY2021_Rx" SG_ 1082 ChrgCordUnlock_B_Rq_UB 1;
BA_ "U_CD542_MY2021_Rx" SG_ 1082 ChrgCordUnlock_B_Rq_UB 1;
BA_ "GenSigSendType" SG_ 1082 ChrgCordUnlock_B_Rq 3;
BA_ "U_CX727_MY2021_Rx" SG_ 1082 ChrgCordUnlock_B_Rq 1;
BA_ "U_CD542_MY2021_Rx" SG_ 1082 ChrgCordUnlock_B_Rq 1;
BA_ "U_P702_MY2021_Rx" SG_ 1082 FldngSeatPwOffOk_B_Stat_UB 1;
BA_ "U_T6_MCA_MY2020_Rx" SG_ 1082 FldngSeatPwOffOk_B_Stat_UB 1;
BA_ "WakeupSignal" SG_ 1082 FldngSeatPwOffOk_B_Stat 1;
BA_ "GenSigSendType" SG_ 1082 FldngSeatPwOffOk_B_Stat 3;
BA_ "U_P702_MY2021_Rx" SG_ 1082 FldngSeatPwOffOk_B_Stat 1;
BA_ "U_T6_MCA_MY2020_Rx" SG_ 1082 FldngSeatPwOffOk_B_Stat 1;
BA_ "GenSigSendType" SG_ 1082 EngAirFilt_B_RqReset 3;
BA_ "GenSigSendType" SG_ 1082 TrailCtl_D_Stat 3;
BA_ "U_P702_MY2021_Rx" SG_ 1082 DrLckActv_B_RqBalrr_UB 1;
BA_ "U_T6_MCA_MY2020_Rx" SG_ 1082 DrLckActv_B_RqBalrr_UB 1;
BA_ "U_U55X_MY2022_Rx" SG_ 1082 DrLckActv_B_RqBalrr_UB 1;
BA_ "U_P702_MY2021_Rx" SG_ 1082 DrLckActv_B_RqBalrl_UB 1;
BA_ "U_T6_MCA_MY2020_Rx" SG_ 1082 DrLckActv_B_RqBalrl_UB 1;
BA_ "U_U55X_MY2022_Rx" SG_ 1082 DrLckActv_B_RqBalrl_UB 1;
BA_ "U_P702_MY2021_Rx" SG_ 1082 DrLckCnt_No_ActlBalrr 1;
BA_ "U_T6_MCA_MY2020_Rx" SG_ 1082 DrLckCnt_No_ActlBalrr 1;
BA_ "U_U55X_MY2022_Rx" SG_ 1082 DrLckCnt_No_ActlBalrr 1;
BA_ "U_P702_MY2021_Rx" SG_ 1082 DrLckCnt_No_ActlBalrl 1;
BA_ "U_T6_MCA_MY2020_Rx" SG_ 1082 DrLckCnt_No_ActlBalrl 1;
BA_ "U_U55X_MY2022_Rx" SG_ 1082 DrLckCnt_No_ActlBalrl 1;
BA_ "GenSigSendType" SG_ 1082 DrLckActv_B_RqBalrr 3;
BA_ "U_P702_MY2021_Rx" SG_ 1082 DrLckActv_B_RqBalrr 1;
BA_ "U_T6_MCA_MY2020_Rx" SG_ 1082 DrLckActv_B_RqBalrr 1;
BA_ "U_U55X_MY2022_Rx" SG_ 1082 DrLckActv_B_RqBalrr 1;
BA_ "GenSigSendType" SG_ 1082 DrLckActv_B_RqBalrl 3;
BA_ "U_P702_MY2021_Rx" SG_ 1082 DrLckActv_B_RqBalrl 1;
BA_ "U_T6_MCA_MY2020_Rx" SG_ 1082 DrLckActv_B_RqBalrl 1;
BA_ "U_U55X_MY2022_Rx" SG_ 1082 DrLckActv_B_RqBalrl 1;
BA_ "GenSigSendType" SG_ 1082 EmgcyCall_D_Stat 3;
BA_ "U_CX727_MY2021_Rx" SG_ 1082 EmgcyCall_D_Stat 1;
BA_ "U_P702_MY2021_Rx" SG_ 1082 EmgcyCall_D_Stat 1;
BA_ "U_T6_MCA_MY2020_Rx" SG_ 1082 EmgcyCall_D_Stat 1;
BA_ "U_CD542_MY2021_Rx" SG_ 1082 EmgcyCall_D_Stat 1;
BA_ "U_U55X_MY2022_Rx" SG_ 1082 EmgcyCall_D_Stat 1;
BA_ "U_CD764_MY2022_Rx" SG_ 1082 EmgcyCall_D_Stat 1;
BA_ "U_CX727_MY2021_Rx" SG_ 1082 EmgcyCall_D_Stat_UB 1;
BA_ "U_P702_MY2021_Rx" SG_ 1082 EmgcyCall_D_Stat_UB 1;
BA_ "U_T6_MCA_MY2020_Rx" SG_ 1082 EmgcyCall_D_Stat_UB 1;
BA_ "U_CD542_MY2021_Rx" SG_ 1082 EmgcyCall_D_Stat_UB 1;
BA_ "U_U55X_MY2022_Rx" SG_ 1082 EmgcyCall_D_Stat_UB 1;
BA_ "U_CD764_MY2022_Rx" SG_ 1082 EmgcyCall_D_Stat_UB 1;
BA_ "U_CX727_MY2021_Rx" SG_ 1082 EmPrflNo_D_Rq_UB 1;
BA_ "U_P702_MY2021_Rx" SG_ 1082 EmPrflNo_D_Rq_UB 1;
BA_ "U_T6_MCA_MY2020_Rx" SG_ 1082 EmPrflNo_D_Rq_UB 1;
BA_ "U_CD542_MY2021_Rx" SG_ 1082 EmPrflNo_D_Rq_UB 1;
BA_ "U_U55X_MY2022_Rx" SG_ 1082 EmPrflNo_D_Rq_UB 1;
BA_ "U_CD764_MY2022_Rx" SG_ 1082 EmPrflNo_D_Rq_UB 1;
BA_ "U_CX727_MY2021_Rx" SG_ 1082 EmPrflKeyAssoc_D_Rq_UB 1;
BA_ "U_P702_MY2021_Rx" SG_ 1082 EmPrflKeyAssoc_D_Rq_UB 1;
BA_ "U_T6_MCA_MY2020_Rx" SG_ 1082 EmPrflKeyAssoc_D_Rq_UB 1;
BA_ "U_CD542_MY2021_Rx" SG_ 1082 EmPrflKeyAssoc_D_Rq_UB 1;
BA_ "U_U55X_MY2022_Rx" SG_ 1082 EmPrflKeyAssoc_D_Rq_UB 1;
BA_ "U_CD764_MY2022_Rx" SG_ 1082 EmPrflKeyAssoc_D_Rq_UB 1;
BA_ "GenSigSendType" SG_ 1082 EmPrflNo_D_Rq 3;
BA_ "U_CX727_MY2021_Rx" SG_ 1082 EmPrflNo_D_Rq 1;
BA_ "U_P702_MY2021_Rx" SG_ 1082 EmPrflNo_D_Rq 1;
BA_ "U_T6_MCA_MY2020_Rx" SG_ 1082 EmPrflNo_D_Rq 1;
BA_ "U_CD542_MY2021_Rx" SG_ 1082 EmPrflNo_D_Rq 1;
BA_ "U_U55X_MY2022_Rx" SG_ 1082 EmPrflNo_D_Rq 1;
BA_ "U_CD764_MY2022_Rx" SG_ 1082 EmPrflNo_D_Rq 1;
BA_ "GenSigSendType" SG_ 1082 EmPrflKeyAssoc_D_Rq 3;
BA_ "U_CX727_MY2021_Rx" SG_ 1082 EmPrflKeyAssoc_D_Rq 1;
BA_ "U_P702_MY2021_Rx" SG_ 1082 EmPrflKeyAssoc_D_Rq 1;
BA_ "U_T6_MCA_MY2020_Rx" SG_ 1082 EmPrflKeyAssoc_D_Rq 1;
BA_ "U_CD542_MY2021_Rx" SG_ 1082 EmPrflKeyAssoc_D_Rq 1;
BA_ "U_U55X_MY2022_Rx" SG_ 1082 EmPrflKeyAssoc_D_Rq 1;
BA_ "U_CD764_MY2022_Rx" SG_ 1082 EmPrflKeyAssoc_D_Rq 1;
BA_ "U_CX727_MY2021_Rx" SG_ 1082 CamraViewSplit_B_Rq_UB 1;
BA_ "U_P702_MY2021_Rx" SG_ 1082 CamraViewSplit_B_Rq_UB 1;
BA_ "U_T6_MCA_MY2020_Rx" SG_ 1082 CamraViewSplit_B_Rq_UB 1;
BA_ "U_CD542_MY2021_Rx" SG_ 1082 CamraViewSplit_B_Rq_UB 1;
BA_ "U_U55X_MY2022_Rx" SG_ 1082 CamraViewSplit_B_Rq_UB 1;
BA_ "U_CD764_MY2022_Rx" SG_ 1082 CamraViewSplit_B_Rq_UB 1;
BA_ "WakeupSignal" SG_ 1082 HMI_HMIMode_St 1;
BA_ "GenSigSendType" SG_ 1082 HMI_HMIMode_St 3;
BA_ "U_CX727_MY2021_Rx" SG_ 1082 HMI_HMIMode_St 1;
BA_ "U_P702_MY2021_Rx" SG_ 1082 HMI_HMIMode_St 1;
BA_ "U_T6_MCA_MY2020_Rx" SG_ 1082 HMI_HMIMode_St 1;
BA_ "U_CD542_MY2021_Rx" SG_ 1082 HMI_HMIMode_St 1;
BA_ "U_U55X_MY2022_Rx" SG_ 1082 HMI_HMIMode_St 1;
BA_ "U_CD764_MY2022_Rx" SG_ 1082 HMI_HMIMode_St 1;
BA_ "GenSigSendType" SG_ 1082 CamraViewSplit_B_Rq 3;
BA_ "U_CX727_MY2021_Rx" SG_ 1082 CamraViewSplit_B_Rq 1;
BA_ "U_P702_MY2021_Rx" SG_ 1082 CamraViewSplit_B_Rq 1;
BA_ "U_T6_MCA_MY2020_Rx" SG_ 1082 CamraViewSplit_B_Rq 1;
BA_ "U_CD542_MY2021_Rx" SG_ 1082 CamraViewSplit_B_Rq 1;
BA_ "U_U55X_MY2022_Rx" SG_ 1082 CamraViewSplit_B_Rq 1;
BA_ "U_CD764_MY2022_Rx" SG_ 1082 CamraViewSplit_B_Rq 1;
BA_ "U_CX727_MY2021_Rx" SG_ 1082 HMI_HMIMode_St_UB 1;
BA_ "U_P702_MY2021_Rx" SG_ 1082 HMI_HMIMode_St_UB 1;
BA_ "U_T6_MCA_MY2020_Rx" SG_ 1082 HMI_HMIMode_St_UB 1;
BA_ "U_CD542_MY2021_Rx" SG_ 1082 HMI_HMIMode_St_UB 1;
BA_ "U_U55X_MY2022_Rx" SG_ 1082 HMI_HMIMode_St_UB 1;
BA_ "U_CD764_MY2022_Rx" SG_ 1082 HMI_HMIMode_St_UB 1;
BA_ "U_CX727_MY2021_Rx" SG_ 902 PrmtrAlrmWarnRq_No_Actl_UB 1;
BA_ "U_P702_MY2021_Rx" SG_ 902 PrmtrAlrmWarnRq_No_Actl_UB 1;
BA_ "U_T6_MCA_MY2020_Rx" SG_ 902 PrmtrAlrmWarnRq_No_Actl_UB 1;
BA_ "U_CD542_MY2021_Rx" SG_ 902 PrmtrAlrmWarnRq_No_Actl_UB 1;
BA_ "U_U55X_MY2022_Rx" SG_ 902 PrmtrAlrmWarnRq_No_Actl_UB 1;
BA_ "U_CD764_MY2022_Rx" SG_ 902 PrmtrAlrmWarnRq_No_Actl_UB 1;
BA_ "U_CX727_MY2021_Rx" SG_ 902 PrmtrAlrmTrgRq_No_Actl_UB 1;
BA_ "U_P702_MY2021_Rx" SG_ 902 PrmtrAlrmTrgRq_No_Actl_UB 1;
BA_ "U_T6_MCA_MY2020_Rx" SG_ 902 PrmtrAlrmTrgRq_No_Actl_UB 1;
BA_ "U_CD542_MY2021_Rx" SG_ 902 PrmtrAlrmTrgRq_No_Actl_UB 1;
BA_ "U_U55X_MY2022_Rx" SG_ 902 PrmtrAlrmTrgRq_No_Actl_UB 1;
BA_ "U_CD764_MY2022_Rx" SG_ 902 PrmtrAlrmTrgRq_No_Actl_UB 1;
BA_ "WakeupSignal" SG_ 902 PrmtrAlrmWarnRq_No_Actl 1;
BA_ "GenSigSendType" SG_ 902 PrmtrAlrmWarnRq_No_Actl 3;
BA_ "U_CX727_MY2021_Rx" SG_ 902 PrmtrAlrmWarnRq_No_Actl 1;
BA_ "U_P702_MY2021_Rx" SG_ 902 PrmtrAlrmWarnRq_No_Actl 1;
BA_ "U_T6_MCA_MY2020_Rx" SG_ 902 PrmtrAlrmWarnRq_No_Actl 1;
BA_ "U_CD542_MY2021_Rx" SG_ 902 PrmtrAlrmWarnRq_No_Actl 1;
BA_ "U_U55X_MY2022_Rx" SG_ 902 PrmtrAlrmWarnRq_No_Actl 1;
BA_ "U_CD764_MY2022_Rx" SG_ 902 PrmtrAlrmWarnRq_No_Actl 1;
BA_ "WakeupSignal" SG_ 902 PrmtrAlrmTrgRq_No_Actl 1;
BA_ "GenSigSendType" SG_ 902 PrmtrAlrmTrgRq_No_Actl 3;
BA_ "U_CX727_MY2021_Rx" SG_ 902 PrmtrAlrmTrgRq_No_Actl 1;
BA_ "U_P702_MY2021_Rx" SG_ 902 PrmtrAlrmTrgRq_No_Actl 1;
BA_ "U_T6_MCA_MY2020_Rx" SG_ 902 PrmtrAlrmTrgRq_No_Actl 1;
BA_ "U_CD542_MY2021_Rx" SG_ 902 PrmtrAlrmTrgRq_No_Actl 1;
BA_ "U_U55X_MY2022_Rx" SG_ 902 PrmtrAlrmTrgRq_No_Actl 1;
BA_ "U_CD764_MY2022_Rx" SG_ 902 PrmtrAlrmTrgRq_No_Actl 1;
BA_ "U_CX727_MY2021_Rx" SG_ 902 PrmtrAlrmWarn_B_Rq_UB 1;
BA_ "U_P702_MY2021_Rx" SG_ 902 PrmtrAlrmWarn_B_Rq_UB 1;
BA_ "U_T6_MCA_MY2020_Rx" SG_ 902 PrmtrAlrmWarn_B_Rq_UB 1;
BA_ "U_CD542_MY2021_Rx" SG_ 902 PrmtrAlrmWarn_B_Rq_UB 1;
BA_ "U_U55X_MY2022_Rx" SG_ 902 PrmtrAlrmWarn_B_Rq_UB 1;
BA_ "U_CD764_MY2022_Rx" SG_ 902 PrmtrAlrmWarn_B_Rq_UB 1;
BA_ "U_CX727_MY2021_Rx" SG_ 902 RollCode_No_ActlRsm_UB 1;
BA_ "U_P702_MY2021_Rx" SG_ 902 RollCode_No_ActlRsm_UB 1;
BA_ "U_T6_MCA_MY2020_Rx" SG_ 902 RollCode_No_ActlRsm_UB 1;
BA_ "U_CD542_MY2021_Rx" SG_ 902 RollCode_No_ActlRsm_UB 1;
BA_ "U_U55X_MY2022_Rx" SG_ 902 RollCode_No_ActlRsm_UB 1;
BA_ "U_CD764_MY2022_Rx" SG_ 902 RollCode_No_ActlRsm_UB 1;
BA_ "U_CX727_MY2021_Rx" SG_ 902 PrmtrAlrmTrg_B_Rq_UB 1;
BA_ "U_P702_MY2021_Rx" SG_ 902 PrmtrAlrmTrg_B_Rq_UB 1;
BA_ "U_T6_MCA_MY2020_Rx" SG_ 902 PrmtrAlrmTrg_B_Rq_UB 1;
BA_ "U_CD542_MY2021_Rx" SG_ 902 PrmtrAlrmTrg_B_Rq_UB 1;
BA_ "U_U55X_MY2022_Rx" SG_ 902 PrmtrAlrmTrg_B_Rq_UB 1;
BA_ "U_CD764_MY2022_Rx" SG_ 902 PrmtrAlrmTrg_B_Rq_UB 1;
BA_ "U_CX727_MY2021_Rx" SG_ 902 PanicRq_No_ActlRsm_UB 1;
BA_ "U_P702_MY2021_Rx" SG_ 902 PanicRq_No_ActlRsm_UB 1;
BA_ "U_T6_MCA_MY2020_Rx" SG_ 902 PanicRq_No_ActlRsm_UB 1;
BA_ "U_CD542_MY2021_Rx" SG_ 902 PanicRq_No_ActlRsm_UB 1;
BA_ "U_U55X_MY2022_Rx" SG_ 902 PanicRq_No_ActlRsm_UB 1;
BA_ "U_CD764_MY2022_Rx" SG_ 902 PanicRq_No_ActlRsm_UB 1;
BA_ "U_CX727_MY2021_Rx" SG_ 902 Panic_D_RqRsm_UB 1;
BA_ "U_P702_MY2021_Rx" SG_ 902 Panic_D_RqRsm_UB 1;
BA_ "U_T6_MCA_MY2020_Rx" SG_ 902 Panic_D_RqRsm_UB 1;
BA_ "U_CD542_MY2021_Rx" SG_ 902 Panic_D_RqRsm_UB 1;
BA_ "U_U55X_MY2022_Rx" SG_ 902 Panic_D_RqRsm_UB 1;
BA_ "U_CD764_MY2022_Rx" SG_ 902 Panic_D_RqRsm_UB 1;
BA_ "U_CX727_MY2021_Rx" SG_ 902 CellLockRq_No_ActlRsm_UB 1;
BA_ "U_P702_MY2021_Rx" SG_ 902 CellLockRq_No_ActlRsm_UB 1;
BA_ "U_T6_MCA_MY2020_Rx" SG_ 902 CellLockRq_No_ActlRsm_UB 1;
BA_ "U_CD542_MY2021_Rx" SG_ 902 CellLockRq_No_ActlRsm_UB 1;
BA_ "U_U55X_MY2022_Rx" SG_ 902 CellLockRq_No_ActlRsm_UB 1;
BA_ "U_CD764_MY2022_Rx" SG_ 902 CellLockRq_No_ActlRsm_UB 1;
BA_ "WakeupSignal" SG_ 902 RollCode_No_ActlRsm 1;
BA_ "GenSigSendType" SG_ 902 RollCode_No_ActlRsm 3;
BA_ "U_CX727_MY2021_Rx" SG_ 902 RollCode_No_ActlRsm 1;
BA_ "U_P702_MY2021_Rx" SG_ 902 RollCode_No_ActlRsm 1;
BA_ "U_T6_MCA_MY2020_Rx" SG_ 902 RollCode_No_ActlRsm 1;
BA_ "U_CD542_MY2021_Rx" SG_ 902 RollCode_No_ActlRsm 1;
BA_ "U_U55X_MY2022_Rx" SG_ 902 RollCode_No_ActlRsm 1;
BA_ "U_CD764_MY2022_Rx" SG_ 902 RollCode_No_ActlRsm 1;
BA_ "WakeupSignal" SG_ 902 PrmtrAlrmWarn_B_Rq 1;
BA_ "GenSigSendType" SG_ 902 PrmtrAlrmWarn_B_Rq 3;
BA_ "U_CX727_MY2021_Rx" SG_ 902 PrmtrAlrmWarn_B_Rq 1;
BA_ "U_P702_MY2021_Rx" SG_ 902 PrmtrAlrmWarn_B_Rq 1;
BA_ "U_T6_MCA_MY2020_Rx" SG_ 902 PrmtrAlrmWarn_B_Rq 1;
BA_ "U_CD542_MY2021_Rx" SG_ 902 PrmtrAlrmWarn_B_Rq 1;
BA_ "U_U55X_MY2022_Rx" SG_ 902 PrmtrAlrmWarn_B_Rq 1;
BA_ "U_CD764_MY2022_Rx" SG_ 902 PrmtrAlrmWarn_B_Rq 1;
BA_ "WakeupSignal" SG_ 902 PrmtrAlrmTrg_B_Rq 1;
BA_ "GenSigSendType" SG_ 902 PrmtrAlrmTrg_B_Rq 3;
BA_ "U_CX727_MY2021_Rx" SG_ 902 PrmtrAlrmTrg_B_Rq 1;
BA_ "U_P702_MY2021_Rx" SG_ 902 PrmtrAlrmTrg_B_Rq 1;
BA_ "U_T6_MCA_MY2020_Rx" SG_ 902 PrmtrAlrmTrg_B_Rq 1;
BA_ "U_CD542_MY2021_Rx" SG_ 902 PrmtrAlrmTrg_B_Rq 1;
BA_ "U_U55X_MY2022_Rx" SG_ 902 PrmtrAlrmTrg_B_Rq 1;
BA_ "U_CD764_MY2022_Rx" SG_ 902 PrmtrAlrmTrg_B_Rq 1;
BA_ "WakeupSignal" SG_ 902 PanicRq_No_ActlRsm 1;
BA_ "GenSigSendType" SG_ 902 PanicRq_No_ActlRsm 3;
BA_ "U_CX727_MY2021_Rx" SG_ 902 PanicRq_No_ActlRsm 1;
BA_ "U_P702_MY2021_Rx" SG_ 902 PanicRq_No_ActlRsm 1;
BA_ "U_T6_MCA_MY2020_Rx" SG_ 902 PanicRq_No_ActlRsm 1;
BA_ "U_CD542_MY2021_Rx" SG_ 902 PanicRq_No_ActlRsm 1;
BA_ "U_U55X_MY2022_Rx" SG_ 902 PanicRq_No_ActlRsm 1;
BA_ "U_CD764_MY2022_Rx" SG_ 902 PanicRq_No_ActlRsm 1;
BA_ "WakeupSignal" SG_ 902 Panic_D_RqRsm 1;
BA_ "GenSigSendType" SG_ 902 Panic_D_RqRsm 3;
BA_ "U_CX727_MY2021_Rx" SG_ 902 Panic_D_RqRsm 1;
BA_ "U_P702_MY2021_Rx" SG_ 902 Panic_D_RqRsm 1;
BA_ "U_T6_MCA_MY2020_Rx" SG_ 902 Panic_D_RqRsm 1;
BA_ "U_CD542_MY2021_Rx" SG_ 902 Panic_D_RqRsm 1;
BA_ "U_U55X_MY2022_Rx" SG_ 902 Panic_D_RqRsm 1;
BA_ "U_CD764_MY2022_Rx" SG_ 902 Panic_D_RqRsm 1;
BA_ "WakeupSignal" SG_ 902 CellLockRq_No_ActlRsm 1;
BA_ "GenSigSendType" SG_ 902 CellLockRq_No_ActlRsm 3;
BA_ "U_CX727_MY2021_Rx" SG_ 902 CellLockRq_No_ActlRsm 1;
BA_ "U_P702_MY2021_Rx" SG_ 902 CellLockRq_No_ActlRsm 1;
BA_ "U_T6_MCA_MY2020_Rx" SG_ 902 CellLockRq_No_ActlRsm 1;
BA_ "U_CD542_MY2021_Rx" SG_ 902 CellLockRq_No_ActlRsm 1;
BA_ "U_U55X_MY2022_Rx" SG_ 902 CellLockRq_No_ActlRsm 1;
BA_ "U_CD764_MY2022_Rx" SG_ 902 CellLockRq_No_ActlRsm 1;
BA_ "WakeupSignal" SG_ 902 CellLock_D_RqRsm 1;
BA_ "GenSigSendType" SG_ 902 CellLock_D_RqRsm 3;
BA_ "U_CX727_MY2021_Rx" SG_ 902 CellLock_D_RqRsm 1;
BA_ "U_P702_MY2021_Rx" SG_ 902 CellLock_D_RqRsm 1;
BA_ "U_T6_MCA_MY2020_Rx" SG_ 902 CellLock_D_RqRsm 1;
BA_ "U_CD542_MY2021_Rx" SG_ 902 CellLock_D_RqRsm 1;
BA_ "U_U55X_MY2022_Rx" SG_ 902 CellLock_D_RqRsm 1;
BA_ "U_CD764_MY2022_Rx" SG_ 902 CellLock_D_RqRsm 1;
BA_ "U_CX727_MY2021_Rx" SG_ 902 CellLock_D_RqRsm_UB 1;
BA_ "U_P702_MY2021_Rx" SG_ 902 CellLock_D_RqRsm_UB 1;
BA_ "U_T6_MCA_MY2020_Rx" SG_ 902 CellLock_D_RqRsm_UB 1;
BA_ "U_CD542_MY2021_Rx" SG_ 902 CellLock_D_RqRsm_UB 1;
BA_ "U_U55X_MY2022_Rx" SG_ 902 CellLock_D_RqRsm_UB 1;
BA_ "U_CD764_MY2022_Rx" SG_ 902 CellLock_D_RqRsm_UB 1;
BA_ "WakeupSignal" SG_ 740 PtWakeupActv2_B_Rq 1;
BA_ "U_CX727_MY2021_Rx" SG_ 740 PtWakeupActv2_B_Rq 1;
BA_ "U_P702_MY2021_Rx" SG_ 740 PtWakeupActv2_B_Rq 1;
BA_ "U_T6_MCA_MY2020_Rx" SG_ 740 PtWakeupActv2_B_Rq 1;
BA_ "U_CD542_MY2021_Rx" SG_ 740 PtWakeupActv2_B_Rq 1;
BA_ "U_U55X_MY2022_Rx" SG_ 740 PtWakeupActv2_B_Rq 1;
BA_ "U_CD764_MY2022_Rx" SG_ 740 PtWakeupActv2_B_Rq 1;
BA_ "U_CX727_MY2021_Rx" SG_ 740 BattChrg_U_Rq 1;
BA_ "U_CD542_MY2021_Rx" SG_ 740 BattChrg_U_Rq 1;
BA_ "U_CX727_MY2021_Tx" SG_ 740 BattChrg_U_Rq 1;
BA_ "U_CD542_MY2021_Tx" SG_ 740 BattChrg_U_Rq 1;
BA_ "U_CX727_MY2021_Tx" SG_ 740 BattTracSoc_Pc_Dpltd 1;
BA_ "U_CD542_MY2021_Tx" SG_ 740 BattTracSoc_Pc_Dpltd 1;
BA_ "U_CX727_MY2021_Rx" SG_ 740 BattAuxCnnct_B_Cmd 1;
BA_ "U_CD542_MY2021_Rx" SG_ 740 BattAuxCnnct_B_Cmd 1;
BA_ "U_P702_MY2021_Rx" SG_ 740 BattAuxCnnct_B_Cmd 1;
BA_ "U_CX727_MY2021_Tx" SG_ 740 BattAuxCnnct_B_Cmd 1;
BA_ "U_CD542_MY2021_Tx" SG_ 740 BattAuxCnnct_B_Cmd 1;
BA_ "U_CX727_MY2021_Rx" SG_ 748 ChrgrOutHi_U_Actl 1;
BA_ "U_CD542_MY2021_Rx" SG_ 748 ChrgrOutHi_U_Actl 1;
BA_ "ECGUsedRxSignal" SG_ 748 ChrgrOutHi_U_Actl 1;
BA_ "U_U55X_MY2022_Rx" SG_ 748 ChrgrOutHi_U_Actl 1;
BA_ "U_CX727_MY2021_Tx" SG_ 748 ChrgrOutHi_U_Actl 1;
BA_ "U_CD542_MY2021_Tx" SG_ 748 ChrgrOutHi_U_Actl 1;
BA_ "U_CX727_MY2021_Rx" SG_ 748 ChrgrOutHi_I_Actl 1;
BA_ "U_CD542_MY2021_Rx" SG_ 748 ChrgrOutHi_I_Actl 1;
BA_ "ECGUsedRxSignal" SG_ 748 ChrgrOutHi_I_Actl 1;
BA_ "U_U55X_MY2022_Rx" SG_ 748 ChrgrOutHi_I_Actl 1;
BA_ "U_CX727_MY2021_Tx" SG_ 748 ChrgrOutHi_I_Actl 1;
BA_ "U_CD542_MY2021_Tx" SG_ 748 ChrgrOutHi_I_Actl 1;
BA_ "ECGUsedRxSignal" SG_ 748 ChrgrIn_Pw_Mx 1;
BA_ "U_CD542_MY2021_Rx" SG_ 748 ChrgrIn_Pw_Mx 1;
BA_ "U_U55X_MY2022_Rx" SG_ 748 ChrgrIn_Pw_Mx 1;
BA_ "U_CX727_MY2021_Rx" SG_ 748 ChrgrIn_Pw_Mx 1;
BA_ "U_CX727_MY2021_Tx" SG_ 748 ChrgrIn_Pw_Mx 1;
BA_ "U_CD542_MY2021_Tx" SG_ 748 ChrgrIn_Pw_Mx 1;
BA_ "GenSigStartValueInteger" SG_ 748 PlgActv_D_ActlChrgr 3;
BA_ "GenSigStartValue" SG_ 748 PlgActv_D_ActlChrgr 2;
BA_ "U_CX727_MY2021_Rx" SG_ 748 PlgActv_D_ActlChrgr 1;
BA_ "ECGUsedRxSignal" SG_ 748 PlgActv_D_ActlChrgr 1;
BA_ "U_CD542_MY2021_Rx" SG_ 748 PlgActv_D_ActlChrgr 1;
BA_ "U_U55X_MY2022_Rx" SG_ 748 PlgActv_D_ActlChrgr 1;
BA_ "U_CX727_MY2021_Tx" SG_ 748 PlgActv_D_ActlChrgr 1;
BA_ "U_CD542_MY2021_Tx" SG_ 748 PlgActv_D_ActlChrgr 1;
BA_ "U_CX727_MY2021_Rx" SG_ 748 ChrgrRdyStat_D_Actl 1;
BA_ "U_CD542_MY2021_Rx" SG_ 748 ChrgrRdyStat_D_Actl 1;
BA_ "U_CX727_MY2021_Tx" SG_ 748 ChrgrRdyStat_D_Actl 1;
BA_ "U_CD542_MY2021_Tx" SG_ 748 ChrgrRdyStat_D_Actl 1;
BA_ "U_CX727_MY2021_Rx" SG_ 389 BattTracClntFlw_Pc_Rq 1;
BA_ "U_P702_MY2021_Rx" SG_ 389 BattTracClntFlw_Pc_Rq 1;
BA_ "U_CD542_MY2021_Rx" SG_ 389 BattTracClntFlw_Pc_Rq 1;
BA_ "U_CX727_MY2021_Rx" SG_ 389 HtrnAin_UHi_Actl 1;
BA_ "U_P702_MY2021_Rx" SG_ 389 HtrnAin_UHi_Actl 1;
BA_ "U_CD542_MY2021_Rx" SG_ 389 HtrnAin_UHi_Actl 1;
BA_ "U_CX727_MY2021_Rx" SG_ 389 HtrnHvilOpen_B_Actl 1;
BA_ "U_P702_MY2021_Rx" SG_ 389 HtrnHvilOpen_B_Actl 1;
BA_ "U_CD542_MY2021_Rx" SG_ 389 HtrnHvilOpen_B_Actl 1;
BA_ "U_CX727_MY2021_Rx" SG_ 389 PreCondActv_B_Actl 1;
BA_ "U_P702_MY2021_Rx" SG_ 389 PreCondActv_B_Actl 1;
BA_ "U_T6_MCA_MY2020_Rx" SG_ 389 PreCondActv_B_Actl 1;
BA_ "U_CD542_MY2021_Rx" SG_ 389 PreCondActv_B_Actl 1;
BA_ "U_U55X_MY2022_Rx" SG_ 389 PreCondActv_B_Actl 1;
BA_ "U_CD764_MY2022_Rx" SG_ 389 PreCondActv_B_Actl 1;
BA_ "GenSigStartValueInteger" SG_ 389 BattTrac_I_EstVsc 15000;
BA_ "U_CX727_MY2021_Rx" SG_ 389 BattTrac_I_EstVsc 1;
BA_ "U_P702_MY2021_Rx" SG_ 389 BattTrac_I_EstVsc 1;
BA_ "U_CD542_MY2021_Rx" SG_ 389 BattTrac_I_EstVsc 1;
BA_ "GenSigStartValue" SG_ 872 DcdcIn_Pw_Mx 115;
BA_ "GenSigStartValueInteger" SG_ 872 MtrPwLvl_Pc_Dsply 511;
BA_ "GenSigSendType" SG_ 945 KeyPadCodeDgt7_D_Dsply 3;
BA_ "U_CD764_MY2022_Tx" SG_ 945 KeyPadCodeDgt7_D_Dsply 1;
BA_ "WakeupSignal" SG_ 945 KeyPadCodeDgt6_D_Dsply 1;
BA_ "GenSigSendType" SG_ 945 KeyPadCodeDgt6_D_Dsply 3;
BA_ "U_CD764_MY2022_Tx" SG_ 945 KeyPadCodeDgt6_D_Dsply 1;
BA_ "WakeupSignal" SG_ 945 KeyPadCodeDgt5_D_Dsply 1;
BA_ "GenSigSendType" SG_ 945 KeyPadCodeDgt5_D_Dsply 3;
BA_ "U_CD764_MY2022_Tx" SG_ 945 KeyPadCodeDgt5_D_Dsply 1;
BA_ "WakeupSignal" SG_ 945 KeyPadCodeDgt4_D_Dsply 1;
BA_ "GenSigSendType" SG_ 945 KeyPadCodeDgt4_D_Dsply 3;
BA_ "U_CD764_MY2022_Tx" SG_ 945 KeyPadCodeDgt4_D_Dsply 1;
BA_ "WakeupSignal" SG_ 945 KeyPadCodeDgt3_D_Dsply 1;
BA_ "GenSigSendType" SG_ 945 KeyPadCodeDgt3_D_Dsply 3;
BA_ "U_CD764_MY2022_Tx" SG_ 945 KeyPadCodeDgt3_D_Dsply 1;
BA_ "WakeupSignal" SG_ 945 KeyPadCodeDgt2_D_Dsply 1;
BA_ "GenSigSendType" SG_ 945 KeyPadCodeDgt2_D_Dsply 3;
BA_ "U_CD764_MY2022_Tx" SG_ 945 KeyPadCodeDgt2_D_Dsply 1;
BA_ "WakeupSignal" SG_ 945 KeyPadCodeDgt1_D_Dsply 1;
BA_ "GenSigSendType" SG_ 945 KeyPadCodeDgt1_D_Dsply 3;
BA_ "U_CD764_MY2022_Tx" SG_ 945 KeyPadCodeDgt1_D_Dsply 1;
BA_ "WakeupSignal" SG_ 945 PwLoApim_T_Actl 1;
BA_ "GenSigSendType" SG_ 945 PwLoApim_T_Actl 3;
BA_ "U_CD764_MY2022_Tx" SG_ 945 PwLoApim_T_Actl 1;
BA_ "GenSigSendType" SG_ 945 KeyOffMde_D_Actl 3;
BA_ "U_T6_MCA_MY2020_Rx" SG_ 945 KeyOffMde_D_Actl 1;
BA_ "ECGUsedRxSignal" SG_ 945 KeyOffMde_D_Actl 1;
BA_ "U_CD542_MY2021_Rx" SG_ 945 KeyOffMde_D_Actl 1;
BA_ "U_U55X_MY2022_Rx" SG_ 945 KeyOffMde_D_Actl 1;
BA_ "U_CD764_MY2022_Rx" SG_ 945 KeyOffMde_D_Actl 1;
BA_ "U_CX727_MY2021_Rx" SG_ 945 KeyOffMde_D_Actl 1;
BA_ "U_P702_MY2021_Rx" SG_ 945 KeyOffMde_D_Actl 1;
BA_ "U_CX727_MY2021_Tx" SG_ 945 KeyOffMde_D_Actl 1;
BA_ "U_P702_MY2021_Tx" SG_ 945 KeyOffMde_D_Actl 1;
BA_ "U_T6_MCA_MY2020_Tx" SG_ 945 KeyOffMde_D_Actl 1;
BA_ "U_CD542_MY2021_Tx" SG_ 945 KeyOffMde_D_Actl 1;
BA_ "U_U55X_MY2022_Tx" SG_ 945 KeyOffMde_D_Actl 1;
BA_ "U_CD764_MY2022_Tx" SG_ 945 KeyOffMde_D_Actl 1;
BA_ "GenSigSendType" SG_ 945 PrkLckCtlLatch_B_Rq 3;
BA_ "U_T6_MCA_MY2020_Tx" SG_ 945 PrkLckCtlLatch_B_Rq 1;
BA_ "U_CD542_MY2021_Tx" SG_ 945 PrkLckCtlLatch_B_Rq 1;
BA_ "U_U55X_MY2022_Tx" SG_ 945 PrkLckCtlLatch_B_Rq 1;
BA_ "U_CD764_MY2022_Tx" SG_ 945 PrkLckCtlLatch_B_Rq 1;
BA_ "U_T6_MCA_MY2020_Rx" SG_ 985 PwSustnAdas_B_Rq 1;
BA_ "U_CD764_MY2022_Rx" SG_ 985 PwSustnAdas_B_Rq 1;
BA_ "GenSigStartValueInteger" SG_ 985 IaccVLimUnit_D_Rq 3;
BA_ "GenSigStartValue" SG_ 985 IaccVLimUnit_D_Rq 3;
BA_ "GenSigStartValueInteger" SG_ 985 IaccVLim_D_Rq 254;
BA_ "GenSigStartValue" SG_ 985 IaccVLim_D_Rq 254;
BA_ "GenSigStartValueInteger" SG_ 985 IsaVLim_D_Rq 254;
BA_ "GenSigStartValue" SG_ 985 IsaVLim_D_Rq 254;
BA_ "U_CX727_MY2021_Rx" SG_ 984 AhbcRampingV_D_Rq 1;
BA_ "U_P702_MY2021_Rx" SG_ 984 AhbcRampingV_D_Rq 1;
BA_ "U_T6_MCA_MY2020_Rx" SG_ 984 AhbcRampingV_D_Rq 1;
BA_ "U_CD542_MY2021_Rx" SG_ 984 AhbcRampingV_D_Rq 1;
BA_ "U_U55X_MY2022_Rx" SG_ 984 AhbcRampingV_D_Rq 1;
BA_ "U_CD764_MY2022_Rx" SG_ 984 AhbcRampingV_D_Rq 1;
BA_ "GenSigStartValueInteger" SG_ 984 PersIndexIpma_D_Actl 4;
BA_ "GenSigStartValue" SG_ 984 PersIndexIpma_D_Actl 4;
BA_ "GenSigStartValueInteger" SG_ 1055 EcoCochShif_Pc_Dsply 255;
BA_ "GenSigStartValue" SG_ 1055 EcoCochShif_Pc_Dsply 255;
BA_ "GenSigStartValueInteger" SG_ 1055 EcoCochInst_Pc_Dsply 1000;
BA_ "GenSigStartValue" SG_ 1055 EcoCochInst_Pc_Dsply 100;
BA_ "GenSigStartValueInteger" SG_ 1055 EcoCochIdlFuel_Pc_Dsply 255;
BA_ "GenSigStartValue" SG_ 1055 EcoCochIdlFuel_Pc_Dsply 255;
BA_ "GenSigStartValueInteger" SG_ 1055 EcoCochDecel_Pc_Dsply 255;
BA_ "GenSigStartValue" SG_ 1055 EcoCochDecel_Pc_Dsply 255;
BA_ "GenSigStartValueInteger" SG_ 1055 EcoCochCrus_Pc_Dsply 255;
BA_ "GenSigStartValue" SG_ 1055 EcoCochCrus_Pc_Dsply 255;
BA_ "GenSigStartValueInteger" SG_ 1055 EcoCochA_Pc_Dsply 255;
BA_ "GenSigStartValue" SG_ 1055 EcoCochA_Pc_Dsply 255;
BA_ "WakeupSignal" SG_ 135 McGlblClkDay_No_Rq 1;
BA_ "U_CX727_MY2021_Rx" SG_ 135 McGlblClkDay_No_Rq 1;
BA_ "U_P702_MY2021_Rx" SG_ 135 McGlblClkDay_No_Rq 1;
BA_ "U_T6_MCA_MY2020_Rx" SG_ 135 McGlblClkDay_No_Rq 1;
BA_ "U_CD542_MY2021_Rx" SG_ 135 McGlblClkDay_No_Rq 1;
BA_ "U_U55X_MY2022_Rx" SG_ 135 McGlblClkDay_No_Rq 1;
BA_ "U_CD764_MY2022_Rx" SG_ 135 McGlblClkDay_No_Rq 1;
BA_ "WakeupSignal" SG_ 135 McGlblClkYr_No_Rq 1;
BA_ "U_CX727_MY2021_Rx" SG_ 135 McGlblClkYr_No_Rq 1;
BA_ "U_P702_MY2021_Rx" SG_ 135 McGlblClkYr_No_Rq 1;
BA_ "U_T6_MCA_MY2020_Rx" SG_ 135 McGlblClkYr_No_Rq 1;
BA_ "U_CD542_MY2021_Rx" SG_ 135 McGlblClkYr_No_Rq 1;
BA_ "U_U55X_MY2022_Rx" SG_ 135 McGlblClkYr_No_Rq 1;
BA_ "U_CD764_MY2022_Rx" SG_ 135 McGlblClkYr_No_Rq 1;
BA_ "WakeupSignal" SG_ 135 McGlblClkScnd_No_Rq 1;
BA_ "U_CX727_MY2021_Rx" SG_ 135 McGlblClkScnd_No_Rq 1;
BA_ "U_P702_MY2021_Rx" SG_ 135 McGlblClkScnd_No_Rq 1;
BA_ "U_T6_MCA_MY2020_Rx" SG_ 135 McGlblClkScnd_No_Rq 1;
BA_ "U_CD542_MY2021_Rx" SG_ 135 McGlblClkScnd_No_Rq 1;
BA_ "U_U55X_MY2022_Rx" SG_ 135 McGlblClkScnd_No_Rq 1;
BA_ "U_CD764_MY2022_Rx" SG_ 135 McGlblClkScnd_No_Rq 1;
BA_ "WakeupSignal" SG_ 135 McGlblClkMnte_No_Rq 1;
BA_ "U_CX727_MY2021_Rx" SG_ 135 McGlblClkMnte_No_Rq 1;
BA_ "U_P702_MY2021_Rx" SG_ 135 McGlblClkMnte_No_Rq 1;
BA_ "U_T6_MCA_MY2020_Rx" SG_ 135 McGlblClkMnte_No_Rq 1;
BA_ "U_CD542_MY2021_Rx" SG_ 135 McGlblClkMnte_No_Rq 1;
BA_ "U_U55X_MY2022_Rx" SG_ 135 McGlblClkMnte_No_Rq 1;
BA_ "U_CD764_MY2022_Rx" SG_ 135 McGlblClkMnte_No_Rq 1;
BA_ "WakeupSignal" SG_ 135 McGlblClkHr_No_Rq 1;
BA_ "U_CX727_MY2021_Rx" SG_ 135 McGlblClkHr_No_Rq 1;
BA_ "U_P702_MY2021_Rx" SG_ 135 McGlblClkHr_No_Rq 1;
BA_ "U_T6_MCA_MY2020_Rx" SG_ 135 McGlblClkHr_No_Rq 1;
BA_ "U_CD542_MY2021_Rx" SG_ 135 McGlblClkHr_No_Rq 1;
BA_ "U_U55X_MY2022_Rx" SG_ 135 McGlblClkHr_No_Rq 1;
BA_ "U_CD764_MY2022_Rx" SG_ 135 McGlblClkHr_No_Rq 1;
BA_ "WakeupSignal" SG_ 135 McGlblClkAdj_B_Rq 1;
BA_ "U_CX727_MY2021_Rx" SG_ 135 McGlblClkAdj_B_Rq 1;
BA_ "U_P702_MY2021_Rx" SG_ 135 McGlblClkAdj_B_Rq 1;
BA_ "U_T6_MCA_MY2020_Rx" SG_ 135 McGlblClkAdj_B_Rq 1;
BA_ "U_CD542_MY2021_Rx" SG_ 135 McGlblClkAdj_B_Rq 1;
BA_ "U_U55X_MY2022_Rx" SG_ 135 McGlblClkAdj_B_Rq 1;
BA_ "U_CD764_MY2022_Rx" SG_ 135 McGlblClkAdj_B_Rq 1;
BA_ "WakeupSignal" SG_ 134 DispGlblClkYr_No_Rq 1;
BA_ "U_CX727_MY2021_Rx" SG_ 134 DispGlblClkYr_No_Rq 1;
BA_ "U_P702_MY2021_Rx" SG_ 134 DispGlblClkYr_No_Rq 1;
BA_ "U_T6_MCA_MY2020_Rx" SG_ 134 DispGlblClkYr_No_Rq 1;
BA_ "U_CD542_MY2021_Rx" SG_ 134 DispGlblClkYr_No_Rq 1;
BA_ "U_U55X_MY2022_Rx" SG_ 134 DispGlblClkYr_No_Rq 1;
BA_ "U_CD764_MY2022_Rx" SG_ 134 DispGlblClkYr_No_Rq 1;
BA_ "WakeupSignal" SG_ 134 DispGlblClkScnd_No_Rq 1;
BA_ "U_CX727_MY2021_Rx" SG_ 134 DispGlblClkScnd_No_Rq 1;
BA_ "U_P702_MY2021_Rx" SG_ 134 DispGlblClkScnd_No_Rq 1;
BA_ "U_T6_MCA_MY2020_Rx" SG_ 134 DispGlblClkScnd_No_Rq 1;
BA_ "U_CD542_MY2021_Rx" SG_ 134 DispGlblClkScnd_No_Rq 1;
BA_ "U_U55X_MY2022_Rx" SG_ 134 DispGlblClkScnd_No_Rq 1;
BA_ "U_CD764_MY2022_Rx" SG_ 134 DispGlblClkScnd_No_Rq 1;
BA_ "WakeupSignal" SG_ 134 DispGlblClkMnte_No_Rq 1;
BA_ "U_CX727_MY2021_Rx" SG_ 134 DispGlblClkMnte_No_Rq 1;
BA_ "U_P702_MY2021_Rx" SG_ 134 DispGlblClkMnte_No_Rq 1;
BA_ "U_T6_MCA_MY2020_Rx" SG_ 134 DispGlblClkMnte_No_Rq 1;
BA_ "U_CD542_MY2021_Rx" SG_ 134 DispGlblClkMnte_No_Rq 1;
BA_ "U_U55X_MY2022_Rx" SG_ 134 DispGlblClkMnte_No_Rq 1;
BA_ "U_CD764_MY2022_Rx" SG_ 134 DispGlblClkMnte_No_Rq 1;
BA_ "WakeupSignal" SG_ 134 DispGlblClkHr_No_Rq 1;
BA_ "U_CX727_MY2021_Rx" SG_ 134 DispGlblClkHr_No_Rq 1;
BA_ "U_P702_MY2021_Rx" SG_ 134 DispGlblClkHr_No_Rq 1;
BA_ "U_T6_MCA_MY2020_Rx" SG_ 134 DispGlblClkHr_No_Rq 1;
BA_ "U_CD542_MY2021_Rx" SG_ 134 DispGlblClkHr_No_Rq 1;
BA_ "U_U55X_MY2022_Rx" SG_ 134 DispGlblClkHr_No_Rq 1;
BA_ "U_CD764_MY2022_Rx" SG_ 134 DispGlblClkHr_No_Rq 1;
BA_ "WakeupSignal" SG_ 134 DispGlblClkDay_No_Rq 1;
BA_ "U_CX727_MY2021_Rx" SG_ 134 DispGlblClkDay_No_Rq 1;
BA_ "U_P702_MY2021_Rx" SG_ 134 DispGlblClkDay_No_Rq 1;
BA_ "U_T6_MCA_MY2020_Rx" SG_ 134 DispGlblClkDay_No_Rq 1;
BA_ "U_CD542_MY2021_Rx" SG_ 134 DispGlblClkDay_No_Rq 1;
BA_ "U_U55X_MY2022_Rx" SG_ 134 DispGlblClkDay_No_Rq 1;
BA_ "U_CD764_MY2022_Rx" SG_ 134 DispGlblClkDay_No_Rq 1;
BA_ "WakeupSignal" SG_ 134 DispGlblClkAdj_B_Rq 1;
BA_ "U_CX727_MY2021_Rx" SG_ 134 DispGlblClkAdj_B_Rq 1;
BA_ "U_P702_MY2021_Rx" SG_ 134 DispGlblClkAdj_B_Rq 1;
BA_ "U_T6_MCA_MY2020_Rx" SG_ 134 DispGlblClkAdj_B_Rq 1;
BA_ "U_CD542_MY2021_Rx" SG_ 134 DispGlblClkAdj_B_Rq 1;
BA_ "U_U55X_MY2022_Rx" SG_ 134 DispGlblClkAdj_B_Rq 1;
BA_ "U_CD764_MY2022_Rx" SG_ 134 DispGlblClkAdj_B_Rq 1;
BA_ "U_CX727_MY2021_Tx" SG_ 132 GlblClkYr_No_Actl 1;
BA_ "U_P702_MY2021_Tx" SG_ 132 GlblClkYr_No_Actl 1;
BA_ "U_T6_MCA_MY2020_Tx" SG_ 132 GlblClkYr_No_Actl 1;
BA_ "U_CD542_MY2021_Tx" SG_ 132 GlblClkYr_No_Actl 1;
BA_ "U_U55X_MY2022_Tx" SG_ 132 GlblClkYr_No_Actl 1;
BA_ "U_CD764_MY2022_Tx" SG_ 132 GlblClkYr_No_Actl 1;
BA_ "GenSigSendType" SG_ 132 GlblClkScnd_No_Actl 3;
BA_ "U_CX727_MY2021_Tx" SG_ 132 GlblClkScnd_No_Actl 1;
BA_ "U_P702_MY2021_Tx" SG_ 132 GlblClkScnd_No_Actl 1;
BA_ "U_T6_MCA_MY2020_Tx" SG_ 132 GlblClkScnd_No_Actl 1;
BA_ "U_CD542_MY2021_Tx" SG_ 132 GlblClkScnd_No_Actl 1;
BA_ "U_U55X_MY2022_Tx" SG_ 132 GlblClkScnd_No_Actl 1;
BA_ "U_CD764_MY2022_Tx" SG_ 132 GlblClkScnd_No_Actl 1;
BA_ "U_CX727_MY2021_Tx" SG_ 132 GlblClkMnte_No_Actl 1;
BA_ "U_P702_MY2021_Tx" SG_ 132 GlblClkMnte_No_Actl 1;
BA_ "U_T6_MCA_MY2020_Tx" SG_ 132 GlblClkMnte_No_Actl 1;
BA_ "U_CD542_MY2021_Tx" SG_ 132 GlblClkMnte_No_Actl 1;
BA_ "U_U55X_MY2022_Tx" SG_ 132 GlblClkMnte_No_Actl 1;
BA_ "U_CD764_MY2022_Tx" SG_ 132 GlblClkMnte_No_Actl 1;
BA_ "U_CX727_MY2021_Tx" SG_ 132 GlblClkHr_No_Actl 1;
BA_ "U_P702_MY2021_Tx" SG_ 132 GlblClkHr_No_Actl 1;
BA_ "U_T6_MCA_MY2020_Tx" SG_ 132 GlblClkHr_No_Actl 1;
BA_ "U_CD542_MY2021_Tx" SG_ 132 GlblClkHr_No_Actl 1;
BA_ "U_U55X_MY2022_Tx" SG_ 132 GlblClkHr_No_Actl 1;
BA_ "U_CD764_MY2022_Tx" SG_ 132 GlblClkHr_No_Actl 1;
BA_ "U_CX727_MY2021_Tx" SG_ 132 GlblClkDay_No_Actl 1;
BA_ "U_P702_MY2021_Tx" SG_ 132 GlblClkDay_No_Actl 1;
BA_ "U_T6_MCA_MY2020_Tx" SG_ 132 GlblClkDay_No_Actl 1;
BA_ "U_CD542_MY2021_Tx" SG_ 132 GlblClkDay_No_Actl 1;
BA_ "U_U55X_MY2022_Tx" SG_ 132 GlblClkDay_No_Actl 1;
BA_ "U_CD764_MY2022_Tx" SG_ 132 GlblClkDay_No_Actl 1;
BA_ "WakeupSignal" SG_ 836 Foh_D_Stat 1;
BA_ "ContentDependant" SG_ 836 Foh_D_Stat 1;
BA_ "U_CX727_MY2021_Rx" SG_ 836 Foh_D_Stat 1;
BA_ "U_P702_MY2021_Rx" SG_ 836 Foh_D_Stat 1;
BA_ "U_T6_MCA_MY2020_Rx" SG_ 836 Foh_D_Stat 1;
BA_ "U_CD542_MY2021_Rx" SG_ 836 Foh_D_Stat 1;
BA_ "U_U55X_MY2022_Rx" SG_ 836 Foh_D_Stat 1;
BA_ "U_CD764_MY2022_Rx" SG_ 836 Foh_D_Stat 1;
BA_ "ContentDependant" SG_ 836 FuelFlw_Vl_ActlFoh 1;
BA_ "ContentDependant" SG_ 836 EngClnt_Te_ActlFoh 1;
BA_ "ContentDependant" SG_ 836 FohFalt_D_Stat 1;
BA_ "ContentDependant" SG_ 836 FohEnbl_B_RqDrv 1;
BA_ "ContentDependant" SG_ 836 FohRqRun_B_Rq 1;
BA_ "WakeupSignal" SG_ 836 HvacPrecondMode_D_Rq 1;
BA_ "ContentDependant" SG_ 836 HvacPrecondMode_D_Rq 1;
BA_ "WakeupSignal" SG_ 836 HvacPrecondBlwr_D_Rq 1;
BA_ "ContentDependant" SG_ 836 HvacPrecondBlwr_D_Rq 1;
BA_ "U_CX727_MY2021_Rx" SG_ 939 PrkAidSnsRlSide_D_Stat 1;
BA_ "U_P702_MY2021_Rx" SG_ 939 PrkAidSnsRlSide_D_Stat 1;
BA_ "U_T6_MCA_MY2020_Rx" SG_ 939 PrkAidSnsRlSide_D_Stat 1;
BA_ "U_CD542_MY2021_Rx" SG_ 939 PrkAidSnsRlSide_D_Stat 1;
BA_ "U_U55X_MY2022_Rx" SG_ 939 PrkAidSnsRlSide_D_Stat 1;
BA_ "U_CD764_MY2022_Rx" SG_ 939 PrkAidSnsRlSide_D_Stat 1;
BA_ "GenSigSendType" SG_ 939 SidePrkSnsR4_D_Stat 3;
BA_ "GenSigSendType" SG_ 939 SidePrkSnsR3_D_Stat 3;
BA_ "GenSigSendType" SG_ 939 SidePrkSnsL4_D_Stat 3;
BA_ "GenSigSendType" SG_ 939 SidePrkSnsL3_D_Stat 3;
BA_ "U_CX727_MY2021_Rx" SG_ 939 PrkAidSnsRrSide_D_Stat 1;
BA_ "U_P702_MY2021_Rx" SG_ 939 PrkAidSnsRrSide_D_Stat 1;
BA_ "U_T6_MCA_MY2020_Rx" SG_ 939 PrkAidSnsRrSide_D_Stat 1;
BA_ "U_CD542_MY2021_Rx" SG_ 939 PrkAidSnsRrSide_D_Stat 1;
BA_ "U_U55X_MY2022_Rx" SG_ 939 PrkAidSnsRrSide_D_Stat 1;
BA_ "U_CD764_MY2022_Rx" SG_ 939 PrkAidSnsRrSide_D_Stat 1;
BA_ "GenSigSendType" SG_ 939 PrkAidChime_D_Stat 3;
BA_ "GenSigSendType" SG_ 939 PrkAidSnsRlCntr_D_Stat 3;
BA_ "U_CX727_MY2021_Rx" SG_ 939 PrkAidSnsRlCntr_D_Stat 1;
BA_ "U_P702_MY2021_Rx" SG_ 939 PrkAidSnsRlCntr_D_Stat 1;
BA_ "U_T6_MCA_MY2020_Rx" SG_ 939 PrkAidSnsRlCntr_D_Stat 1;
BA_ "U_CD542_MY2021_Rx" SG_ 939 PrkAidSnsRlCntr_D_Stat 1;
BA_ "U_U55X_MY2022_Rx" SG_ 939 PrkAidSnsRlCntr_D_Stat 1;
BA_ "U_CD764_MY2022_Rx" SG_ 939 PrkAidSnsRlCntr_D_Stat 1;
BA_ "GenSigSendType" SG_ 939 PrkAidSnsRrCrnr_D_Stat 3;
BA_ "U_CX727_MY2021_Rx" SG_ 939 PrkAidSnsRrCrnr_D_Stat 1;
BA_ "U_P702_MY2021_Rx" SG_ 939 PrkAidSnsRrCrnr_D_Stat 1;
BA_ "U_T6_MCA_MY2020_Rx" SG_ 939 PrkAidSnsRrCrnr_D_Stat 1;
BA_ "U_CD542_MY2021_Rx" SG_ 939 PrkAidSnsRrCrnr_D_Stat 1;
BA_ "U_U55X_MY2022_Rx" SG_ 939 PrkAidSnsRrCrnr_D_Stat 1;
BA_ "U_CD764_MY2022_Rx" SG_ 939 PrkAidSnsRrCrnr_D_Stat 1;
BA_ "GenSigSendType" SG_ 939 PrkAidSnsRrCntr_D_Stat 3;
BA_ "U_CX727_MY2021_Rx" SG_ 939 PrkAidSnsRrCntr_D_Stat 1;
BA_ "U_P702_MY2021_Rx" SG_ 939 PrkAidSnsRrCntr_D_Stat 1;
BA_ "U_T6_MCA_MY2020_Rx" SG_ 939 PrkAidSnsRrCntr_D_Stat 1;
BA_ "U_CD542_MY2021_Rx" SG_ 939 PrkAidSnsRrCntr_D_Stat 1;
BA_ "U_U55X_MY2022_Rx" SG_ 939 PrkAidSnsRrCntr_D_Stat 1;
BA_ "U_CD764_MY2022_Rx" SG_ 939 PrkAidSnsRrCntr_D_Stat 1;
BA_ "GenSigSendType" SG_ 939 PrkAidSnsRlCrnr_D_Stat 3;
BA_ "U_CX727_MY2021_Rx" SG_ 939 PrkAidSnsRlCrnr_D_Stat 1;
BA_ "U_P702_MY2021_Rx" SG_ 939 PrkAidSnsRlCrnr_D_Stat 1;
BA_ "U_T6_MCA_MY2020_Rx" SG_ 939 PrkAidSnsRlCrnr_D_Stat 1;
BA_ "U_CD542_MY2021_Rx" SG_ 939 PrkAidSnsRlCrnr_D_Stat 1;
BA_ "U_U55X_MY2022_Rx" SG_ 939 PrkAidSnsRlCrnr_D_Stat 1;
BA_ "U_CD764_MY2022_Rx" SG_ 939 PrkAidSnsRlCrnr_D_Stat 1;
BA_ "GenSigSendType" SG_ 939 PrkAidRear_D_Stat 3;
BA_ "GenSigSendType" SG_ 939 PrkAidFront_D_Stat 3;
BA_ "GenSigSendType" SG_ 939 PrkAid_D_Falt 3;
BA_ "U_CX727_MY2021_Rx" SG_ 939 PrkAid_D_Falt 1;
BA_ "U_P702_MY2021_Rx" SG_ 939 PrkAid_D_Falt 1;
BA_ "U_T6_MCA_MY2020_Rx" SG_ 939 PrkAid_D_Falt 1;
BA_ "U_CD542_MY2021_Rx" SG_ 939 PrkAid_D_Falt 1;
BA_ "U_U55X_MY2022_Rx" SG_ 939 PrkAid_D_Falt 1;
BA_ "U_CD764_MY2022_Rx" SG_ 939 PrkAid_D_Falt 1;
BA_ "GenSigSendType" SG_ 939 ApaLongCtrlEnbl_D_Rq 3;
BA_ "U_T6_MCA_MY2020_Rx" SG_ 939 ApaLongCtrlEnbl_D_Rq 1;
BA_ "U_U55X_MY2022_Rx" SG_ 939 ApaLongCtrlEnbl_D_Rq 1;
BA_ "GenSigStartValueInteger" SG_ 939 ApaBrk_A_Rq 255;
BA_ "GenSigStartValue" SG_ 939 ApaBrk_A_Rq 255;
BA_ "GenSigSendType" SG_ 939 PrkAidLamp_D_Rq 3;
BA_ "GenSigStartValueInteger" SG_ 952 Tire_Press_IRR_Data 65533;
BA_ "GenSigStartValue" SG_ 952 Tire_Press_IRR_Data 65533;
BA_ "U_T6_MCA_MY2020_Rx" SG_ 952 Tire_Press_IRR_Data 1;
BA_ "ECGUsedRxSignal" SG_ 952 Tire_Press_IRR_Data 1;
BA_ "U_CD542_MY2021_Rx" SG_ 952 Tire_Press_IRR_Data 1;
BA_ "U_U55X_MY2022_Rx" SG_ 952 Tire_Press_IRR_Data 1;
BA_ "U_CD764_MY2022_Rx" SG_ 952 Tire_Press_IRR_Data 1;
BA_ "U_CX727_MY2021_Tx" SG_ 952 Tire_Press_IRR_Data 1;
BA_ "U_P702_MY2021_Tx" SG_ 952 Tire_Press_IRR_Data 1;
BA_ "U_T6_MCA_MY2020_Tx" SG_ 952 Tire_Press_IRR_Data 1;
BA_ "U_CD542_MY2021_Tx" SG_ 952 Tire_Press_IRR_Data 1;
BA_ "U_U55X_MY2022_Tx" SG_ 952 Tire_Press_IRR_Data 1;
BA_ "U_CD764_MY2022_Tx" SG_ 952 Tire_Press_IRR_Data 1;
BA_ "GenSigStartValueInteger" SG_ 952 Tire_Press_ILR_Data 65533;
BA_ "GenSigStartValue" SG_ 952 Tire_Press_ILR_Data 65533;
BA_ "U_T6_MCA_MY2020_Rx" SG_ 952 Tire_Press_ILR_Data 1;
BA_ "ECGUsedRxSignal" SG_ 952 Tire_Press_ILR_Data 1;
BA_ "U_CD542_MY2021_Rx" SG_ 952 Tire_Press_ILR_Data 1;
BA_ "U_U55X_MY2022_Rx" SG_ 952 Tire_Press_ILR_Data 1;
BA_ "U_CD764_MY2022_Rx" SG_ 952 Tire_Press_ILR_Data 1;
BA_ "U_CX727_MY2021_Tx" SG_ 952 Tire_Press_ILR_Data 1;
BA_ "U_P702_MY2021_Tx" SG_ 952 Tire_Press_ILR_Data 1;
BA_ "U_T6_MCA_MY2020_Tx" SG_ 952 Tire_Press_ILR_Data 1;
BA_ "U_CD542_MY2021_Tx" SG_ 952 Tire_Press_ILR_Data 1;
BA_ "U_U55X_MY2022_Tx" SG_ 952 Tire_Press_ILR_Data 1;
BA_ "U_CD764_MY2022_Tx" SG_ 952 Tire_Press_ILR_Data 1;
BA_ "GenSigSendType" SG_ 374 GearEngag_D_Actl 3;
BA_ "GenSigStartValueInteger" SG_ 374 TrnRng_D_Rq 14;
BA_ "ContentDependant" SG_ 374 TrnRng_D_Rq 1;
BA_ "GenSigStartValue" SG_ 374 TrnRng_D_Rq 14;
BA_ "GenSigSendType" SG_ 374 TrnRng_D_Rq 3;
BA_ "U_CX727_MY2021_Rx" SG_ 374 TrnRng_D_Rq 1;
BA_ "U_U55X_MY2022_Rx" SG_ 374 TrnRng_D_Rq 1;
BA_ "U_CD542_MY2021_Rx" SG_ 374 TrnRng_D_Rq 1;
BA_ "ContentDependant" SG_ 374 TrnPrkSys_D_Actl 1;
BA_ "GenSigSendType" SG_ 374 TrnPrkSys_D_Actl 3;
BA_ "U_CX727_MY2021_Rx" SG_ 374 TrnPrkSys_D_Actl 1;
BA_ "U_P702_MY2021_Rx" SG_ 374 TrnPrkSys_D_Actl 1;
BA_ "U_T6_MCA_MY2020_Rx" SG_ 374 TrnPrkSys_D_Actl 1;
BA_ "U_CD542_MY2021_Rx" SG_ 374 TrnPrkSys_D_Actl 1;
BA_ "U_U55X_MY2022_Rx" SG_ 374 TrnPrkSys_D_Actl 1;
BA_ "U_CD764_MY2022_Rx" SG_ 374 TrnPrkSys_D_Actl 1;
BA_ "ContentDependant" SG_ 374 GearLvr_D_ActlDrv 1;
BA_ "GenSigSendType" SG_ 374 GearLvr_D_ActlDrv 3;
BA_ "U_CX727_MY2021_Rx" SG_ 374 GearLvr_D_ActlDrv 1;
BA_ "U_U55X_MY2022_Rx" SG_ 374 GearLvr_D_ActlDrv 1;
BA_ "ContentDependant" SG_ 374 GearPos_No_Cs 1;
BA_ "MetaData" SG_ 374 GearPos_No_Cs 1;
BA_ "U_CX727_MY2021_Rx" SG_ 374 GearPos_No_Cs 1;
BA_ "U_U55X_MY2022_Rx" SG_ 374 GearPos_No_Cs 1;
BA_ "GenSigStartValueInteger" SG_ 374 GearPos_D_Trg 15;
BA_ "ContentDependant" SG_ 374 GearPos_D_Trg 1;
BA_ "GenSigStartValue" SG_ 374 GearPos_D_Trg 15;
BA_ "GenSigSendType" SG_ 374 GearPos_D_Trg 3;
BA_ "U_CX727_MY2021_Rx" SG_ 374 GearPos_D_Trg 1;
BA_ "U_U55X_MY2022_Rx" SG_ 374 GearPos_D_Trg 1;
BA_ "ContentDependant" SG_ 374 GearPos_No_Cnt 1;
BA_ "MetaData" SG_ 374 GearPos_No_Cnt 1;
BA_ "U_CX727_MY2021_Rx" SG_ 374 GearPos_No_Cnt 1;
BA_ "U_U55X_MY2022_Rx" SG_ 374 GearPos_No_Cnt 1;
BA_ "U_CX727_MY2021_Rx" SG_ 374 TrnIgnOffDly_T_Rq 1;
BA_ "U_P702_MY2021_Rx" SG_ 374 TrnIgnOffDly_T_Rq 1;
BA_ "U_T6_MCA_MY2020_Rx" SG_ 374 TrnIgnOffDly_T_Rq 1;
BA_ "U_CD542_MY2021_Rx" SG_ 374 TrnIgnOffDly_T_Rq 1;
BA_ "U_U55X_MY2022_Rx" SG_ 374 TrnIgnOffDly_T_Rq 1;
BA_ "U_CD764_MY2022_Rx" SG_ 374 TrnIgnOffDly_T_Rq 1;
BA_ "GenSigStartValueInteger" SG_ 374 GearPos_D_Actl 15;
BA_ "ContentDependant" SG_ 374 GearPos_D_Actl 1;
BA_ "GenSigStartValue" SG_ 374 GearPos_D_Actl 15;
BA_ "GenSigSendType" SG_ 374 GearPos_D_Actl 3;
BA_ "U_CX727_MY2021_Rx" SG_ 374 GearPos_D_Actl 1;
BA_ "U_U55X_MY2022_Rx" SG_ 374 GearPos_D_Actl 1;
BA_ "GenSigSendType" SG_ 1095 Pers4Phone_D_Stat 3;
BA_ "U_CX727_MY2021_Tx" SG_ 1095 Pers4Phone_D_Stat 1;
BA_ "U_P702_MY2021_Tx" SG_ 1095 Pers4Phone_D_Stat 1;
BA_ "U_T6_MCA_MY2020_Tx" SG_ 1095 Pers4Phone_D_Stat 1;
BA_ "U_CD542_MY2021_Tx" SG_ 1095 Pers4Phone_D_Stat 1;
BA_ "U_U55X_MY2022_Tx" SG_ 1095 Pers4Phone_D_Stat 1;
BA_ "U_CD764_MY2022_Tx" SG_ 1095 Pers4Phone_D_Stat 1;
BA_ "GenSigSendType" SG_ 1095 Pers3Phone_D_Stat 3;
BA_ "U_CX727_MY2021_Tx" SG_ 1095 Pers3Phone_D_Stat 1;
BA_ "U_P702_MY2021_Tx" SG_ 1095 Pers3Phone_D_Stat 1;
BA_ "U_T6_MCA_MY2020_Tx" SG_ 1095 Pers3Phone_D_Stat 1;
BA_ "U_CD542_MY2021_Tx" SG_ 1095 Pers3Phone_D_Stat 1;
BA_ "U_U55X_MY2022_Tx" SG_ 1095 Pers3Phone_D_Stat 1;
BA_ "U_CD764_MY2022_Tx" SG_ 1095 Pers3Phone_D_Stat 1;
BA_ "GenSigSendType" SG_ 1095 Pers2Phone_D_Stat 3;
BA_ "U_CX727_MY2021_Tx" SG_ 1095 Pers2Phone_D_Stat 1;
BA_ "U_P702_MY2021_Tx" SG_ 1095 Pers2Phone_D_Stat 1;
BA_ "U_T6_MCA_MY2020_Tx" SG_ 1095 Pers2Phone_D_Stat 1;
BA_ "U_CD542_MY2021_Tx" SG_ 1095 Pers2Phone_D_Stat 1;
BA_ "U_U55X_MY2022_Tx" SG_ 1095 Pers2Phone_D_Stat 1;
BA_ "U_CD764_MY2022_Tx" SG_ 1095 Pers2Phone_D_Stat 1;
BA_ "GenSigSendType" SG_ 1095 Pers1Phone_D_Stat 3;
BA_ "U_CX727_MY2021_Tx" SG_ 1095 Pers1Phone_D_Stat 1;
BA_ "U_P702_MY2021_Tx" SG_ 1095 Pers1Phone_D_Stat 1;
BA_ "U_T6_MCA_MY2020_Tx" SG_ 1095 Pers1Phone_D_Stat 1;
BA_ "U_CD542_MY2021_Tx" SG_ 1095 Pers1Phone_D_Stat 1;
BA_ "U_U55X_MY2022_Tx" SG_ 1095 Pers1Phone_D_Stat 1;
BA_ "U_CD764_MY2022_Tx" SG_ 1095 Pers1Phone_D_Stat 1;
BA_ "WakeupSignal" SG_ 1095 HeadLghtOn_D_Rq 1;
BA_ "GenSigStartValueInteger" SG_ 1095 HeadLghtOn_D_Rq 1;
BA_ "GenSigStartValue" SG_ 1095 HeadLghtOn_D_Rq 1;
BA_ "GenSigSendType" SG_ 1095 HeadLghtOn_D_Rq 3;
BA_ "U_CX727_MY2021_Tx" SG_ 1095 HeadLghtOn_D_Rq 1;
BA_ "U_P702_MY2021_Tx" SG_ 1095 HeadLghtOn_D_Rq 1;
BA_ "U_T6_MCA_MY2020_Tx" SG_ 1095 HeadLghtOn_D_Rq 1;
BA_ "U_CD542_MY2021_Tx" SG_ 1095 HeadLghtOn_D_Rq 1;
BA_ "U_U55X_MY2022_Tx" SG_ 1095 HeadLghtOn_D_Rq 1;
BA_ "U_CD764_MY2022_Tx" SG_ 1095 HeadLghtOn_D_Rq 1;
BA_ "GenSigSendType" SG_ 1095 RstrtSetting_T_Actl 3;
BA_ "U_T6_MCA_MY2020_Rx" SG_ 1095 RstrtSetting_T_Actl 1;
BA_ "ECGUsedRxSignal" SG_ 1095 RstrtSetting_T_Actl 1;
BA_ "U_CD542_MY2021_Rx" SG_ 1095 RstrtSetting_T_Actl 1;
BA_ "U_U55X_MY2022_Rx" SG_ 1095 RstrtSetting_T_Actl 1;
BA_ "U_CD764_MY2022_Rx" SG_ 1095 RstrtSetting_T_Actl 1;
BA_ "U_CX727_MY2021_Tx" SG_ 1095 RstrtSetting_T_Actl 1;
BA_ "U_P702_MY2021_Tx" SG_ 1095 RstrtSetting_T_Actl 1;
BA_ "U_T6_MCA_MY2020_Tx" SG_ 1095 RstrtSetting_T_Actl 1;
BA_ "U_CD542_MY2021_Tx" SG_ 1095 RstrtSetting_T_Actl 1;
BA_ "U_U55X_MY2022_Tx" SG_ 1095 RstrtSetting_T_Actl 1;
BA_ "U_CD764_MY2022_Tx" SG_ 1095 RstrtSetting_T_Actl 1;
BA_ "GenSigSendType" SG_ 1095 PepsKeyActv_D_Stat 3;
BA_ "U_T6_MCA_MY2020_Rx" SG_ 1095 PepsKeyActv_D_Stat 1;
BA_ "ECGUsedRxSignal" SG_ 1095 PepsKeyActv_D_Stat 1;
BA_ "U_CD542_MY2021_Rx" SG_ 1095 PepsKeyActv_D_Stat 1;
BA_ "U_U55X_MY2022_Rx" SG_ 1095 PepsKeyActv_D_Stat 1;
BA_ "U_CD764_MY2022_Rx" SG_ 1095 PepsKeyActv_D_Stat 1;
BA_ "U_CX727_MY2021_Tx" SG_ 1095 PepsKeyActv_D_Stat 1;
BA_ "U_P702_MY2021_Tx" SG_ 1095 PepsKeyActv_D_Stat 1;
BA_ "U_T6_MCA_MY2020_Tx" SG_ 1095 PepsKeyActv_D_Stat 1;
BA_ "U_CD542_MY2021_Tx" SG_ 1095 PepsKeyActv_D_Stat 1;
BA_ "U_U55X_MY2022_Tx" SG_ 1095 PepsKeyActv_D_Stat 1;
BA_ "U_CD764_MY2022_Tx" SG_ 1095 PepsKeyActv_D_Stat 1;
BA_ "GenSigSendType" SG_ 1095 Rstrt_T_Actl 3;
BA_ "U_T6_MCA_MY2020_Rx" SG_ 1095 Rstrt_T_Actl 1;
BA_ "ECGUsedRxSignal" SG_ 1095 Rstrt_T_Actl 1;
BA_ "U_CD542_MY2021_Rx" SG_ 1095 Rstrt_T_Actl 1;
BA_ "U_U55X_MY2022_Rx" SG_ 1095 Rstrt_T_Actl 1;
BA_ "U_CD764_MY2022_Rx" SG_ 1095 Rstrt_T_Actl 1;
BA_ "U_CX727_MY2021_Tx" SG_ 1095 Rstrt_T_Actl 1;
BA_ "U_P702_MY2021_Tx" SG_ 1095 Rstrt_T_Actl 1;
BA_ "U_T6_MCA_MY2020_Tx" SG_ 1095 Rstrt_T_Actl 1;
BA_ "U_CD542_MY2021_Tx" SG_ 1095 Rstrt_T_Actl 1;
BA_ "U_U55X_MY2022_Tx" SG_ 1095 Rstrt_T_Actl 1;
BA_ "U_CD764_MY2022_Tx" SG_ 1095 Rstrt_T_Actl 1;
BA_ "GenSigSendType" SG_ 1095 PepsKeyFound_No_Actl 3;
BA_ "U_T6_MCA_MY2020_Rx" SG_ 1095 PepsKeyFound_No_Actl 1;
BA_ "ECGUsedRxSignal" SG_ 1095 PepsKeyFound_No_Actl 1;
BA_ "U_CD542_MY2021_Rx" SG_ 1095 PepsKeyFound_No_Actl 1;
BA_ "U_U55X_MY2022_Rx" SG_ 1095 PepsKeyFound_No_Actl 1;
BA_ "U_CD764_MY2022_Rx" SG_ 1095 PepsKeyFound_No_Actl 1;
BA_ "U_CX727_MY2021_Tx" SG_ 1095 PepsKeyFound_No_Actl 1;
BA_ "U_P702_MY2021_Tx" SG_ 1095 PepsKeyFound_No_Actl 1;
BA_ "U_T6_MCA_MY2020_Tx" SG_ 1095 PepsKeyFound_No_Actl 1;
BA_ "U_CD542_MY2021_Tx" SG_ 1095 PepsKeyFound_No_Actl 1;
BA_ "U_U55X_MY2022_Tx" SG_ 1095 PepsKeyFound_No_Actl 1;
BA_ "U_CD764_MY2022_Tx" SG_ 1095 PepsKeyFound_No_Actl 1;
BA_ "GenSigSendType" SG_ 1095 KeyProg_No_Actl 3;
BA_ "U_CX727_MY2021_Tx" SG_ 1095 KeyProg_No_Actl 1;
BA_ "U_P702_MY2021_Tx" SG_ 1095 KeyProg_No_Actl 1;
BA_ "U_T6_MCA_MY2020_Tx" SG_ 1095 KeyProg_No_Actl 1;
BA_ "U_CD542_MY2021_Tx" SG_ 1095 KeyProg_No_Actl 1;
BA_ "U_U55X_MY2022_Tx" SG_ 1095 KeyProg_No_Actl 1;
BA_ "U_CD764_MY2022_Tx" SG_ 1095 KeyProg_No_Actl 1;
BA_ "GenSigSendType" SG_ 1095 VehLck_D_Dsply 3;
BA_ "U_CX727_MY2021_Tx" SG_ 1095 VehLck_D_Dsply 1;
BA_ "U_P702_MY2021_Tx" SG_ 1095 VehLck_D_Dsply 1;
BA_ "U_T6_MCA_MY2020_Tx" SG_ 1095 VehLck_D_Dsply 1;
BA_ "U_CD542_MY2021_Tx" SG_ 1095 VehLck_D_Dsply 1;
BA_ "U_U55X_MY2022_Tx" SG_ 1095 VehLck_D_Dsply 1;
BA_ "U_CD764_MY2022_Tx" SG_ 1095 VehLck_D_Dsply 1;
BA_ "WakeupSignal" SG_ 1094 RollCodeCell_No_Actl 1;
BA_ "U_CX727_MY2021_Rx" SG_ 1094 RollCodeCell_No_Actl 1;
BA_ "U_P702_MY2021_Rx" SG_ 1094 RollCodeCell_No_Actl 1;
BA_ "U_T6_MCA_MY2020_Rx" SG_ 1094 RollCodeCell_No_Actl 1;
BA_ "U_CD542_MY2021_Rx" SG_ 1094 RollCodeCell_No_Actl 1;
BA_ "U_U55X_MY2022_Rx" SG_ 1094 RollCodeCell_No_Actl 1;
BA_ "U_CD764_MY2022_Rx" SG_ 1094 RollCodeCell_No_Actl 1;
BA_ "U_T6_MCA_MY2020_Tx" SG_ 1094 RollCodeCell_No_Actl 1;
BA_ "ECGUsedTxSignal" SG_ 1094 RollCodeCell_No_Actl 1;
BA_ "U_CD542_MY2021_Tx" SG_ 1094 RollCodeCell_No_Actl 1;
BA_ "U_U55X_MY2022_Tx" SG_ 1094 RollCodeCell_No_Actl 1;
BA_ "U_CD764_MY2022_Tx" SG_ 1094 RollCodeCell_No_Actl 1;
BA_ "WakeupSignal" SG_ 1094 CellRstrtRq_No_Actl 1;
BA_ "U_CX727_MY2021_Rx" SG_ 1094 CellRstrtRq_No_Actl 1;
BA_ "U_P702_MY2021_Rx" SG_ 1094 CellRstrtRq_No_Actl 1;
BA_ "U_T6_MCA_MY2020_Rx" SG_ 1094 CellRstrtRq_No_Actl 1;
BA_ "U_CD542_MY2021_Rx" SG_ 1094 CellRstrtRq_No_Actl 1;
BA_ "U_U55X_MY2022_Rx" SG_ 1094 CellRstrtRq_No_Actl 1;
BA_ "U_CD764_MY2022_Rx" SG_ 1094 CellRstrtRq_No_Actl 1;
BA_ "U_T6_MCA_MY2020_Tx" SG_ 1094 CellRstrtRq_No_Actl 1;
BA_ "ECGUsedTxSignal" SG_ 1094 CellRstrtRq_No_Actl 1;
BA_ "U_CD542_MY2021_Tx" SG_ 1094 CellRstrtRq_No_Actl 1;
BA_ "U_U55X_MY2022_Tx" SG_ 1094 CellRstrtRq_No_Actl 1;
BA_ "U_CD764_MY2022_Tx" SG_ 1094 CellRstrtRq_No_Actl 1;
BA_ "WakeupSignal" SG_ 1094 CellRstrt_D_Rq 1;
BA_ "GenSigSendType" SG_ 1094 CellRstrt_D_Rq 3;
BA_ "U_CX727_MY2021_Rx" SG_ 1094 CellRstrt_D_Rq 1;
BA_ "U_P702_MY2021_Rx" SG_ 1094 CellRstrt_D_Rq 1;
BA_ "U_T6_MCA_MY2020_Rx" SG_ 1094 CellRstrt_D_Rq 1;
BA_ "U_CD542_MY2021_Rx" SG_ 1094 CellRstrt_D_Rq 1;
BA_ "U_U55X_MY2022_Rx" SG_ 1094 CellRstrt_D_Rq 1;
BA_ "U_CD764_MY2022_Rx" SG_ 1094 CellRstrt_D_Rq 1;
BA_ "U_T6_MCA_MY2020_Tx" SG_ 1094 CellRstrt_D_Rq 1;
BA_ "ECGUsedTxSignal" SG_ 1094 CellRstrt_D_Rq 1;
BA_ "U_CD542_MY2021_Tx" SG_ 1094 CellRstrt_D_Rq 1;
BA_ "U_U55X_MY2022_Tx" SG_ 1094 CellRstrt_D_Rq 1;
BA_ "U_CD764_MY2022_Tx" SG_ 1094 CellRstrt_D_Rq 1;
BA_ "WakeupSignal" SG_ 1094 CellPanicRq_No_Actl 1;
BA_ "U_CX727_MY2021_Rx" SG_ 1094 CellPanicRq_No_Actl 1;
BA_ "U_P702_MY2021_Rx" SG_ 1094 CellPanicRq_No_Actl 1;
BA_ "U_T6_MCA_MY2020_Rx" SG_ 1094 CellPanicRq_No_Actl 1;
BA_ "U_CD542_MY2021_Rx" SG_ 1094 CellPanicRq_No_Actl 1;
BA_ "U_U55X_MY2022_Rx" SG_ 1094 CellPanicRq_No_Actl 1;
BA_ "U_CD764_MY2022_Rx" SG_ 1094 CellPanicRq_No_Actl 1;
BA_ "U_T6_MCA_MY2020_Tx" SG_ 1094 CellPanicRq_No_Actl 1;
BA_ "ECGUsedTxSignal" SG_ 1094 CellPanicRq_No_Actl 1;
BA_ "U_CD542_MY2021_Tx" SG_ 1094 CellPanicRq_No_Actl 1;
BA_ "U_U55X_MY2022_Tx" SG_ 1094 CellPanicRq_No_Actl 1;
BA_ "U_CD764_MY2022_Tx" SG_ 1094 CellPanicRq_No_Actl 1;
BA_ "WakeupSignal" SG_ 1094 CellPanic_D_Rq 1;
BA_ "GenSigSendType" SG_ 1094 CellPanic_D_Rq 3;
BA_ "U_CX727_MY2021_Rx" SG_ 1094 CellPanic_D_Rq 1;
BA_ "U_P702_MY2021_Rx" SG_ 1094 CellPanic_D_Rq 1;
BA_ "U_T6_MCA_MY2020_Rx" SG_ 1094 CellPanic_D_Rq 1;
BA_ "U_CD542_MY2021_Rx" SG_ 1094 CellPanic_D_Rq 1;
BA_ "U_U55X_MY2022_Rx" SG_ 1094 CellPanic_D_Rq 1;
BA_ "U_CD764_MY2022_Rx" SG_ 1094 CellPanic_D_Rq 1;
BA_ "U_T6_MCA_MY2020_Tx" SG_ 1094 CellPanic_D_Rq 1;
BA_ "ECGUsedTxSignal" SG_ 1094 CellPanic_D_Rq 1;
BA_ "U_CD542_MY2021_Tx" SG_ 1094 CellPanic_D_Rq 1;
BA_ "U_U55X_MY2022_Tx" SG_ 1094 CellPanic_D_Rq 1;
BA_ "U_CD764_MY2022_Tx" SG_ 1094 CellPanic_D_Rq 1;
BA_ "WakeupSignal" SG_ 1094 CellLockRq_No_Actl 1;
BA_ "U_CX727_MY2021_Rx" SG_ 1094 CellLockRq_No_Actl 1;
BA_ "U_P702_MY2021_Rx" SG_ 1094 CellLockRq_No_Actl 1;
BA_ "U_T6_MCA_MY2020_Rx" SG_ 1094 CellLockRq_No_Actl 1;
BA_ "U_CD542_MY2021_Rx" SG_ 1094 CellLockRq_No_Actl 1;
BA_ "U_U55X_MY2022_Rx" SG_ 1094 CellLockRq_No_Actl 1;
BA_ "U_CD764_MY2022_Rx" SG_ 1094 CellLockRq_No_Actl 1;
BA_ "U_T6_MCA_MY2020_Tx" SG_ 1094 CellLockRq_No_Actl 1;
BA_ "ECGUsedTxSignal" SG_ 1094 CellLockRq_No_Actl 1;
BA_ "U_CD542_MY2021_Tx" SG_ 1094 CellLockRq_No_Actl 1;
BA_ "U_U55X_MY2022_Tx" SG_ 1094 CellLockRq_No_Actl 1;
BA_ "U_CD764_MY2022_Tx" SG_ 1094 CellLockRq_No_Actl 1;
BA_ "WakeupSignal" SG_ 1094 CellLock_D_Rq 1;
BA_ "GenSigSendType" SG_ 1094 CellLock_D_Rq 3;
BA_ "U_CX727_MY2021_Rx" SG_ 1094 CellLock_D_Rq 1;
BA_ "U_P702_MY2021_Rx" SG_ 1094 CellLock_D_Rq 1;
BA_ "U_T6_MCA_MY2020_Rx" SG_ 1094 CellLock_D_Rq 1;
BA_ "U_CD542_MY2021_Rx" SG_ 1094 CellLock_D_Rq 1;
BA_ "U_U55X_MY2022_Rx" SG_ 1094 CellLock_D_Rq 1;
BA_ "U_CD764_MY2022_Rx" SG_ 1094 CellLock_D_Rq 1;
BA_ "U_T6_MCA_MY2020_Tx" SG_ 1094 CellLock_D_Rq 1;
BA_ "ECGUsedTxSignal" SG_ 1094 CellLock_D_Rq 1;
BA_ "U_CD542_MY2021_Tx" SG_ 1094 CellLock_D_Rq 1;
BA_ "U_U55X_MY2022_Tx" SG_ 1094 CellLock_D_Rq 1;
BA_ "U_CD764_MY2022_Tx" SG_ 1094 CellLock_D_Rq 1;
BA_ "WakeupSignal" SG_ 1094 CellChirpRq_No_Actl 1;
BA_ "U_CX727_MY2021_Rx" SG_ 1094 CellChirpRq_No_Actl 1;
BA_ "U_P702_MY2021_Rx" SG_ 1094 CellChirpRq_No_Actl 1;
BA_ "U_T6_MCA_MY2020_Rx" SG_ 1094 CellChirpRq_No_Actl 1;
BA_ "U_CD542_MY2021_Rx" SG_ 1094 CellChirpRq_No_Actl 1;
BA_ "U_U55X_MY2022_Rx" SG_ 1094 CellChirpRq_No_Actl 1;
BA_ "U_CD764_MY2022_Rx" SG_ 1094 CellChirpRq_No_Actl 1;
BA_ "U_T6_MCA_MY2020_Tx" SG_ 1094 CellChirpRq_No_Actl 1;
BA_ "ECGUsedTxSignal" SG_ 1094 CellChirpRq_No_Actl 1;
BA_ "U_CD542_MY2021_Tx" SG_ 1094 CellChirpRq_No_Actl 1;
BA_ "U_U55X_MY2022_Tx" SG_ 1094 CellChirpRq_No_Actl 1;
BA_ "U_CD764_MY2022_Tx" SG_ 1094 CellChirpRq_No_Actl 1;
BA_ "WakeupSignal" SG_ 1094 CellChirp_D_Rq 1;
BA_ "GenSigSendType" SG_ 1094 CellChirp_D_Rq 3;
BA_ "U_CX727_MY2021_Rx" SG_ 1094 CellChirp_D_Rq 1;
BA_ "U_P702_MY2021_Rx" SG_ 1094 CellChirp_D_Rq 1;
BA_ "U_T6_MCA_MY2020_Rx" SG_ 1094 CellChirp_D_Rq 1;
BA_ "U_CD542_MY2021_Rx" SG_ 1094 CellChirp_D_Rq 1;
BA_ "U_U55X_MY2022_Rx" SG_ 1094 CellChirp_D_Rq 1;
BA_ "U_CD764_MY2022_Rx" SG_ 1094 CellChirp_D_Rq 1;
BA_ "U_T6_MCA_MY2020_Tx" SG_ 1094 CellChirp_D_Rq 1;
BA_ "ECGUsedTxSignal" SG_ 1094 CellChirp_D_Rq 1;
BA_ "U_CD542_MY2021_Tx" SG_ 1094 CellChirp_D_Rq 1;
BA_ "U_U55X_MY2022_Tx" SG_ 1094 CellChirp_D_Rq 1;
BA_ "U_CD764_MY2022_Tx" SG_ 1094 CellChirp_D_Rq 1;
BA_ "GenSigSendType" SG_ 1100 RearDiffLckLamp_D_Rq2 3;
BA_ "U_U55X_MY2022_Rx" SG_ 1100 RearDiffLckLamp_D_Rq2 1;
BA_ "GenSigSendType" SG_ 1100 RvltnMatchAllw_D_Stat 3;
BA_ "GenSigStartValueInteger" SG_ 1100 WakeAlarm1_T_Rq 32767;
BA_ "GenSigStartValue" SG_ 1100 WakeAlarm1_T_Rq 32767;
BA_ "U_CX727_MY2021_Rx" SG_ 1100 WakeAlarm1_T_Rq 1;
BA_ "U_P702_MY2021_Rx" SG_ 1100 WakeAlarm1_T_Rq 1;
BA_ "U_T6_MCA_MY2020_Rx" SG_ 1100 WakeAlarm1_T_Rq 1;
BA_ "U_CD542_MY2021_Rx" SG_ 1100 WakeAlarm1_T_Rq 1;
BA_ "U_U55X_MY2022_Rx" SG_ 1100 WakeAlarm1_T_Rq 1;
BA_ "U_CD764_MY2022_Rx" SG_ 1100 WakeAlarm1_T_Rq 1;
BA_ "WakeupSignal" SG_ 1100 WakeAlarm1_B_Typ 1;
BA_ "GenSigSendType" SG_ 1100 WakeAlarm1_B_Typ 3;
BA_ "U_CX727_MY2021_Rx" SG_ 1100 WakeAlarm1_B_Typ 1;
BA_ "U_P702_MY2021_Rx" SG_ 1100 WakeAlarm1_B_Typ 1;
BA_ "U_T6_MCA_MY2020_Rx" SG_ 1100 WakeAlarm1_B_Typ 1;
BA_ "U_CD542_MY2021_Rx" SG_ 1100 WakeAlarm1_B_Typ 1;
BA_ "U_U55X_MY2022_Rx" SG_ 1100 WakeAlarm1_B_Typ 1;
BA_ "U_CD764_MY2022_Rx" SG_ 1100 WakeAlarm1_B_Typ 1;
BA_ "GenSigSendType" SG_ 1100 TrnNtrlIdlExit_B_Rq 3;
BA_ "GenSigSendType" SG_ 1100 HvacCmprLim_D_Stat 3;
BA_ "GenSigSendType" SG_ 1100 Veh_V_DsplyTrailCtlSet 3;
BA_ "GenSigSendType" SG_ 1100 TrailCtlPt_B_Falt 3;
BA_ "GenSigSendType" SG_ 1100 TrnNtrlIdlInhbt_B_Rq 3;
BA_ "GenSigSendType" SG_ 1100 AutoTowAllw_D_StatMnu 3;
BA_ "GenSigSendType" SG_ 1100 AutoTowActv_B_Stat 3;
BA_ "GenSigSendType" SG_ 1100 SpareTireDetct_B_Stat 3;
BA_ "U_U55X_MY2022_Rx" SG_ 1100 SpareTireDetct_B_Stat 1;
BA_ "GenSigStartValueInteger" SG_ 1100 RearDiffSumpOil_Te_Est 254;
BA_ "GenSigStartValue" SG_ 1100 RearDiffSumpOil_Te_Est 254;
BA_ "U_U55X_MY2022_Rx" SG_ 1100 RearDiffSumpOil_Te_Est 1;
BA_ "GenSigSendType" SG_ 1100 RearDiffMtrRun_B_Stat 3;
BA_ "U_U55X_MY2022_Rx" SG_ 1100 RearDiffMtrRun_B_Stat 1;
BA_ "GenSigSendType" SG_ 1100 EngTrlrCnnct_D_Stat 3;
BA_ "GenSigStartValueInteger" SG_ 1100 GrossTrainWeight_M_Est 254;
BA_ "GenSigStartValue" SG_ 1100 GrossTrainWeight_M_Est 254;
BA_ "GenSigSendType" SG_ 1100 SuspVlimMsgTxt_B_Rq 3;
BA_ "GenSigSendType" SG_ 1100 RearDiffLckMsg2_D_Rq 3;
BA_ "GenSigSendType" SG_ 1100 EngExhMdeQuiet_D2_Stat 3;
BA_ "WakeupSignal" SG_ 993 MemSwtch_D_RqRecall 1;
BA_ "U_CX727_MY2021_Rx" SG_ 993 MemSwtch_D_RqRecall 1;
BA_ "U_P702_MY2021_Rx" SG_ 993 MemSwtch_D_RqRecall 1;
BA_ "U_T6_MCA_MY2020_Rx" SG_ 993 MemSwtch_D_RqRecall 1;
BA_ "U_CD542_MY2021_Rx" SG_ 993 MemSwtch_D_RqRecall 1;
BA_ "U_U55X_MY2022_Rx" SG_ 993 MemSwtch_D_RqRecall 1;
BA_ "U_CD764_MY2022_Rx" SG_ 993 MemSwtch_D_RqRecall 1;
BA_ "WakeupSignal" SG_ 993 MemSwtch_D_RqAssoc 1;
BA_ "U_CX727_MY2021_Rx" SG_ 993 MemSwtch_D_RqAssoc 1;
BA_ "U_P702_MY2021_Rx" SG_ 993 MemSwtch_D_RqAssoc 1;
BA_ "U_T6_MCA_MY2020_Rx" SG_ 993 MemSwtch_D_RqAssoc 1;
BA_ "U_CD542_MY2021_Rx" SG_ 993 MemSwtch_D_RqAssoc 1;
BA_ "U_U55X_MY2022_Rx" SG_ 993 MemSwtch_D_RqAssoc 1;
BA_ "U_CD764_MY2022_Rx" SG_ 993 MemSwtch_D_RqAssoc 1;
BA_ "GenSigStartValueInteger" SG_ 993 PersIndexDsm_D_Actl 4;
BA_ "GenSigStartValue" SG_ 993 PersIndexDsm_D_Actl 4;
BA_ "WakeupSignal" SG_ 131 HeadLghtHiOn_B_StatAhb 1;
BA_ "GenSigStartValueInteger" SG_ 131 WiprFrontSwtch_D_Stat 9;
BA_ "GenSigStartValue" SG_ 131 WiprFrontSwtch_D_Stat 9;
BA_ "WakeupSignal" SG_ 131 HeadLghtHiCtrl_D_RqAhb 1;
BA_ "U_CX727_MY2021_Rx" SG_ 131 HeadLghtHiCtrl_D_RqAhb 1;
BA_ "U_P702_MY2021_Rx" SG_ 131 HeadLghtHiCtrl_D_RqAhb 1;
BA_ "U_T6_MCA_MY2020_Rx" SG_ 131 HeadLghtHiCtrl_D_RqAhb 1;
BA_ "U_CD542_MY2021_Rx" SG_ 131 HeadLghtHiCtrl_D_RqAhb 1;
BA_ "U_U55X_MY2022_Rx" SG_ 131 HeadLghtHiCtrl_D_RqAhb 1;
BA_ "U_CD764_MY2022_Rx" SG_ 131 HeadLghtHiCtrl_D_RqAhb 1;
BA_ "WakeupSignal" SG_ 131 HeadLghtHiFlash_D_Stat 1;
BA_ "U_CX727_MY2021_Rx" SG_ 131 HeadLghtHiFlash_D_Stat 1;
BA_ "U_P702_MY2021_Rx" SG_ 131 HeadLghtHiFlash_D_Stat 1;
BA_ "U_T6_MCA_MY2020_Rx" SG_ 131 HeadLghtHiFlash_D_Stat 1;
BA_ "U_CD542_MY2021_Rx" SG_ 131 HeadLghtHiFlash_D_Stat 1;
BA_ "U_U55X_MY2022_Rx" SG_ 131 HeadLghtHiFlash_D_Stat 1;
BA_ "U_CD764_MY2022_Rx" SG_ 131 HeadLghtHiFlash_D_Stat 1;
BA_ "GenSigStartValueInteger" SG_ 131 WiprFront_D_Stat 15;
BA_ "GenSigStartValue" SG_ 131 WiprFront_D_Stat 15;
BA_ "U_CX727_MY2021_Rx" SG_ 131 WiprFront_D_Stat 1;
BA_ "U_P702_MY2021_Rx" SG_ 131 WiprFront_D_Stat 1;
BA_ "U_T6_MCA_MY2020_Rx" SG_ 131 WiprFront_D_Stat 1;
BA_ "U_CD542_MY2021_Rx" SG_ 131 WiprFront_D_Stat 1;
BA_ "U_U55X_MY2022_Rx" SG_ 131 WiprFront_D_Stat 1;
BA_ "U_CD764_MY2022_Rx" SG_ 131 WiprFront_D_Stat 1;
BA_ "WakeupSignal" SG_ 131 TurnLghtSwtch_D_Stat 1;
BA_ "U_CX727_MY2021_Rx" SG_ 131 TurnLghtSwtch_D_Stat 1;
BA_ "U_P702_MY2021_Rx" SG_ 131 TurnLghtSwtch_D_Stat 1;
BA_ "U_T6_MCA_MY2020_Rx" SG_ 131 TurnLghtSwtch_D_Stat 1;
BA_ "U_CD542_MY2021_Rx" SG_ 131 TurnLghtSwtch_D_Stat 1;
BA_ "U_U55X_MY2022_Rx" SG_ 131 TurnLghtSwtch_D_Stat 1;
BA_ "U_CD764_MY2022_Rx" SG_ 131 TurnLghtSwtch_D_Stat 1;
BA_ "GenSigStartValueInteger" SG_ 131 LghtAmb_D_Sns 7;
BA_ "GenSigStartValue" SG_ 131 LghtAmb_D_Sns 7;
BA_ "U_CX727_MY2021_Rx" SG_ 131 LghtAmb_D_Sns 1;
BA_ "U_P702_MY2021_Rx" SG_ 131 LghtAmb_D_Sns 1;
BA_ "U_T6_MCA_MY2020_Rx" SG_ 131 LghtAmb_D_Sns 1;
BA_ "U_CD542_MY2021_Rx" SG_ 131 LghtAmb_D_Sns 1;
BA_ "U_U55X_MY2022_Rx" SG_ 131 LghtAmb_D_Sns 1;
BA_ "U_CD764_MY2022_Rx" SG_ 131 LghtAmb_D_Sns 1;
BA_ "WakeupSignal" SG_ 819 DrPrsntPsngr_D_Stat 1;
BA_ "U_T6_MCA_MY2020_Rx" SG_ 819 DrPrsntPsngr_D_Stat 1;
BA_ "U_U55X_MY2022_Rx" SG_ 819 DrPrsntPsngr_D_Stat 1;
BA_ "WakeupSignal" SG_ 819 DrPrsntRearPsngr_D_Stat 1;
BA_ "U_T6_MCA_MY2020_Rx" SG_ 819 DrPrsntRearPsngr_D_Stat 1;
BA_ "U_U55X_MY2022_Rx" SG_ 819 DrPrsntRearPsngr_D_Stat 1;
BA_ "WakeupSignal" SG_ 819 Memory_3_SwPsngr_Stat 1;
BA_ "WakeupSignal" SG_ 819 Memory_2_SwPsngr_Stat 1;
BA_ "WakeupSignal" SG_ 819 Memory_1_SwPsngr_Stat 1;
BA_ "U_CX727_MY2021_Rx" SG_ 819 RollCode_No_ActlPdm 1;
BA_ "U_P702_MY2021_Rx" SG_ 819 RollCode_No_ActlPdm 1;
BA_ "U_T6_MCA_MY2020_Rx" SG_ 819 RollCode_No_ActlPdm 1;
BA_ "U_CD542_MY2021_Rx" SG_ 819 RollCode_No_ActlPdm 1;
BA_ "U_U55X_MY2022_Rx" SG_ 819 RollCode_No_ActlPdm 1;
BA_ "U_CD764_MY2022_Rx" SG_ 819 RollCode_No_ActlPdm 1;
BA_ "WakeupSignal" SG_ 819 Pasngr_Lock_Sw_Stat 1;
BA_ "U_CX727_MY2021_Rx" SG_ 819 Pasngr_Lock_Sw_Stat 1;
BA_ "U_P702_MY2021_Rx" SG_ 819 Pasngr_Lock_Sw_Stat 1;
BA_ "U_T6_MCA_MY2020_Rx" SG_ 819 Pasngr_Lock_Sw_Stat 1;
BA_ "U_CD542_MY2021_Rx" SG_ 819 Pasngr_Lock_Sw_Stat 1;
BA_ "U_U55X_MY2022_Rx" SG_ 819 Pasngr_Lock_Sw_Stat 1;
BA_ "U_CD764_MY2022_Rx" SG_ 819 Pasngr_Lock_Sw_Stat 1;
BA_ "WakeupSignal" SG_ 819 Pasngr_Lock_Sw_Cnt 1;
BA_ "MetaData" SG_ 819 Pasngr_Lock_Sw_Cnt 1;
BA_ "U_CX727_MY2021_Rx" SG_ 819 Pasngr_Lock_Sw_Cnt 1;
BA_ "U_P702_MY2021_Rx" SG_ 819 Pasngr_Lock_Sw_Cnt 1;
BA_ "U_T6_MCA_MY2020_Rx" SG_ 819 Pasngr_Lock_Sw_Cnt 1;
BA_ "U_CD542_MY2021_Rx" SG_ 819 Pasngr_Lock_Sw_Cnt 1;
BA_ "U_U55X_MY2022_Rx" SG_ 819 Pasngr_Lock_Sw_Cnt 1;
BA_ "U_CD764_MY2022_Rx" SG_ 819 Pasngr_Lock_Sw_Cnt 1;
BA_ "WakeupSignal" SG_ 819 ChildLckFdbckRp_B_Stat 1;
BA_ "U_CX727_MY2021_Rx" SG_ 819 ChildLckFdbckRp_B_Stat 1;
BA_ "U_P702_MY2021_Rx" SG_ 819 ChildLckFdbckRp_B_Stat 1;
BA_ "U_T6_MCA_MY2020_Rx" SG_ 819 ChildLckFdbckRp_B_Stat 1;
BA_ "U_CD542_MY2021_Rx" SG_ 819 ChildLckFdbckRp_B_Stat 1;
BA_ "U_U55X_MY2022_Rx" SG_ 819 ChildLckFdbckRp_B_Stat 1;
BA_ "U_CD764_MY2022_Rx" SG_ 819 ChildLckFdbckRp_B_Stat 1;
VAL_ 1079 DrLatchRr_B_Falt 1 "Yes" 0 "No" ;
VAL_ 1079 DrLatchRl_B_Falt 1 "Yes" 0 "No" ;
VAL_ 1079 DrLatchLckRr_B_Stat 1 "Locked" 0 "Unlock" ;
VAL_ 1079 DrLatchLckRl_B_Stat 1 "Locked" 0 "Unlock" ;
VAL_ 1079 DrLatchLckFr_B_Stat 1 "Locked" 0 "Unlock" ;
VAL_ 1079 DrLatchLckFl_B_Stat 1 "Locked" 0 "Unlock" ;
VAL_ 1079 DrLatchFr_B_Falt 1 "Yes" 0 "No" ;
VAL_ 1079 DrLatchFl_B_Falt 1 "Yes" 0 "No" ;
VAL_ 1079 ChildLckFdbckRr_B_Stat 1 "Locked" 0 "Unlock" ;
VAL_ 1079 ChildLckFdbckRl_B_Stat 1 "Locked" 0 "Unlock" ;
VAL_ 954 PosLghtFr_D_Stat 3 "Faulty" 2 "Outage" 1 "On" 0 "Off" ;
VAL_ 954 PosLghtFl_D_Stat 3 "Faulty" 2 "Outage" 1 "On" 0 "Off" ;
VAL_ 954 VehWlcmFrwlMde_D_Stat 7 "IlluminatedExit" 6 "CourtesyLightingDelayExt" 5 "CourtesyLightingExtended" 4 "CourtesyLightingDelayAll" 3 "CourtesyLightingAll" 2 "IlluminatedEntry" 1 "Approach" 0 "Null" ;
VAL_ 954 LghtAmbDrvMde_B_Stat 1 "Automatic" 0 "Manual" ;
VAL_ 954 PwRnngBoardPoll_D_Stat 3 "NotUsed" 2 "PkPresent" 1 "PkNotPresent" 0 "NotPolling" ;
VAL_ 954 VehWlcmFrwl_D_Stat 3 "RunStart" 2 "Farewell" 1 "Welcome" 0 "Null" ;
VAL_ 1118 AcChrgRdy_B_Stat 1 "True" 0 "False" ;
VAL_ 1118 ExtChrgNowButtn_B_Rq 1 "Request" 0 "NoRequest" ;
VAL_ 1118 CoolFanChrgr_D_Rq 3 "High" 2 "Medium" 1 "Low" 0 "Off" ;
VAL_ 1118 ChrgrClntFlw_D_Rq 3 "High" 2 "Medium" 1 "Low" 0 "Off" ;
VAL_ 1118 PlgStatEvnt_B_Stat 1 "Active" 0 "Inactive" ;
VAL_ 1118 ChrgrCnnctPwr_B_Stat 1 "Asserted" 0 "NotAsserted" ;
VAL_ 1118 ChrgrAvailEvnt_B_Stat 1 "Active" 0 "Inactive" ;
VAL_ 1118 ChrgrSrvcRqd_B_Rq 1 "On" 0 "Off" ;
VAL_ 1118 ChrgrS2Swtch_B_Stat 1 "Close" 0 "Open" ;
VAL_ 1118 ChrgChngEvnt_B_Stat 1 "Active" 0 "Inactive" ;
VAL_ 1118 ChrgCordLck_D_Stat 7 "Faulty" 6 "LockFail" 5 "UnlockFail" 4 "LockInProgress" 3 "UnlockInProgress" 2 "Lock" 1 "Unlock" 0 "Retain" ;
VAL_ 1118 ChrgrInPwMde_D_Actl 15 "NotUsed_5" 14 "NotUsed_4" 13 "NotUsed_3" 12 "NotUsed_2" 11 "NotUsed_1" 10 "DcBpt" 9 "DigitalCommEnd" 8 "EvseFault" 7 "EvseNotCompatible" 6 "IcCharging" 5 "DcCharging" 4 "AcDigital" 3 "AcBasic" 2 "DigitalCommDetected" 1 "EvsePaused" 0 "EvseNotDetected" ;
VAL_ 1118 ChrgPortDrOpen_B_Stat 1 "True" 0 "False" ;
VAL_ 1118 ChrgCrdLck_D_Falt 3 "NotUsed" 2 "HardwareFault" 1 "CsiFault" 0 "NoFault" ;
VAL_ 953 PaakMyKeySearch_D_Stat 7 "PhoneErased" 6 "LockButtonTimeOut" 5 "PressLockButton" 4 "ConfirmHmi" 3 "MyKeyPaakFound" 2 "StandardPaakFound" 1 "NoValidPaakFound" 0 "Null" ;
VAL_ 953 BattULoChrgHyb_D_Stat 7 "NotUsed_4" 6 "NotUsed_3" 5 "NotUsed_2" 4 "NotUsed_1" 3 "VehicleServiceRequired" 2 "EvRangeLossDueToLoadActive" 1 "BatteryServiceRequired" 0 "Null" ;
VAL_ 953 BattULoChrgHyb_B_Rq 1 "True" 0 "False" ;
VAL_ 953 ChrgCordLck_B_Stat 1 "Unlock" 0 "Null" ;
VAL_ 953 WakeAlarm3_D_Stat 3 "PublisherReset" 2 "Wake" 1 "AlarmRunning" 0 "AlarmOff" ;
VAL_ 953 WakeAlarm2_D_Stat 3 "PublisherReset" 2 "Wake" 1 "AlarmRunning" 0 "AlarmOff" ;
VAL_ 953 WakeAlarm1_D_Stat 3 "PublisherReset" 2 "Wake" 1 "AlarmRunning" 0 "AlarmOff" ;
VAL_ 953 WakeAlarm0_D_Stat 3 "PublisherReset" 2 "Wake" 1 "AlarmRunning" 0 "AlarmOff" ;
VAL_ 1112 BattTrac2_E_Max 4095 "Faulty" 4094 "NoDataExists" ;
VAL_ 1112 BattTrac2_E_Avail 4095 "Faulty" 4094 "NoDataExists" ;
VAL_ 1112 BattTracTeEvnt_B_Stat 1 "Active" 0 "Inactive" ;
VAL_ 1112 BattChrgTrgtEvnt_B_Stat 1 "Active" 0 "Inactive" ;
VAL_ 1112 BattTracTeSustn_B_Rq 1 "Active" 0 "Inactive" ;
VAL_ 1112 BattTracChrgSustn_B_Rq 1 "Active" 0 "Inactive" ;
VAL_ 1112 BattTracHeat_D_Rq 3 "Faulty" 2 "NotUsed" 1 "On" 0 "Off" ;
VAL_ 1112 BattTracDcFstSustn_B_Rq 1 "Active" 0 "Inactive" ;
VAL_ 1112 BattTracCnnct_D_Cmd 7 "NotUsed_3" 6 "NotUsed_2" 5 "NotUsed_1" 4 "WeldCheck" 3 "OkToDischarge" 2 "Closed" 1 "Precharge" 0 "Open" ;
VAL_ 1112 BattTracHvilOpen_B_Stat 1 "Open" 0 "Closed" ;
VAL_ 1112 BattTracDcdcDis_B_Rq 1 "Yes" 0 "No" ;
VAL_ 1112 BattTracDiagClr_B_Rq 1 "On" 0 "Off" ;
VAL_ 1112 BattTracHazrd_D_Stat 3 "Disabled" 2 "HazardConfirmed" 1 "ExternalMonitoringRequired" 0 "NoHazardDetected" ;
VAL_ 1112 HtrnClntPump_D_Stat 3 "Faulty" 2 "No_Data_Exists" 1 "On" 0 "Off" ;
VAL_ 1112 BattTracDelta_Te_Actl 255 "Faulty" 254 "NoDataExists" ;
VAL_ 1112 BattTracClntPmp_D_Stat 3 "Faulty" 2 "No_Data_Exists" 1 "On" 0 "Off" ;
VAL_ 1144 AwdLckMde_D_Stat 7 "NotUsed_2" 6 "NotUsed_1" 5 "PrimaryAxleSpeedControl" 4 "DualAxleSpeedControl" 3 "EfficiencySplit" 2 "SecondaryAxleTorqueCtrl" 1 "SecondaryAxleSpeedCtrl" 0 "Off" ;
VAL_ 1144 BattTracCool_B_Actl 1 "On" 0 "Off" ;
VAL_ 1144 BattChrgTrgtSoC_D_Rq 7 "Percent_50" 6 "Percent_60" 5 "Percent_70" 4 "Percent_80" 3 "Percent_85" 2 "Percent_90" 1 "Percent_95" 0 "Percent_100" ;
VAL_ 1144 PreCondBatt_B_Actl 1 "On" 0 "Off" ;
VAL_ 1144 CabnEvapSovFront_B_Rq 1 "On" 0 "Off" ;
VAL_ 1144 HeatCoreSovRear_B_Rq 1 "On" 0 "Off" ;
VAL_ 1144 BattChlrSov_B_Rq 1 "On" 0 "Off" ;
VAL_ 1144 CabnEvapSovRear_B_Rq 1 "On" 0 "Off" ;
VAL_ 1144 BrkAppl_D_RqPt 3 "BrakesSlowRelease" 2 "BrakesFastRelease" 1 "BrakesEngage" 0 "NotActive" ;
VAL_ 1144 BattClntVlvOvrrd_D_Rq 3 "NotUsed" 2 "OverrideTbcvToChiller" 1 "OverrideTbcvToRadiator" 0 "NoOverrideToTbcvCLogic" ;
VAL_ 1144 BattTracChillerOn_B_Rq 1 "On" 0 "Off" ;
VAL_ 1144 BattTracChiller_D_Stat 3 "NotUsed" 2 "ChillerNotAvailable" 1 "ChillerBrieflyAvailable" 0 "ChillerAvailable" ;
VAL_ 1144 ULoBattTrnsfrSustn_B_Rq 1 "Active" 0 "Inactive" ;
VAL_ 1144 ULoBattTransfer_D_Stat 7 "NotUsed_2" 6 "NotUsed_1" 5 "TransferError" 4 "TransferComplete" 3 "TransferThroughGridEnergy" 2 "InsufficientEnergyToXfer" 1 "TransferInProgress" 0 "NoTransfer" ;
VAL_ 1144 HtrnDcdcDis_B_Rq 1 "Yes" 0 "No" ;
VAL_ 1144 HtrnCnnctPwr_B_Stat 1 "Asserted" 0 "NotAsserted" ;
VAL_ 1144 PtcHtr_D_Stat 3 "Faulty" 2 "NotUsed" 1 "On" 0 "Off" ;
VAL_ 1144 BattChrgInhbt_D2_Rq 7 "NotUsed_4" 6 "NotUsed_3" 5 "NotUsed_2" 4 "NotUsed_1" 3 "MaintainTargetSoc" 2 "EndAtTarget" 1 "InhibitCharging" 0 "Enable_Charging" ;
VAL_ 1144 WakeAlarm0_B_Typ 1 "CanAndEcuDriveCircuit" 0 "CanOnly" ;
VAL_ 1144 BattTracClimtDis_B_Stat 1 "Enable" 0 "Disable" ;
VAL_ 1144 HtrnClntFlw_D_Rq 3 "High" 2 "Medium" 1 "Low" 0 "Off" ;
VAL_ 1144 BattTracDrvSustn_B_Rq 1 "Active" 0 "Inactive" ;
VAL_ 1144 CabinDrvSustn_B_Rq 1 "Active" 0 "Inactive" ;
VAL_ 1144 BattTracClntVlv_B_Rq 1 "On" 0 "Off" ;
VAL_ 1144 ChrgNowEvnt_B_Stat 1 "Active" 0 "Inactive" ;
VAL_ 127 AwdLatDelta_B_Rq 1 "Active" 0 "Inactive" ;
VAL_ 968 LnchCtl_D_Rq 3 "NotUsed2" 2 "NotUsed1" 1 "LC_On" 0 "LC_Off" ;
VAL_ 968 CurrentColor_CmdGage 15 "NotUsed7" 14 "NotUsed6" 13 "NotUsed5" 12 "NotUsed4" 11 "NotUsed3" 10 "NotUsed2" 9 "NotUsed1" 8 "Null" 7 "Color7" 6 "Color6" 5 "Color5" 4 "Color4" 3 "Color3" 2 "Color2" 1 "Color1" 0 "Off" ;
VAL_ 968 BlendedColor_CmdGage 3 "NotUsed" 2 "Null" 1 "On" 0 "Off" ;
VAL_ 968 BlendColorRed_CmdGage 15 "NotUsed10" 14 "NotUsed9" 13 "NotUsed8" 12 "NotUsed7" 11 "NotUsed6" 10 "NotUsed5" 9 "NotUsed4" 8 "NotUsed3" 7 "NotUsed2" 6 "NotUsed1" 5 "_5" 4 "_4" 3 "_3" 2 "_2" 1 "_1" 0 "Null" ;
VAL_ 968 BlendColorGrn_CmdGage 15 "NotUsed10" 14 "NotUsed9" 13 "NotUsed8" 12 "NotUsed7" 11 "NotUsed6" 10 "NotUsed5" 9 "NotUsed4" 8 "NotUsed3" 7 "NotUsed2" 6 "NotUsed1" 5 "_5" 4 "_4" 3 "_3" 2 "_2" 1 "_1" 0 "Null" ;
VAL_ 968 BlendColorBlue_CmdGage 15 "NotUsed10" 14 "NotUsed9" 13 "NotUsed8" 12 "NotUsed7" 11 "NotUsed6" 10 "NotUsed5" 9 "NotUsed4" 8 "NotUsed3" 7 "NotUsed2" 6 "NotUsed1" 5 "_5" 4 "_4" 3 "_3" 2 "_2" 1 "_1" 0 "Null" ;
VAL_ 968 BrkDrvMde_D_Rq 7 "Faulty" 6 "RockCrawl" 5 "Baja" 4 "DragOrMudAndSand" 3 "Track" 2 "Snow_Wet" 1 "Sport" 0 "Normal" ;
VAL_ 968 Dimming_Level_Cmd 3 "Low" 2 "Not_Used" 1 "High" 0 "Null" ;
VAL_ 968 Current_Color_Cmd 15 "NotUsed7" 14 "NotUsed6" 13 "NotUsed5" 12 "NotUsed4" 11 "NotUsed3" 10 "NotUsed2" 9 "NotUsed1" 8 "Null" 7 "Color7" 6 "Color6" 5 "Color5" 4 "Color4" 3 "Color3" 2 "Color2" 1 "Color1" 0 "Off" ;
VAL_ 968 BlendedColorRed_Cmd 15 "NotUsed10" 14 "NotUsed9" 13 "NotUsed8" 12 "NotUsed7" 11 "NotUsed6" 10 "NotUsed5" 9 "NotUsed4" 8 "NotUsed3" 7 "NotUsed2" 6 "NotUsed1" 5 "_5" 4 "_4" 3 "_3" 2 "_2" 1 "_1" 0 "Null" ;
VAL_ 968 BlendedColorGreen_Cmd 15 "NotUsed10" 14 "NotUsed9" 13 "NotUsed8" 12 "NotUsed7" 11 "NotUsed6" 10 "NotUsed5" 9 "NotUsed4" 8 "NotUsed3" 7 "NotUsed2" 6 "NotUsed1" 5 "_5" 4 "_4" 3 "_3" 2 "_2" 1 "_1" 0 "Null" ;
VAL_ 968 BlendedColorBlue_Cmd 15 "NotUsed10" 14 "NotUsed9" 13 "NotUsed8" 12 "NotUsed7" 11 "NotUsed6" 10 "NotUsed5" 9 "NotUsed4" 8 "NotUsed3" 7 "NotUsed2" 6 "NotUsed1" 5 "_5" 4 "_4" 3 "_3" 2 "_2" 1 "_1" 0 "Null" ;
VAL_ 968 BlendedColor_Cmd 3 "NotUsed" 2 "Null" 1 "On" 0 "Off" ;
VAL_ 968 SlMde_D_Rq 3 "IsaNotConfigured" 2 "Manual_Mode" 1 "Auto_Mode" 0 "Null" ;
VAL_ 968 IsaOffst_D_Rq 15 "Faulty" 14 "Null" 13 "Thirteen" 12 "Twelve" 11 "Eleven" 10 "Ten" 9 "Nine" 8 "Eight" 7 "Seven" 6 "Six" 5 "Five" 4 "Four" 3 "Three" 2 "Two" 1 "One" 0 "Zero" ;
VAL_ 968 SuspDrvMde_D_Rq 7 "Faulty" 6 "NotUsed2" 5 "NotUsed1" 4 "Drag" 3 "Track" 2 "Snow_Wet" 1 "Sport" 0 "Normal" ;
VAL_ 1081 ChirpRq_No_ActlTrlr_UB 1 "Fresh_data" 0 "Unchanged_data" ;
VAL_ 1081 Chirp_D_RqTrlr_UB 1 "Fresh_data" 0 "Unchanged_data" ;
VAL_ 1081 Chirp_D_RqTrlr 3 "NotUsed" 2 "Chirp_2" 1 "Chirp_1" 0 "NoRequest" ;
VAL_ 1081 RearPassWindowPos_UB 1 "Fresh_data" 0 "Unchanged_data" ;
VAL_ 1081 RearPassWindowPos 7 "Unused2" 6 "Unused1" 5 "Fully_Open" 4 "Bet60Percent_FullyOpen" 3 "Bet10Percent_60Percent" 2 "BetFully_10PercentOpen" 1 "Fully_Closed" 0 "Undefined" ;
VAL_ 1081 RearDriverWindowPos_UB 1 "Fresh_data" 0 "Unchanged_data" ;
VAL_ 1081 RearDriverWindowPos 7 "Unused2" 6 "Unused1" 5 "Fully_Open" 4 "Bet60Percent_FullyOpen" 3 "Bet10Percent_60Percent" 2 "BetFully_10PercentOpen" 1 "Fully_Closed" 0 "Undefined" ;
VAL_ 1081 PassWindowPosition_UB 1 "Fresh_data" 0 "Unchanged_data" ;
VAL_ 1081 PassWindowPosition 7 "Unused2" 6 "Unused1" 5 "Fully_Open" 4 "Bet60Percent_FullyOpen" 3 "Bet10Percent_60Percent" 2 "BetFully_10PercentOpen" 1 "Fully_Closed" 0 "Undefined" ;
VAL_ 1081 DriverWindowPosition_UB 1 "Fresh_data" 0 "Unchanged_data" ;
VAL_ 1081 DriverWindowPosition 7 "Unused2" 6 "Unused1" 5 "Fully_Open" 4 "Bet60Percent_FullyOpen" 3 "Bet10Percent_60Percent" 2 "BetFully_10PercentOpen" 1 "Fully_Closed" 0 "Undefined" ;
VAL_ 1081 ChrgCrdLckEnbl_B_Stat 1 "Enable" 0 "Disable" ;
VAL_ 1081 ChrgCrdLckEnbl_B_Stat_UB 1 "Fresh_data" 0 "Unchanged_data" ;
VAL_ 1081 EcoInhbt_B_RqHvac_UB 1 "Fresh_data" 0 "Unchanged_data" ;
VAL_ 1081 EmgcyAsstActv_D_Stat_UB 1 "Fresh_data" 0 "Unchanged_data" ;
VAL_ 1081 EmgcyAsstActv_D_Stat 3 "ConfiguredOff" 2 "Active" 1 "Inactive" 0 "Null" ;
VAL_ 1081 TrlrHitchLamp_D_Rq2_UB 1 "Fresh_data" 0 "Unchanged_data" ;
VAL_ 1081 TrlrHitchLamp_D_Rq2 1 "On" 0 "Off" ;
VAL_ 1081 EcoInhbt_B_RqHvac 1 "Yes" 0 "No" ;
VAL_ 811 ExtLghtRight_D_RqMnu 7 "NotUsed" 6 "PressToOn3" 5 "PressToOff3" 4 "PressToOn2" 3 "PressToOff2" 2 "PressToOn1" 1 "PressToOff1" 0 "Reset" ;
VAL_ 811 ExtLghtRear_D_RqMnu 7 "NotUsed" 6 "PressToOn3" 5 "PressToOff3" 4 "PressToOn2" 3 "PressToOff2" 2 "PressToOn1" 1 "PressToOff1" 0 "Reset" ;
VAL_ 811 ExtLghtLeft_D_RqMnu 7 "NotUsed" 6 "PressToOn3" 5 "PressToOff3" 4 "PressToOn2" 3 "PressToOff2" 2 "PressToOn1" 1 "PressToOff1" 0 "Reset" ;
VAL_ 811 ExtLghtFront_D_RqMnu 7 "NotUsed" 6 "PressToOn3" 5 "PressToOff3" 4 "PressToOn2" 3 "PressToOff2" 2 "PressToOn1" 1 "PressToOff1" 0 "Reset" ;
VAL_ 811 SpeedoMajorUnit_D_Confg 3 "NotUsed" 2 "Kph" 1 "Mph" 0 "Null" ;
VAL_ 811 ScMnSoc_Pc_RqMnu 127 "Faulty" 126 "NoDataExists" ;
VAL_ 811 ScEnbl_D_RqMnu 3 "NotUsed" 2 "On" 1 "Off" 0 "Null" ;
VAL_ 811 OnePdlDrvButtn_B_Falt 1 "Faulted" 0 "NotFaulted" ;
VAL_ 811 ExtLghtDsply_D_Stat 7 "NotUsed" 6 "PressToOn3" 5 "PressToOff3" 4 "PressToOn2" 3 "PressToOff2" 2 "PressToOn1" 1 "PressToOff1" 0 "Reset" ;
VAL_ 811 OnePdlDrvButtn_B_Stat 1 "Pressed" 0 "Not_Pressed" ;
VAL_ 811 LongTermReset_B_RqMnu 1 "On" 0 "Off" ;
VAL_ 811 GoTEditMnte_T_RqMnu 15 "Faulty" 14 "NoDataExists" 13 "NotUsed_2" 12 "NotUsed_1" 11 "Minute_55" 10 "Minute_50" 9 "Minute_45" 8 "Minute_40" 7 "Minute_35" 6 "Minute_30" 5 "Minute_25" 4 "Minute_20" 3 "Minute_15" 2 "Minute_10" 1 "Minute_5" 0 "Minute_0" ;
VAL_ 811 GoTEditHr_T_RqMnu 31 "Faulty" 30 "NoDataExists" ;
VAL_ 811 DistToStopover_L_Actl 65535 "Faulty" ;
VAL_ 811 StopoverType_D_Stat 7 "Faulty" 6 "NotUsed_1" 5 "Other" 4 "Work" 3 "Home" 2 "ChargeStation" 1 "FinalDestination" 0 "Null" ;
VAL_ 811 AutoLghtOvrrd_B_RqDrv 1 "Allowed" 0 "NotAllowed" ;
VAL_ 810 VehHorn_B_RqOccAlrt 1 "On" 0 "Off" ;
VAL_ 810 DteCldAcceptData_B_Rq 1 "Yes" 0 "No" ;
VAL_ 810 RmtViewMde_B_Rq 1 "On" 0 "Off" ;
VAL_ 810 ExtLghtDsply_B_StatArb 1 "On" 0 "Off" ;
VAL_ 810 ExtLghtRight_D_RqOta 7 "NotUsed" 6 "PressToOn3" 5 "PressToOff3" 4 "PressToOn2" 3 "PressToOff2" 2 "PressToOn1" 1 "PressToOff1" 0 "Reset" ;
VAL_ 810 ExtLghtRear_D_RqOta 7 "NotUsed" 6 "PressToOn3" 5 "PressToOff3" 4 "PressToOn2" 3 "PressToOff2" 2 "PressToOn1" 1 "PressToOff1" 0 "Reset" ;
VAL_ 810 DteCldCnclRoute_B_Rq 1 "Yes" 0 "No" ;
VAL_ 810 PtRmtRprt_D_Stat 15 "NotUsed_4" 14 "NotUsed_3" 13 "NotUsed_2" 12 "PlugInToMaintain12vBattery" 11 "SettingUpdated" 10 "FastChargeComplete" 9 "ChargeNotOccurring" 8 "OneTimeSocReached" 7 "BatteryTemperatureRemind" 6 "ReducedPerformance" 5 "LimitedPerformance" 4 "ChargeFault" 3 "ChargeComplete" 2 "VehiclePreconditioned" 1 "TripDistanceAchieved" 0 "NoReportRequest" ;
VAL_ 810 ChrgrPncEnbl_D_Rq 3 "NotUsed" 2 "Enable" 1 "Disable" 0 "Null" ;
VAL_ 810 OBCCSerial_D_Rq 3 "PresentAndProvisioned" 2 "PresentAndProvAlertAck" 1 "PresentAndUnprovisioned" 0 "NotPresent" ;
VAL_ 810 ExtLghtLeft_D_RqOta 7 "NotUsed" 6 "PressToOn3" 5 "PressToOff3" 4 "PressToOn2" 3 "PressToOff2" 2 "PressToOn1" 1 "PressToOff1" 0 "Reset" ;
VAL_ 810 ExtLghtFront_D_RqOta 7 "NotUsed" 6 "PressToOn3" 5 "PressToOff3" 4 "PressToOn2" 3 "PressToOff2" 2 "PressToOn1" 1 "PressToOff1" 0 "Reset" ;
VAL_ 810 TlghtTest_D_RqArb 3 "TestEndAcknowledge" 2 "StartTest" 1 "StopTest" 0 "Null" ;
VAL_ 810 ChrgrPncSustn_B_Rq 1 "Active" 0 "Inactive" ;
VAL_ 303 DrStatHood_D2_Actl 5 "NotUsed_2" 4 "NotUsed_1" 3 "Disabled" 2 "Ajar" 1 "Closed" 0 "NotDetermined" 7 "Faulty" 6 "NotUsed_3" ;
VAL_ 1082 VdmSustnActv_B_Rq_UB 1 "Fresh_data" 0 "Unchanged_data" ;
VAL_ 1082 VdmSustnActv_B_Rq 1 "Active" 0 "Inactive" ;
VAL_ 1082 ChrgStatDsply_D_Rq_UB 1 "Fresh_data" 0 "Unchanged_data" ;
VAL_ 1082 ChrgStatDsply_D_Rq 3 "NotUsed_2" 2 "NotUsed_1" 1 "On" 0 "Off" ;
VAL_ 1082 ChrgCordUnlock_B_Rq_UB 1 "Fresh_data" 0 "Unchanged_data" ;
VAL_ 1082 ChrgCordUnlock_B_Rq 1 "Request" 0 "NoRequest" ;
VAL_ 1082 FldngSeatPwOffOk_B_Stat_UB 1 "Fresh_data" 0 "Unchanged_data" ;
VAL_ 1082 FldngSeatPwOffOk_B_Stat 1 "Yes" 0 "No" ;
VAL_ 1082 EngAirFilt_B_RqReset_UB 1 "Fresh_data" 0 "Unchanged_data" ;
VAL_ 1082 EngAirFilt_B_RqReset 1 "Yes" 0 "No" ;
VAL_ 1082 TrailCtl_D_Stat_UB 1 "Fresh_data" 0 "Unchanged_data" ;
VAL_ 1082 TrailCtl_D_Stat 7 "Faulty" 6 "DescentOnly" 5 "EnabledDeny" 4 "StandbyOverThreshold" 3 "StandbyOverride" 2 "Active" 1 "EnabledDescent" 0 "Off" ;
VAL_ 1082 DrLckActv_B_RqBalrr_UB 1 "Fresh_data" 0 "Unchanged_data" ;
VAL_ 1082 DrLckActv_B_RqBalrl_UB 1 "Fresh_data" 0 "Unchanged_data" ;
VAL_ 1082 DrLckActv_B_RqBalrr 1 "Active" 0 "Null" ;
VAL_ 1082 DrLckActv_B_RqBalrl 1 "Active" 0 "Null" ;
VAL_ 1082 EmgcyCall_D_Stat 7 "NotUsed_3" 6 "NotUsed_2" 5 "NotUsed_1" 4 "ManualEmergencyCall" 3 "AutoEmergencyCall" 2 "NoEvent" 1 "EmergencyCallNotSupported" 0 "Null" ;
VAL_ 1082 EmgcyCall_D_Stat_UB 1 "Fresh_data" 0 "Unchanged_data" ;
VAL_ 1082 EmPrflNo_D_Rq_UB 1 "Fresh_data" 0 "Unchanged_data" ;
VAL_ 1082 EmPrflKeyAssoc_D_Rq_UB 1 "Fresh_data" 0 "Unchanged_data" ;
VAL_ 1082 EmPrflNo_D_Rq 7 "NotUsed_3" 6 "NotUsed_2" 5 "NotUsed_1" 4 "Pers4" 3 "Pers3" 2 "Pers2" 1 "Pers1" 0 "Null" ;
VAL_ 1082 EmPrflKeyAssoc_D_Rq 7 "NotUsed_3" 6 "DisassociatePhone" 5 "EnterPhoneAssociation" 4 "OverwriteKey" 3 "DisassociateKey" 2 "ExitKeyAssociation" 1 "EnterKeyAssociation" 0 "Null" ;
VAL_ 1082 CamraViewSplit_B_Rq_UB 1 "Fresh_data" 0 "Unchanged_data" ;
VAL_ 1082 HMI_HMIMode_St 7 "NotUsed2" 6 "NotUsed1" 5 "Load_Shed_Active" 0 "Invalid" 1 "OffMode" 2 "On" 3 "Phone" 4 "Climate" ;
VAL_ 1082 CamraViewSplit_B_Rq 1 "On" 0 "Off" ;
VAL_ 1082 HMI_HMIMode_St_UB 1 "Fresh_data" 0 "Unchanged_data" ;
VAL_ 902 PrmtrAlrmWarnRq_No_Actl_UB 1 "Fresh_data" 0 "Unchanged_data" ;
VAL_ 902 PrmtrAlrmTrgRq_No_Actl_UB 1 "Fresh_data" 0 "Unchanged_data" ;
VAL_ 902 PrmtrAlrmWarn_B_Rq_UB 1 "Fresh_data" 0 "Unchanged_data" ;
VAL_ 902 RollCode_No_ActlRsm_UB 1 "Fresh_data" 0 "Unchanged_data" ;
VAL_ 902 PrmtrAlrmTrg_B_Rq_UB 1 "Fresh_data" 0 "Unchanged_data" ;
VAL_ 902 PanicRq_No_ActlRsm_UB 1 "Fresh_data" 0 "Unchanged_data" ;
VAL_ 902 Panic_D_RqRsm_UB 1 "Fresh_data" 0 "Unchanged_data" ;
VAL_ 902 CellLockRq_No_ActlRsm_UB 1 "Fresh_data" 0 "Unchanged_data" ;
VAL_ 902 PrmtrAlrmWarn_B_Rq 1 "Active" 0 "Null" ;
VAL_ 902 PrmtrAlrmTrg_B_Rq 1 "Active" 0 "Null" ;
VAL_ 902 Panic_D_RqRsm 3 "NotUsed" 2 "On" 1 "Off" 0 "Null" ;
VAL_ 902 CellLock_D_RqRsm 7 "NotUsed3" 6 "NotUsed2" 5 "NotUsed1" 4 "TrunkRelPopGlassLgCargo" 3 "LockAllDoorsandTailgate" 2 "UnlockDriversDoor" 1 "UnlockAllDoorsandTailgate" 0 "NoRequest" ;
VAL_ 902 CellLock_D_RqRsm_UB 1 "Fresh_data" 0 "Unchanged_data" ;
VAL_ 740 PtWakeupActv2_B_Rq 1 "On" 0 "Off" ;
VAL_ 740 BattAuxCnnct_B_Cmd 1 "Close" 0 "Open" ;
VAL_ 748 ChrgrOutHi_U_Actl 511 "Invalid" ;
VAL_ 748 ChrgrOutHi_I_Actl 4095 "Invalid" ;
VAL_ 748 ChrgrIn_Pw_Mx 4095 "Fault" ;
VAL_ 748 PlgActv_D_ActlChrgr 3 "Faulty" 2 "NoDataExists" 1 "On_Plug__Connected_" 0 "Off_Plug__Disconnected_" ;
VAL_ 748 ChrgrRdyStat_D_Actl 7 "NotUsed4" 6 "NotUsed3" 5 "NotUsed2" 4 "NotUsed1" 3 "Charging" 2 "ChargerFault" 1 "ChargerReady" 0 "NotReady" ;
VAL_ 389 HtrnOvrTeLamp_B_Dsply 1 "On" 0 "Off" ;
VAL_ 389 HtrnMil_D_Rq 3 "Not_Used" 2 "Flash" 1 "On" 0 "Off" ;
VAL_ 389 HtrnAin_UHi_Actl 1023 "Fault" 1022 "Unknown" ;
VAL_ 389 HtrnSrvcRqd_B_Dsply 1 "On" 0 "Off" ;
VAL_ 389 HtrnHvilOpen_B_Actl 1 "HVIL_is_Open" 0 "Normal_Operation" ;
VAL_ 389 PtWakeupDeltaT_T_Rq 2047 "Fault" 2046 "NoDataExists" ;
VAL_ 389 PreCondActv_B_Actl 1 "On" 0 "Off" ;
VAL_ 389 DrvCondTpRrDefrs_B_Rq 1 "On" 0 "Off" ;
VAL_ 389 BattTrac_I_EstVsc 32767 "Fault" 32766 "NoDataExists" ;
VAL_ 872 PwFlowPlgBatt_D_Dsply 3 "NotUsed" 2 "Flow_from_Plug_to_Batt" 1 "Flow_from_Batt_to_Plug" 0 "No_Flow" ;
VAL_ 872 PwFlowMtrDrv_D_Dsply 3 "NotUsed" 2 "Flow_from_Mtr_to_Axle" 1 "Flow_from_Axle_to_Mtr" 0 "No_FLow" ;
VAL_ 872 PwFlowEngMtr_D_Dsply 3 "NotUsed" 2 "Flow_from_Eng_to_Mtr" 1 "Flow_from_Mtr_to_Eng" 0 "No_Flow" ;
VAL_ 872 PwFlowEngFuel_D_Dsply 3 "NotUsed" 2 "Flow_from_Eng_to_Fuel" 1 "Flow_from_Fuel_to_Eng" 0 "No_Flow" ;
VAL_ 872 PwFlowEngDrv_D_Dsply 3 "NotUsed" 2 "Flow_from_Eng_to_Axle" 1 "Flow_from_Axle_to_Eng" 0 "No_Flow" ;
VAL_ 872 PwFlowBattMtr_D_Dsply 3 "NotUsed" 2 "Flow_from_Batt_to_Mtr" 1 "Flow_from_Mtr_to_Batt" 0 "No_Flow" ;
VAL_ 872 PlgActvArb_B_Dsply 1 "On" 0 "Off" ;
VAL_ 872 HybMdeStat_D_Dsply 7 "NotUsed2" 6 "EV_Charge" 5 "EV_Override" 4 "Forced_EV_Mode" 3 "Forced_Charge_Sustain_Mode" 2 "Auto_Charge_Sustain_Mode" 1 "Auto_Charge_Deplete_Mode" 0 "Null_State" ;
VAL_ 872 MildHybStat_D_Dsply 7 "NotUsed" 6 "Recovery" 5 "Charge" 4 "Assist" 3 "Boost" 2 "SystemInhibited" 1 "SystemError" 0 "Off" ;
VAL_ 872 EcoMode_B_Stat 1 "On" 0 "Off" ;
VAL_ 945 KeyPadCodeDgt7_D_Dsply 15 "NotUsed_4" 14 "NotUsed_3" 13 "NotUsed_2" 12 "NotUsed_1" 11 "Button7_8and9_0" 10 "Button0" 9 "Button9_0or9" 8 "Button8" 7 "Button7_8or7" 6 "Button6" 5 "Button5_6or5" 4 "Button4" 3 "Button3_4or3" 2 "Button2" 1 "Button1_2or1" 0 "EndofString" ;
VAL_ 945 KeyPadCodeDgt6_D_Dsply 15 "NotUsed_4" 14 "NotUsed_3" 13 "NotUsed_2" 12 "NotUsed_1" 11 "Button7_8and9_0" 10 "Button0" 9 "Button9_0or9" 8 "Button8" 7 "Button7_8or7" 6 "Button6" 5 "Button5_6or5" 4 "Button4" 3 "Button3_4or3" 2 "Button2" 1 "Button1_2or1" 0 "EndofString" ;
VAL_ 945 KeyPadCodeDgt5_D_Dsply 15 "NotUsed_4" 14 "NotUsed_3" 13 "NotUsed_2" 12 "NotUsed_1" 11 "Button7_8and9_0" 10 "Button0" 9 "Button9_0or9" 8 "Button8" 7 "Button7_8or7" 6 "Button6" 5 "Button5_6or5" 4 "Button4" 3 "Button3_4or3" 2 "Button2" 1 "Button1_2or1" 0 "EndofString" ;
VAL_ 945 KeyPadCodeDgt4_D_Dsply 15 "NotUsed_4" 14 "NotUsed_3" 13 "NotUsed_2" 12 "NotUsed_1" 11 "Button7_8and9_0" 10 "Button0" 9 "Button9_0or9" 8 "Button8" 7 "Button7_8or7" 6 "Button6" 5 "Button5_6or5" 4 "Button4" 3 "Button3_4or3" 2 "Button2" 1 "Button1_2or1" 0 "EndofString" ;
VAL_ 945 KeyPadCodeDgt3_D_Dsply 15 "NotUsed_4" 14 "NotUsed_3" 13 "NotUsed_2" 12 "NotUsed_1" 11 "Button7_8and9_0" 10 "Button0" 9 "Button9_0or9" 8 "Button8" 7 "Button7_8or7" 6 "Button6" 5 "Button5_6or5" 4 "Button4" 3 "Button3_4or3" 2 "Button2" 1 "Button1_2or1" 0 "EndofString" ;
VAL_ 945 KeyPadCodeDgt2_D_Dsply 15 "NotUsed_4" 14 "NotUsed_3" 13 "NotUsed_2" 12 "NotUsed_1" 11 "Button7_8and9_0" 10 "Button0" 9 "Button9_0or9" 8 "Button8" 7 "Button7_8or7" 6 "Button6" 5 "Button5_6or5" 4 "Button4" 3 "Button3_4or3" 2 "Button2" 1 "Button1_2or1" 0 "EndofString" ;
VAL_ 945 KeyPadCodeDgt1_D_Dsply 15 "NotUsed_4" 14 "NotUsed_3" 13 "NotUsed_2" 12 "NotUsed_1" 11 "Button7_8and9_0" 10 "Button0" 9 "Button9_0or9" 8 "Button8" 7 "Button7_8or7" 6 "Button6" 5 "Button5_6or5" 4 "Button4" 3 "Button3_4or3" 2 "Button2" 1 "Button1_2or1" 0 "EndofString" ;
VAL_ 945 KeyOffMde_D_Actl 15 "NotUsed_11" 14 "NotUsed_10" 13 "NotUsed_9" 12 "NotUsed_8" 11 "NotUsed_7" 10 "NotUsed_6" 9 "NotUsed_5" 8 "NotUsed_4" 7 "NotUsed_3" 6 "NotUsed_2" 5 "NotUsed_1" 4 "CriticalBattery" 3 "Hibernate" 2 "Transport" 1 "Factory" 0 "Normal" ;
VAL_ 945 PrkLckCtlLatch_B_Rq 1 "On" 0 "Off" ;
VAL_ 985 AdbDrvSide_B_Stat 1 "Left_Hand_Traffic" 0 "Right_Hand_Traffic" ;
VAL_ 985 LcwaMsgTxt_D_Stat 3 "SodXFaulty" 2 "SodXBlocked" 1 "TrailerConnected" 0 "NoMessage" ;
VAL_ 985 PwSustnAdas_B_Rq 1 "Active" 0 "Inactive" ;
VAL_ 985 AdbDividedRoad_B_Stat 1 "Yes" 0 "No" ;
VAL_ 985 LcwaAlrtRight_B_Rq 1 "Yes" 0 "No" ;
VAL_ 985 LcwaAlrtLeft_B_Rq 1 "Yes" 0 "No" ;
VAL_ 985 SblmPedCrossScnr_B_Stat 1 "Yes" 0 "No" ;
VAL_ 985 TsrRegionTxt_D_Stat 31 "Faulty" 30 "NotUsed_8" 29 "NotUsed_7" 28 "NotUsed_6" 27 "NotUsed_5" 26 "NotUsed_4" 25 "NotUsed_3" 24 "NotUsed_2" 23 "NotUsed_1" 22 "Region_22" 21 "Region_21" 20 "Region_20" 19 "Region_19" 18 "Region_18" 17 "Region_17" 16 "Region_16" 15 "Region_15" 14 "Region_14" 13 "Region_13" 12 "Region_12" 11 "Region_11" 10 "Region_10" 9 "Region_09" 8 "Region_08" 7 "Region_07" 6 "Region_06" 5 "Region_05" 4 "Region_04" 3 "Region_03" 2 "Region_02" 1 "Region_01" 0 "NotDetermined" ;
VAL_ 985 SblmYieldScnr_B_Stat 1 "Yes" 0 "No" ;
VAL_ 985 SblmStopScnr_B_Stat 1 "Yes" 0 "No" ;
VAL_ 985 AdbRampingV_D_Rq 3 "Slow" 2 "Medium" 1 "Fast" 0 "Immediately" ;
VAL_ 985 AdbLampOnOff_D_Rq 3 "BothOn" 2 "LeftOnRightOff" 1 "RightOnLeftOff" 0 "BothOff" ;
VAL_ 985 AdbHiBeamKeepOff_D_Rq 3 "KeepBothOff" 2 "KeepLeftOff" 1 "KeepRightOff" 0 "BothFreeRunning" ;
VAL_ 985 IaccVLimUnit_D_Rq 3 "NoDataExists" 2 "Mph" 1 "Kph" 0 "Null" ;
VAL_ 985 IaccVLim_D_Rq 252 "NotUsed_2" 250 "LimitSpeed_250" 240 "LimitSpeed_240" 230 "LimitSpeed_230" 220 "LimitSpeed_220" 210 "LimitSpeed_210" 200 "LimitSpeed_200" 190 "LimitSpeed_190" 150 "LimitSpeed_150" 140 "LimitSpeed_140" 130 "LimitSpeed_130" 120 "LimitSpeed_120" 110 "LimitSpeed_110" 100 "LimitSpeed_100" 90 "LimitSpeed_90" 80 "LimitSpeed_80" 70 "LimitSpeed_70" 60 "LimitSpeed_60" 50 "LimitSpeed_50" 40 "LimitSpeed_40" 30 "LimitSpeed_30" 20 "LimtSpeed_20" 251 "NotUsed_1" 255 "Faulty" 254 "NoDataExists" 253 "NotUsed_3" 180 "LimitSpeed_180" 179 "LimitSpeed_179" 178 "LimitSpeed_178" 177 "LimitSpeed_177" 176 "LimitSpeed_176" 175 "LimitSpeed_175" 174 "LimitSpeed_174" 173 "LimitSpeed_173" 172 "LimitSpeed_172" 171 "LimitSpeed_171" 170 "LimitSpeed_170" 169 "LimitSpeed_169" 168 "LimitSpeed_168" 167 "LimitSpeed_167" 166 "LimitSpeed_166" 165 "LimitSpeed_165" 164 "LimitSpeed_164" 163 "LimitSpeed_163" 162 "LimitSpeed_162" 161 "LimitSpeed_161" 160 "LimitSpeed_160" 15 "LimitSpeed_15" 14 "LimitSpeed_14" 13 "LimitSpeed_13" 12 "LimitSpeed_12" 11 "LimitSpeed_11" 10 "LimitSpeed_10" 9 "LimitSpeed_9" 8 "LimitSpeed_8" 7 "LimitSpeed_7" 6 "LimitSpeed_6" 5 "LimitSpeed_5" 4 "LimitSpeed_4" 3 "LimitSpeed_3" 2 "LimitSpeed_2" 1 "LimitSpeed_1" 0 "LimitSpeed_0" ;
VAL_ 985 IsaVLimUnit_D_Rq 3 "NoDataExists" 2 "Mph" 1 "Kph" 0 "Null" ;
VAL_ 985 IsaVLim_D_Rq 252 "NotUsed_2" 250 "LimitSpeed_250" 240 "LimitSpeed_240" 230 "LimitSpeed_230" 220 "LimitSpeed_220" 210 "LimitSpeed_210" 200 "LimitSpeed_200" 190 "LimitSpeed_190" 150 "LimitSpeed_150" 140 "LimitSpeed_140" 130 "LimitSpeed_130" 120 "LimitSpeed_120" 110 "LimitSpeed_110" 100 "LimitSpeed_100" 90 "LimitSpeed_90" 80 "LimitSpeed_80" 70 "LimitSpeed_70" 60 "LimitSpeed_60" 50 "LimitSpeed_50" 40 "LimitSpeed_40" 30 "LimitSpeed_30" 20 "LimtSpeed_20" 251 "NotUsed_1" 255 "Faulty" 254 "NoDataExists" 253 "NotUsed_3" 180 "LimitSpeed_180" 179 "LimitSpeed_179" 178 "LimitSpeed_178" 177 "LimitSpeed_177" 176 "LimitSpeed_176" 175 "LimitSpeed_175" 174 "LimitSpeed_174" 173 "LimitSpeed_173" 172 "LimitSpeed_172" 171 "LimitSpeed_171" 170 "LimitSpeed_170" 169 "LimitSpeed_169" 168 "LimitSpeed_168" 167 "LimitSpeed_167" 166 "LimitSpeed_166" 165 "LimitSpeed_165" 164 "LimitSpeed_164" 163 "LimitSpeed_163" 162 "LimitSpeed_162" 161 "LimitSpeed_161" 160 "LimitSpeed_160" 15 "LimitSpeed_15" 14 "LimitSpeed_14" 13 "LimitSpeed_13" 12 "LimitSpeed_12" 11 "LimitSpeed_11" 10 "LimitSpeed_10" 9 "LimitSpeed_9" 8 "LimitSpeed_8" 7 "LimitSpeed_7" 6 "LimitSpeed_6" 5 "LimitSpeed_5" 4 "LimitSpeed_4" 3 "LimitSpeed_3" 2 "LimitSpeed_2" 1 "LimitSpeed_1" 0 "LimitSpeed_0" ;
VAL_ 985 DasAlrtInfo_D_Dsply 3 "NotUsed" 2 "On" 1 "Off" 0 "Null" ;
VAL_ 985 LdwChime_B_Rq 1 "On" 0 "Off" ;
VAL_ 985 SblmRndAbtScnr_B_Stat 1 "Yes" 0 "No" ;
VAL_ 984 LaActvStats_D2_Dsply 31 "Unused7" 30 "LA_Off" 29 "ECE_OFF_RTT" 28 "Unused4" 27 "Unused3" 26 "Unused2" 25 "Unused1" 24 "InerveneLeft_InterveneRght" 23 "WarnLeft_InterveneRight" 22 "SuppressLeft_InterveneRght" 21 "AvailLeft_InterveneRhtt" 20 "NoLeft_InterveneRight" 19 "InterveneLeft_WarnRight" 18 "WarnLeft_WarnRight" 17 "SuppressLeft_WarnRight" 16 "AvailableLeft_WarnRight" 15 "NoLeft_WarnRight" 14 "InterveneLeft_SuppressRght" 13 "WarnLeft_SuppressRight" 12 "SuppressLeft_SuppressRight" 11 "AvailLeft_SuppressRight" 10 "NoLeft_SuppressRight" 9 "InterveneLeft_AvailRight" 8 "WarnLeft_AvailRight" 7 "SuppressLeft_AvailRight" 6 "AvailableLeft_AvailRight" 5 "NoLeft_AvailableRight" 4 "InterveneLeft_NoRight" 3 "WarnLeft_NoRight" 2 "SuppressLeft_NoRight" 1 "AvailableLeft_NoRight" 0 "NoLeft_NoRight" ;
VAL_ 984 AhbFeat_D_Stat 3 "ADB" 2 "GFHB" 1 "AHBC" 0 "None" ;
VAL_ 984 DsmcMsgTxt_D_Dsply 3 "Blockage" 2 "DriverNotSeen" 1 "Fault" 0 "NoMessage" ;
VAL_ 984 AhbcStat_B_Dsply 1 "On" 0 "Off" ;
VAL_ 984 AhbcRampingV_D_Rq 3 "Slow" 2 "Medium" 1 "Fast" 0 "Immediately" ;
VAL_ 984 AhbHiBeam_D_Rq 3 "NotUsed" 2 "HighBeamRecommended" 1 "LowBeamRecommended" 0 "DeactivatedUnavailable" ;
VAL_ 984 DasWarn_D_Dsply 3 "Undefined" 2 "Warning_Level_2" 1 "Warning_Level_1" 0 "No_Warning" ;
VAL_ 984 DasStats_D_Dsply 3 "Available" 2 "Unavailable_Other" 1 "Feedback_due_to_Speed" 0 "Off" ;
VAL_ 984 DasAlrtLvl_D_Dsply 5 "Alertness_Level_5" 4 "Alertness_Level_4" 3 "Alertness_Level_3" 2 "Alertness_Level_2" 1 "Alertness_Level_1" 0 "Undefined" ;
VAL_ 984 CamraStats_D_Dsply 3 "FrtCam_TempUnavailOther" 2 "FrtCam_TempUnavailVisibile" 1 "Front_Camera_Service_Reqd" 0 "Front_Camera_OK" ;
VAL_ 984 CamraDefog_B_Req 1 "On" 0 "Off" ;
VAL_ 984 LaHandsOff_D_Dsply 3 "Suppressed" 2 "Level2" 1 "Level1" 0 "HandsOn" ;
VAL_ 984 LaDenyStats_B_Dsply 1 "Unavailable" 0 "Available" ;
VAL_ 984 PersIndexIpma_D_Actl 7 "Unused_3" 6 "Unused_2" 5 "Unused_1" 4 "Vehicle" 3 "PERS_4" 2 "PERS_3" 1 "PERS_2" 0 "PERS_1" ;
VAL_ 1055 EcoCochInstNeg_B_Dsply 1 "True" 0 "False" ;
VAL_ 135 McGlblClkAdj_B_Rq 1 "Request" 0 "NoRequest" ;
VAL_ 134 DispGlblClkAdj_B_Rq 1 "Request" 0 "NoRequest" ;
VAL_ 836 Foh_D_Stat 7 "Unused3" 6 "Unused2" 5 "Unused1" 4 "Stopping" 3 "Running" 2 "Starting" 1 "Prestart" 0 "Off" ;
VAL_ 836 EngClnt_Te_ActlFoh 255 "Fault" ;
VAL_ 836 FohFalt_D_Stat 15 "NotUsed4" 14 "NotUsed3" 13 "NotUsed2" 12 "NotUsed1" 11 "FuelTypeDoesNotMatchFOH" 10 "Lifecycle_ModeNotSet" 9 "AuxElectricCoolantPumpInop" 8 "TimeDelayAvoidExcessCycl" 7 "Fuel_Level_OutofRange" 6 "External_Fault" 5 "Internal_Fault" 4 "Voltage_limitation" 3 "Impact_Event" 2 "CoolantTemp_OutofRange" 1 "AmbientTemp_OutofRange" 0 "No_Disable" ;
VAL_ 836 FohEnbl_B_RqDrv 1 "On" 0 "Off" ;
VAL_ 836 FohRqRun_B_Rq 1 "SubmitRequest_toRun" 0 "DoesNotSubmitRequest_toRun" ;
VAL_ 836 HvacPrecondMode_D_Rq 15 "NotUsed4" 14 "NotUsed3" 13 "NotUsed2" 12 "NotUsed1" 11 "Last_User_Settings" 10 "Auto" 9 "Max_Defrost" 8 "Windshield_Panel_Floor" 7 "Windshield_Panel" 6 "Windshield" 5 "Windshield_Floor" 4 "Floor" 3 "Panel_Floor" 2 "Panel" 1 "MAX_AC" 0 "Off" ;
VAL_ 836 HvacPrecondBlwr_D_Rq 15 "NotUsed6" 14 "NotUsed5" 13 "NotUsed4" 12 "NotUsed3" 11 "NotUsed2" 10 "NotUsed1" 9 "Last_User_Setting" 8 "Auto" 7 "Speed7" 6 "Speed6" 5 "Speed5" 4 "Speed4" 3 "Speed3" 2 "Speed2" 1 "Speed1" 0 "Off" ;
VAL_ 939 PrkAidSnsRlSide_D_Stat 15 "Zone_15" 14 "Zone_14" 13 "Zone_13" 12 "Zone_12" 11 "Zone_11" 10 "Zone_10" 9 "Zone_9" 8 "Zone_8" 7 "Zone_7" 6 "Zone_6" 5 "Zone_5" 4 "Zone_4" 3 "Zone_3" 2 "Zone_2" 1 "Zone_1" 0 "Off" ;
VAL_ 939 ApaBrk_D_Rq 3 "NotUsed" 2 "LowDecel" 1 "HighDecel" 0 "NoRequest" ;
VAL_ 939 SidePrkSnsR4_D_Stat 15 "NotUsed" 14 "NotFullyScannedYet" 13 "NoObjectInSector" 12 "Zone12" 11 "Zone11" 10 "Zone10" 9 "Zone9" 8 "Zone8" 7 "Zone7" 6 "Zone6" 5 "Zone5" 4 "Zone4" 3 "Zone3" 2 "Zone2" 1 "Zone1" 0 "Off" ;
VAL_ 939 SidePrkSnsR3_D_Stat 15 "NotUsed" 14 "NotFullyScannedYet" 13 "NoObjectInSector" 12 "Zone12" 11 "Zone11" 10 "Zone10" 9 "Zone9" 8 "Zone8" 7 "Zone7" 6 "Zone6" 5 "Zone5" 4 "Zone4" 3 "Zone3" 2 "Zone2" 1 "Zone1" 0 "Off" ;
VAL_ 939 SidePrkSnsL4_D_Stat 15 "NotUsed" 14 "NotFullyScannedYet" 13 "NoObjectInSector" 12 "Zone12" 11 "Zone11" 10 "Zone10" 9 "Zone9" 8 "Zone8" 7 "Zone7" 6 "Zone6" 5 "Zone5" 4 "Zone4" 3 "Zone3" 2 "Zone2" 1 "Zone1" 0 "Off" ;
VAL_ 939 SidePrkSnsL3_D_Stat 15 "NotUsed" 14 "NotFullyScannedYet" 13 "NoObjectInSector" 12 "Zone12" 11 "Zone11" 10 "Zone10" 9 "Zone9" 8 "Zone8" 7 "Zone7" 6 "Zone6" 5 "Zone5" 4 "Zone4" 3 "Zone3" 2 "Zone2" 1 "Zone1" 0 "Off" ;
VAL_ 939 PrkAidSnsRrSide_D_Stat 15 "Zone_15" 14 "Zone_14" 13 "Zone_13" 12 "Zone_12" 11 "Zone_11" 10 "Zone_10" 9 "Zone_9" 8 "Zone_8" 7 "Zone_7" 6 "Zone_6" 5 "Zone_5" 4 "Zone_4" 3 "Zone_3" 2 "Zone_2" 1 "Zone_1" 0 "Off" ;
VAL_ 939 PrkAidChime_D_Stat 3 "Fault" 2 "No_Data_Exists" 1 "On" 0 "Off" ;
VAL_ 939 PrkAidSnsRlCntr_D_Stat 15 "Zone_15" 14 "Zone_14" 13 "Zone_13" 12 "Zone_12" 11 "Zone_11" 10 "Zone_10" 9 "Zone_9" 8 "Zone_8" 7 "Zone_7" 6 "Zone_6" 5 "Zone_5" 4 "Zone_4" 3 "Zone_3" 2 "Zone_2" 1 "Zone_1" 0 "Off" ;
VAL_ 939 PrkAidSnsRrCrnr_D_Stat 15 "Zone_15" 14 "Zone_14" 13 "Zone_13" 12 "Zone_12" 11 "Zone_11" 10 "Zone_10" 9 "Zone_9" 8 "Zone_8" 7 "Zone_7" 6 "Zone_6" 5 "Zone_5" 4 "Zone_4" 3 "Zone_3" 2 "Zone_2" 1 "Zone_1" 0 "Off" ;
VAL_ 939 PrkAidSnsRrCntr_D_Stat 15 "Zone_15" 14 "Zone_14" 13 "Zone_13" 12 "Zone_12" 11 "Zone_11" 10 "Zone_10" 9 "Zone_9" 8 "Zone_8" 7 "Zone_7" 6 "Zone_6" 5 "Zone_5" 4 "Zone_4" 3 "Zone_3" 2 "Zone_2" 1 "Zone_1" 0 "Off" ;
VAL_ 939 PrkAidSnsRlCrnr_D_Stat 15 "Zone_15" 14 "Zone_14" 13 "Zone_13" 12 "Zone_12" 11 "Zone_11" 10 "Zone_10" 9 "Zone_9" 8 "Zone_8" 7 "Zone_7" 6 "Zone_6" 5 "Zone_5" 4 "Zone_4" 3 "Zone_3" 2 "Zone_2" 1 "Zone_1" 0 "Off" ;
VAL_ 939 PrkAidRear_D_Stat 3 "Faulted" 2 "Unused" 1 "Enabled" 0 "Disabled" ;
VAL_ 939 PrkAidFront_D_Stat 3 "Faulted" 2 "Unused" 1 "Enabled" 0 "Disabled" ;
VAL_ 939 PrkAid_D_Falt 7 "NotUsed2" 6 "NotUsed1" 5 "Failure_Front_PSM_Sensors" 4 "No_Data_Exists" 3 "Failure_Rear_Sensors" 2 "Speaker_Fault" 1 "ECU_Fault" 0 "No_Fault" ;
VAL_ 939 ApaLongCtrlEnbl_D_Rq 1 "Enable" 0 "Disable" ;
VAL_ 939 PrkAidLamp_D_Rq 3 "Not_Used" 2 "Flash" 1 "On" 0 "Off" ;
VAL_ 952 Tire_Press_IRR_Data 65535 "Not_Supported" 65534 "Invalid" 65533 "Unknown" ;
VAL_ 952 Tire_Press_ILR_Data 65535 "Not_Supported" 65534 "Invalid" 65533 "Unknown" ;
VAL_ 374 GearEngag_D_Actl 7 "Undefined" 6 "Fwd_Clutch_Fully_Engaged" 5 "Neutral_Idle" 4 "Disengaged_to_Neutral_Idle" 3 "Disengaged_to_Neutral_Park" 2 "Engagement_in_Progress" 1 "InitializeFwdClutchEngagmt" 0 "Park_Neutral" ;
VAL_ 374 TrnRng_D_Rq 15 "Fault" 14 "Unknown_Position" 13 "NotUsed_2" 12 "NotUsed_1" 11 "Range6" 10 "Range5" 9 "Range4" 8 "Range3_M3_L3" 7 "Range2_M2_L2" 6 "Range1_M1_L1" 5 "Low" 4 "Sport_DriveSport_Mposition" 3 "Drive" 2 "Neutral" 1 "Reverse" 0 "Park" ;
VAL_ 374 TrnPrkSys_D_Actl 15 "Faulty" 14 "NotUsed_5" 13 "NotUsed_4" 12 "NotUsed_3" 11 "NotUsed_2" 10 "NotUsed_1" 9 "FrequencyError" 8 "OutOfRangeHigh" 7 "OutOfRangeLow" 6 "Override" 5 "OutOfPark" 4 "TransitionCloseToOutOfPark" 3 "AtNoSpring" 2 "TransitionCloseToPark" 1 "Park" 0 "NotKnown" ;
VAL_ 374 GearLvr_D_ActlDrv 15 "Fault" 14 "Unknown_Position" 13 "NotUsed_2" 12 "NotUsed_1" 11 "Range6" 10 "Range5" 9 "Range4" 8 "Range3_M3_L3" 7 "Range2_M2_L2" 6 "Range1_M1_L1" 5 "Low" 4 "Sport_DriveSport_Mposition" 3 "Drive" 2 "Neutral" 1 "Reverse" 0 "Park" ;
VAL_ 374 GearPos_D_Trg 15 "Unknown" 14 "Reverse" 13 "Undefined_5" 12 "Undefined_4" 11 "Undefined_3" 10 "Tenth" 9 "Ninth" 8 "Eighth" 7 "Seventh" 6 "Sixth" 5 "Fifth" 4 "Fourth" 3 "Third" 2 "Second" 1 "First" 0 "Neutral" ;
VAL_ 374 GearPos_D_Actl 15 "Unknown" 14 "Reverse" 13 "Undefined_5" 12 "Undefined_4" 11 "Undefined_3" 10 "Tenth" 9 "Ninth" 8 "Eighth" 7 "Seventh" 6 "Sixth" 5 "Fifth" 4 "Fourth" 3 "Third" 2 "Second" 1 "First" 0 "Neutral" ;
VAL_ 1095 Pers4Phone_D_Stat 7 "SevenPhoneAssociated" 6 "SixPhoneAssociated" 5 "FivePhoneAssociated" 4 "FourPhoneAssociated" 3 "ThreePhoneAssociated" 2 "TwoPhoneAssociated" 1 "OnePhoneAssociated" 0 "NoPhoneAssociated" ;
VAL_ 1095 Pers3Phone_D_Stat 7 "SevenPhoneAssociated" 6 "SixPhoneAssociated" 5 "FivePhoneAssociated" 4 "FourPhoneAssociated" 3 "ThreePhoneAssociated" 2 "TwoPhoneAssociated" 1 "OnePhoneAssociated" 0 "NoPhoneAssociated" ;
VAL_ 1095 Pers2Phone_D_Stat 7 "SevenPhoneAssociated" 6 "SixPhoneAssociated" 5 "FivePhoneAssociated" 4 "FourPhoneAssociated" 3 "ThreePhoneAssociated" 2 "TwoPhoneAssociated" 1 "OnePhoneAssociated" 0 "NoPhoneAssociated" ;
VAL_ 1095 Pers1Phone_D_Stat 7 "SevenPhoneAssociated" 6 "SixPhoneAssociated" 5 "FivePhoneAssociated" 4 "FourPhoneAssociated" 3 "ThreePhoneAssociated" 2 "TwoPhoneAssociated" 1 "OnePhoneAssociated" 0 "NoPhoneAssociated" ;
VAL_ 1095 HeadLghtOn_D_Rq 7 "NotUsed2" 6 "NotUsed1" 5 "DrlBoth" 4 "DrlRight" 3 "DrlLeft" 2 "High" 1 "Low" 0 "Off" ;
VAL_ 1095 PepsKeyActv_D_Stat 15 "NotUsed11" 14 "NotUsed10" 13 "NotUsed9" 12 "NotUsed8" 11 "NotUsed7" 10 "NotUsed6" 9 "NotUsed5" 8 "Key4Active" 7 "NotUsed4" 6 "NotUsed3" 5 "NotUsed2" 4 "Key3Active" 3 "NotUsed1" 2 "Key2Active" 1 "Key1Active" 0 "NoKeyActive" ;
VAL_ 1095 VehLck_D_Dsply 3 "Faulty" 2 "Unlock" 1 "Lock" 0 "Off" ;
VAL_ 1094 CellRstrt_D_Rq 3 "NotUsed" 2 "RemoteCancel" 1 "RemoteStart" 0 "NoRequest" ;
VAL_ 1094 CellPanic_D_Rq 3 "NotUsed" 2 "On" 1 "Off" 0 "Null" ;
VAL_ 1094 CellLock_D_Rq 7 "BEC_Enable" 6 "Cargo_Unlock" 5 "Cabin_Unlock" 4 "TrunkRelPopGlassLgCargo" 3 "LockAllDoorsandTailgate" 2 "UnlockDriversDoor" 1 "UnlockAllDoorsandTailgate" 0 "NoRequest" ;
VAL_ 1094 CellChirp_D_Rq 7 "NotUsed3" 6 "NotUsed2" 5 "NotUsed1" 4 "Honk" 3 "ChirpHonk" 2 "Chirp2" 1 "Chirp1" 0 "NoRequest" ;
VAL_ 1100 RearDiffLckLamp_D_Rq2 3 "Triggered" 2 "Flash" 1 "On" 0 "Off" ;
VAL_ 1100 RvltnMatchAllw_D_Stat 3 "RevolutionMatchDisabled" 2 "RevolutionMatchEnabled" 1 "ChangeWithDriveMode" 0 "NoSelection" ;
VAL_ 1100 WakeAlarm1_B_Typ 1 "CanAndEcuDriveCircuit" 0 "CanOnly" ;
VAL_ 1100 TrnNtrlIdlExit_B_Rq 1 "Active" 0 "Inactive" ;
VAL_ 1100 HvacCmprLim_D_Stat 7 "NotUsed_2" 6 "NotUsed_1" 5 "CompressorHeadPressure" 4 "AvailableTorque" 3 "PedalPosition" 2 "RPM" 1 "ECT" 0 "NoLimit" ;
VAL_ 1100 Veh_V_DsplyTrailCtlSet 63 "Faulty" ;
VAL_ 1100 TrailCtlPt_B_Falt 1 "Fault" 0 "No_Fault" ;
VAL_ 1100 TrnNtrlIdlInhbt_B_Rq 1 "Inhibit" 0 "NoInhibit" ;
VAL_ 1100 AutoTowAllw_D_StatMnu 3 "TowHaulCommandedOn" 2 "AutoTowHaulEnabled" 1 "AutoTowHaulDisabled" 0 "NoSelection" ;
VAL_ 1100 AutoTowActv_B_Stat 1 "Yes" 0 "No" ;
VAL_ 1100 SpareTireDetct_B_Stat 1 "True" 0 "False" ;
VAL_ 1100 RearDiffSumpOil_Te_Est 255 "Faulty" 254 "NoDataExists" ;
VAL_ 1100 RearDiffMtrRun_B_Stat 1 "Allowed" 0 "NotAllowed" ;
VAL_ 1100 EngTrlrCnnct_D_Stat 3 "NotUsed_1" 2 "UnverifiedTrailer" 1 "HeavyTrailer" 0 "NoTrailer" ;
VAL_ 1100 GrossTrainWeight_M_Est 255 "Faulty" 254 "NoDataExists" ;
VAL_ 1100 SuspVlimMsgTxt_B_Rq 1 "Yes" 0 "No" ;
VAL_ 1100 RearDiffLckMsg2_D_Rq 15 "NotUsed_3" 14 "NotUsed_2" 13 "NotUsed_1" 12 "ElsdReduced" 11 "LockingFeatureNotAvailable" 10 "EsldOff" 9 "ElsdRestored" 8 "ElsdOverheated" 7 "Locker_Disabled" 6 "Locker_Enabled" 5 "LockerSpeed5" 4 "LockerSpeed4" 3 "LockerSpeed3" 2 "LockerSpeed2" 1 "LockerSpeed1" 0 "NormalNoMessage " ;
VAL_ 1100 EngExhMdeQuiet_D2_Stat 7 "Faulty" 6 "NotUsed_2" 5 "NotUsed_1" 4 "Track" 3 "Sport" 2 "Normal" 1 "Stealth" 0 "Null" ;
VAL_ 993 StmsScrnDrvOn_B_Rq 1 "On" 0 "Off" ;
VAL_ 993 EmButtn_D_Stat 7 "ButtonAssociationFailed" 6 "ButtonAssociationExited" 5 "ButtonAssociationEntered" 4 "Button4Pressed" 3 "Button3Pressed" 2 "Button2Pressed" 1 "Button1Pressed" 0 "Null" ;
VAL_ 993 MemStoreMsgTxt_D_Rq 10 "NotUsed_2" 9 "NotUsed_1" 8 "Mem4Saved_ShowLinkMsg" 7 "Mem3Saved_ShowLinkMsg" 6 "Mem2Saved_ShowLinkMsg" 5 "Mem1Saved_ShowLinkMsg" 4 "Mem4Saved_DoNotShowLinkMsg" 3 "Mem3Saved_DoNotShowLinkMsg" 2 "Mem2Saved_DoNotShowLinkMsg" 1 "Mem1Saved_DoNotShowLinkMsg" 0 "Null" ;
VAL_ 993 MemSetButtnMsgTxt_D_Rq 3 "NotUsed" 2 "Press1or2or3" 1 "Press1or2" 0 "Null" ;
VAL_ 993 PersStore_D_Actl 3 "Unused" 2 "Null" 1 "InProgress" 0 "Complete" ;
VAL_ 993 MemSwtch_D_RqRecall 7 "Unused_3" 6 "Unused_2" 5 "Unused_1" 4 "PERS_4" 3 "PERS_3" 2 "PERS_2" 1 "PERS_1" 0 "Null" ;
VAL_ 993 MemSwtch_D_RqAssoc 7 "Unused_3" 6 "Unused_2" 5 "Unused_1" 4 "PERS_4" 3 "PERS_3" 2 "PERS_2" 1 "PERS_1" 0 "Null" ;
VAL_ 993 PersIndexDsm_D_Actl 7 "Unused_3" 6 "Unused_2" 5 "Unused_1" 4 "Vehicle" 3 "PERS_4" 2 "PERS_3" 1 "PERS_2" 0 "PERS_1" ;
VAL_ 131 AhbStat_B_Dsply 1 "On" 0 "Off" ;
VAL_ 131 HeadLghtHiOn_B_StatAhb 1 "On" 0 "Off" ;
VAL_ 131 WiprFrontSwtch_D_Stat 15 "NotUsed6" 14 "NotUsed5" 13 "NotUsed4" 12 "NotUsed3" 11 "NotUsed2" 10 "NotUsed1" 9 "PositionNotDetermined" 8 "High" 7 "Low" 6 "Position6" 5 "Position5" 4 "Position4" 3 "Position3" 2 "Position2" 1 "Position1" 0 "Off" ;
VAL_ 131 HeadLghtHiCtrl_D_RqAhb 7 "NotUsed2" 6 "NotUsed1" 5 "Auto_HiBeam" 4 "Auto_LoBeam" 3 "Flash" 2 "Man_HiBeam" 1 "Man_LoBeam" 0 "Null" ;
VAL_ 131 HeadLghtHiFlash_D_Actl 3 "NotUsed" 2 "High" 1 "Flash_to_Pass" 0 "Null" ;
VAL_ 131 AccButtnGapTogglePress 1 "Pressed" 0 "Not_Pressed" ;
VAL_ 131 TjaButtnOnOffPress 1 "Pressed" 0 "Not_Pressed" ;
VAL_ 131 AccButtnGapIncPress 1 "Button_Pressed" 0 "Button_Not_Pressed" ;
VAL_ 131 AccButtnGapDecPress 1 "Button_Pressed" 0 "Button_Not_Pressed" ;
VAL_ 131 AslButtnOnOffPress 1 "Button_Pressed" 0 "Button_Not_Pressed" ;
VAL_ 131 AslButtnOnOffCnclPress 1 "Button_Pressed" 0 "Button_Not_Pressed" ;
VAL_ 131 CcButtnOnPress 1 "Button_Pressed" 0 "Button_Not_Pressed" ;
VAL_ 131 CcButtnOnOffPress 1 "Button_Pressed" 0 "Button_Not_Pressed" ;
VAL_ 131 CcButtnOnOffCnclPress 1 "Button_Pressed" 0 "Button_Not_Pressed" ;
VAL_ 131 CcButtnOffPress 1 "Button_Pressed" 0 "Button_Not_Pressed" ;
VAL_ 131 CcAsllButtnResPress 1 "Button_Pressed" 0 "Button_Not_Pressed" ;
VAL_ 131 CcAslButtnSetPress 1 "Button_Pressed" 0 "Button_Not_Pressed" ;
VAL_ 131 CcAslButtnSetIncPress 1 "Button_Pressed" 0 "Button_Not_Pressed" ;
VAL_ 131 CcAslButtnSetDecPress 1 "Button_Pressed" 0 "Button_Not_Pressed" ;
VAL_ 131 CcAslButtnResIncPress 1 "Button_Pressed" 0 "Button_Not_Pressed" ;
VAL_ 131 CcAslButtnResDecPress 1 "Button_Pressed" 0 "Button_Not_Pressed" ;
VAL_ 131 CcAslButtnOnPress 1 "Button_Pressed" 0 "Button_Not_Pressed" ;
VAL_ 131 CcAslButtnOnOffCncl 1 "Button_Pressed" 0 "Button_Not_Pressed" ;
VAL_ 131 CcAslButtnOffCnclPress 1 "Button_Pressed" 0 "Button_Not_Pressed" ;
VAL_ 131 CcAslButtnIndxIncPress 1 "Button_Pressed" 0 "Button_Not_Pressed" ;
VAL_ 131 CcAslButtnIndxDecPress 1 "Button_Pressed" 0 "Button_Not_Pressed" ;
VAL_ 131 CcAslButtnDeny_B_Actl 1 "Yes" 0 "No" ;
VAL_ 131 CcAslButtnCnclResPress 1 "Button_Pressed" 0 "Button_Not_Pressed" ;
VAL_ 131 CcAslButtnCnclPress 1 "Button_Pressed" 0 "Button_Not_Pressed" ;
VAL_ 131 HeadLghtHiFlash_D_Stat 3 "NotUsed" 2 "High" 1 "Flash_to_Pass" 0 "Null" ;
VAL_ 131 WiprFront_D_Stat 15 "NO_DATA_EXISTS" 14 "STALLED" 13 "RESERVED" 12 "AUTO_ADJUST" 11 "COURTESYWIPE" 10 "AUTO_HIGH" 9 "AUTO_LOW" 8 "WASH" 7 "MIST_FLICK" 6 "MAN_HIGH" 5 "MAN_LOW" 4 "MAN_INT_ON" 3 "MAN_INT_OFF" 2 "OFF_MOVING" 1 "AUTO_OFF" 0 "OFF" ;
VAL_ 131 TurnLghtSwtch_D_Stat 3 "Unused_Treat_As_Off" 2 "Right" 1 "Left" 0 "Off" ;
VAL_ 131 LghtAmb_D_Sns 7 "No_Data_Exists" 6 "Unused2" 5 "Unused1" 4 "Tunnel_Off" 3 "Tunnel_On" 2 "Twilight" 1 "Light" 0 "Dark" ;
VAL_ 131 LaSwtchPos_D_Stat 3 "Fault" 2 "Unused" 1 "Pressed" 0 "Open" ;
VAL_ 819 WndwUpPsngrRear_D_Falt 3 "NotUsed" 2 "Fault" 1 "NoFault" 0 "Null" ;
VAL_ 819 WndwUpPsngrFront_D_Falt 3 "NotUsed" 2 "Fault" 1 "NoFault" 0 "Null" ;
VAL_ 819 DrPrsntPsngr_D_Stat 3 "Faulty" 2 "Present" 1 "NotPresent" 0 "NotDetermined" ;
VAL_ 819 DrPsngrMsgTxt_B_Rq 1 "Yes" 0 "No" ;
VAL_ 819 DrPrsntRearPsngr_D_Stat 3 "Faulty" 2 "Present" 1 "NotPresent" 0 "NotDetermined" ;
VAL_ 819 WndwPsngrSide_D_Stat 3 "BothWindow_Operating" 2 "RearWindow_Operating" 1 "FrontWindow_Operating" 0 "NoWindows_Operating" ;
VAL_ 819 Memory_3_SwPsngr_Stat 1 "Pressed" 0 "Null" ;
VAL_ 819 Memory_2_SwPsngr_Stat 1 "Pressed" 0 "Null" ;
VAL_ 819 Memory_1_SwPsngr_Stat 1 "Pressed" 0 "Null" ;
VAL_ 819 BLISLEDStatPassSide 3 "Fault" 2 "Unused" 1 "On" 0 "Off" ;
VAL_ 819 Pasngr_Lock_Sw_Stat 3 "Invalid" 2 "Unlock" 1 "Lock" 0 "Null" ;
VAL_ 819 ChildLckFdbckRp_B_Stat 1 "Locked" 0 "Unlock" ;
